VERSION "eCMP INFO-DIV vehicle review 2026-11-03; 125000 bit/s; PSA-RE 67f7581e7622410efdbb29c7eda3b86982b9b450; Apache-2.0"

NS_ :

BS_:

BU_: AAS AMPLI AVP BCM BGP BSG BSI BTA BTEL BTT CDC CMB CRT DIAG_TOOL EDP_C EMF FMUX IC ICSV IDVR IVC_D MATT MDS OVIP PDS_C RAD RBG SDCM VTH WLC

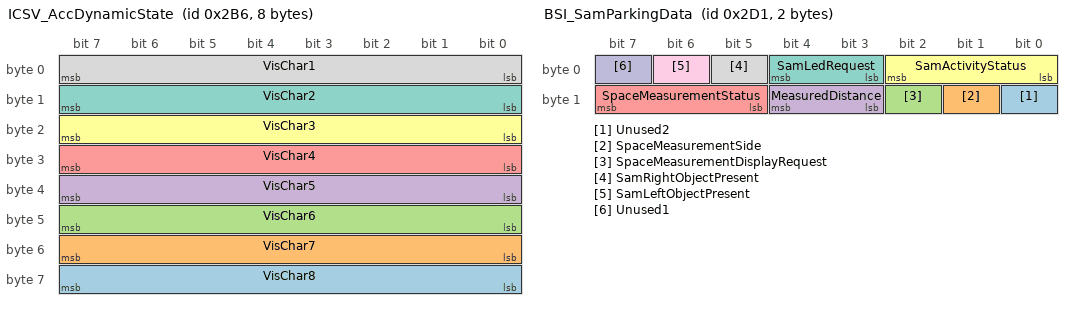
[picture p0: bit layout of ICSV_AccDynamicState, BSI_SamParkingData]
BO_ 694 ICSV_AccDynamicState: 8 ICSV
 SG_ VisChar8 : 63|8@0+ (1,0) [0|255] "raw"  BTEL,EMF,RAD,MDS,BGP,OVIP
 SG_ VisChar7 : 55|8@0+ (1,0) [0|255] "raw"  BTEL,EMF,RAD,MDS,BGP,OVIP
 SG_ VisChar6 : 47|8@0+ (1,0) [0|255] "raw"  BTEL,EMF,RAD,MDS,BGP,OVIP
 SG_ VisChar5 : 39|8@0+ (1,0) [0|255] "raw"  BTEL,EMF,RAD,MDS,BGP,OVIP
 SG_ VisChar4 : 31|8@0+ (1,0) [0|255] "raw"  BTEL,EMF,RAD,MDS,BGP,OVIP
 SG_ VisChar3 : 23|8@0+ (1,0) [0|255] "raw"  BTEL,EMF,RAD,MDS,BGP,OVIP
 SG_ VisChar2 : 15|8@0+ (1,0) [0|255] "raw"  BTEL,EMF,RAD,MDS,BGP,OVIP
 SG_ VisChar1 : 7|8@0+ (1,0) [0|255] "raw"  BTEL,EMF,RAD,MDS,BGP,OVIP

BO_ 705 BSI_UidTableEncryptedToBs_a09225: 8 BSI
 SG_ FlowPadding5 m3 : 63|8@0+ (1,0) [0|255] "raw"  SDCM
 SG_ FirstData6 m1 : 63|8@0+ (1,0) [0|255] "raw"  SDCM
 SG_ UnknownData7 m4 : 63|8@0+ (1,0) [0|255] "raw"  SDCM
 SG_ ConsecutiveData7 m2 : 63|8@0+ (1,0) [0|255] "raw"  SDCM
 SG_ SingleData7 m0 : 63|8@0+ (1,0) [0|255] "raw"  SDCM
 SG_ FlowPadding4 m3 : 55|8@0+ (1,0) [0|255] "raw"  SDCM
 SG_ FirstData5 m1 : 55|8@0+ (1,0) [0|255] "raw"  SDCM
 SG_ UnknownData6 m4 : 55|8@0+ (1,0) [0|255] "raw"  SDCM
 SG_ ConsecutiveData6 m2 : 55|8@0+ (1,0) [0|255] "raw"  SDCM
 SG_ SingleData6 m0 : 55|8@0+ (1,0) [0|255] "raw"  SDCM
 SG_ FlowPadding3 m3 : 47|8@0+ (1,0) [0|255] "raw"  SDCM
 SG_ FirstData4 m1 : 47|8@0+ (1,0) [0|255] "raw"  SDCM
 SG_ UnknownData5 m4 : 47|8@0+ (1,0) [0|255] "raw"  SDCM
 SG_ ConsecutiveData5 m2 : 47|8@0+ (1,0) [0|255] "raw"  SDCM
 SG_ SingleData5 m0 : 47|8@0+ (1,0) [0|255] "raw"  SDCM
 SG_ FlowPadding2 m3 : 39|8@0+ (1,0) [0|255] "raw"  SDCM
 SG_ FirstData3 m1 : 39|8@0+ (1,0) [0|255] "raw"  SDCM
 SG_ UnknownData4 m4 : 39|8@0+ (1,0) [0|255] "raw"  SDCM
 SG_ ConsecutiveData4 m2 : 39|8@0+ (1,0) [0|255] "raw"  SDCM
 SG_ SingleData4 m0 : 39|8@0+ (1,0) [0|255] "raw"  SDCM
 SG_ FlowPadding1 m3 : 31|8@0+ (1,0) [0|255] "raw"  SDCM
 SG_ FirstData2 m1 : 31|8@0+ (1,0) [0|255] "raw"  SDCM
 SG_ UnknownData3 m4 : 31|8@0+ (1,0) [0|255] "raw"  SDCM
 SG_ ConsecutiveData3 m2 : 31|8@0+ (1,0) [0|255] "raw"  SDCM
 SG_ SingleData3 m0 : 31|8@0+ (1,0) [0|255] "raw"  SDCM
 SG_ FirstData1 m1 : 23|8@0+ (1,0) [0|255] "raw"  SDCM
 SG_ UnknownData2 m4 : 23|8@0+ (1,0) [0|255] "raw"  SDCM
 SG_ ConsecutiveData2 m2 : 23|8@0+ (1,0) [0|255] "raw"  SDCM
 SG_ SingleData2 m0 : 23|8@0+ (1,0) [0|255] "raw"  SDCM
 SG_ SeparationTimeRaw m3 : 23|8@0+ (1,0) [0|255] "raw"  SDCM
 SG_ UnknownData1 m4 : 15|8@0+ (1,0) [0|255] "raw"  SDCM
 SG_ ConsecutiveData1 m2 : 15|8@0+ (1,0) [0|255] "raw"  SDCM
 SG_ SingleData1 m0 : 15|8@0+ (1,0) [0|255] "raw"  SDCM
 SG_ BlockSize m3 : 15|8@0+ (1,0) [0|255] "raw"  SDCM
 SG_ UnknownPciLow m4 : 3|4@0+ (1,0) [0|15] "raw"  SDCM
 SG_ FlowStatus m3 : 3|4@0+ (1,0) [0|15] "raw"  SDCM
 SG_ ConsecutiveSequence m2 : 3|4@0+ (1,0) [0|15] "raw"  SDCM
 SG_ FirstFrameLength m1 : 3|12@0+ (1,0) [0|4095] "raw"  SDCM
 SG_ SingleFrameLength m0 : 3|4@0+ (1,0) [0|15] "raw"  SDCM
 SG_ IsoTpFrameType M : 7|4@0+ (1,0) [0|15] ""  SDCM

BO_ 707 BTEL_OdiBufferToTelematics: 8 BTEL
 SG_ OdiCenterstackToTelematicsBuffer : 7|64@0+ (1,0) [0|18446744073709551615] ""  MDS

BO_ 709 OVIP_DashcamListFlowControl: 8 OVIP
 SG_ FlowPadding5 m3 : 63|8@0+ (1,0) [0|255] "raw"  IDVR
 SG_ FirstData6 m1 : 63|8@0+ (1,0) [0|255] "raw"  IDVR
 SG_ UnknownData7 m4 : 63|8@0+ (1,0) [0|255] "raw"  IDVR
 SG_ ConsecutiveData7 m2 : 63|8@0+ (1,0) [0|255] "raw"  IDVR
 SG_ SingleData7 m0 : 63|8@0+ (1,0) [0|255] "raw"  IDVR
 SG_ FlowPadding4 m3 : 55|8@0+ (1,0) [0|255] "raw"  IDVR
 SG_ FirstData5 m1 : 55|8@0+ (1,0) [0|255] "raw"  IDVR
 SG_ UnknownData6 m4 : 55|8@0+ (1,0) [0|255] "raw"  IDVR
 SG_ ConsecutiveData6 m2 : 55|8@0+ (1,0) [0|255] "raw"  IDVR
 SG_ SingleData6 m0 : 55|8@0+ (1,0) [0|255] "raw"  IDVR
 SG_ FlowPadding3 m3 : 47|8@0+ (1,0) [0|255] "raw"  IDVR
 SG_ FirstData4 m1 : 47|8@0+ (1,0) [0|255] "raw"  IDVR
 SG_ UnknownData5 m4 : 47|8@0+ (1,0) [0|255] "raw"  IDVR
 SG_ ConsecutiveData5 m2 : 47|8@0+ (1,0) [0|255] "raw"  IDVR
 SG_ SingleData5 m0 : 47|8@0+ (1,0) [0|255] "raw"  IDVR
 SG_ FlowPadding2 m3 : 39|8@0+ (1,0) [0|255] "raw"  IDVR
 SG_ FirstData3 m1 : 39|8@0+ (1,0) [0|255] "raw"  IDVR
 SG_ UnknownData4 m4 : 39|8@0+ (1,0) [0|255] "raw"  IDVR
 SG_ ConsecutiveData4 m2 : 39|8@0+ (1,0) [0|255] "raw"  IDVR
 SG_ SingleData4 m0 : 39|8@0+ (1,0) [0|255] "raw"  IDVR
 SG_ FlowPadding1 m3 : 31|8@0+ (1,0) [0|255] "raw"  IDVR
 SG_ FirstData2 m1 : 31|8@0+ (1,0) [0|255] "raw"  IDVR
 SG_ UnknownData3 m4 : 31|8@0+ (1,0) [0|255] "raw"  IDVR
 SG_ ConsecutiveData3 m2 : 31|8@0+ (1,0) [0|255] "raw"  IDVR
 SG_ SingleData3 m0 : 31|8@0+ (1,0) [0|255] "raw"  IDVR
 SG_ FirstData1 m1 : 23|8@0+ (1,0) [0|255] "raw"  IDVR
 SG_ UnknownData2 m4 : 23|8@0+ (1,0) [0|255] "raw"  IDVR
 SG_ ConsecutiveData2 m2 : 23|8@0+ (1,0) [0|255] "raw"  IDVR
 SG_ SingleData2 m0 : 23|8@0+ (1,0) [0|255] "raw"  IDVR
 SG_ SeparationTimeRaw m3 : 23|8@0+ (1,0) [0|255] "raw"  IDVR
 SG_ UnknownData1 m4 : 15|8@0+ (1,0) [0|255] "raw"  IDVR
 SG_ ConsecutiveData1 m2 : 15|8@0+ (1,0) [0|255] "raw"  IDVR
 SG_ SingleData1 m0 : 15|8@0+ (1,0) [0|255] "raw"  IDVR
 SG_ BlockSize m3 : 15|8@0+ (1,0) [0|255] "raw"  IDVR
 SG_ UnknownPciLow m4 : 3|4@0+ (1,0) [0|15] "raw"  IDVR
 SG_ FlowStatus m3 : 3|4@0+ (1,0) [0|15] "raw"  IDVR
 SG_ ConsecutiveSequence m2 : 3|4@0+ (1,0) [0|15] "raw"  IDVR
 SG_ FirstFrameLength m1 : 3|12@0+ (1,0) [0|4095] "raw"  IDVR
 SG_ SingleFrameLength m0 : 3|4@0+ (1,0) [0|15] "raw"  IDVR
 SG_ IsoTpFrameType M : 7|4@0+ (1,0) [0|15] ""  IDVR

BO_ 721 BSI_SamParkingData: 2 BSI
 SG_ Unused2 : 8|1@0+ (1,0) [0|1] ""  AAS,MDS
 SG_ SpaceMeasurementSide : 9|1@0+ (1,0) [0|1] ""  AAS,MDS
 SG_ SpaceMeasurementDisplayRequest : 10|1@0+ (1,0) [0|1] ""  AAS,MDS
 SG_ MeasuredDistance : 12|2@0+ (1,0) [0|3] ""  AAS,MDS
 SG_ SpaceMeasurementStatus : 15|3@0+ (1,0) [0|7] ""  AAS,MDS
 SG_ SamActivityStatus : 2|3@0+ (1,0) [0|7] ""  AAS,MDS
 SG_ SamLedRequest : 4|2@0+ (1,0) [0|3] ""  AAS,MDS
 SG_ SamRightObjectPresent : 5|1@0+ (1,0) [0|1] ""  AAS,MDS
 SG_ SamLeftObjectPresent : 6|1@0+ (1,0) [0|1] ""  AAS,MDS
 SG_ Unused1 : 7|1@0+ (1,0) [0|1] ""  AAS,MDS

BO_ 724 BSI_RemoteActionMonitoringStatus: 8 BSI
 SG_ FlowPadding5 m3 : 63|8@0+ (1,0) [0|255] "raw"  MDS
 SG_ FirstData6 m1 : 63|8@0+ (1,0) [0|255] "raw"  MDS
 SG_ UnknownData7 m4 : 63|8@0+ (1,0) [0|255] "raw"  MDS
 SG_ ConsecutiveData7 m2 : 63|8@0+ (1,0) [0|255] "raw"  MDS
 SG_ SingleData7 m0 : 63|8@0+ (1,0) [0|255] "raw"  MDS
 SG_ FlowPadding4 m3 : 55|8@0+ (1,0) [0|255] "raw"  MDS
 SG_ FirstData5 m1 : 55|8@0+ (1,0) [0|255] "raw"  MDS
 SG_ UnknownData6 m4 : 55|8@0+ (1,0) [0|255] "raw"  MDS
 SG_ ConsecutiveData6 m2 : 55|8@0+ (1,0) [0|255] "raw"  MDS
 SG_ SingleData6 m0 : 55|8@0+ (1,0) [0|255] "raw"  MDS
 SG_ FlowPadding3 m3 : 47|8@0+ (1,0) [0|255] "raw"  MDS
 SG_ FirstData4 m1 : 47|8@0+ (1,0) [0|255] "raw"  MDS
 SG_ UnknownData5 m4 : 47|8@0+ (1,0) [0|255] "raw"  MDS
 SG_ ConsecutiveData5 m2 : 47|8@0+ (1,0) [0|255] "raw"  MDS
 SG_ SingleData5 m0 : 47|8@0+ (1,0) [0|255] "raw"  MDS
 SG_ FlowPadding2 m3 : 39|8@0+ (1,0) [0|255] "raw"  MDS
 SG_ FirstData3 m1 : 39|8@0+ (1,0) [0|255] "raw"  MDS
 SG_ UnknownData4 m4 : 39|8@0+ (1,0) [0|255] "raw"  MDS
 SG_ ConsecutiveData4 m2 : 39|8@0+ (1,0) [0|255] "raw"  MDS
 SG_ SingleData4 m0 : 39|8@0+ (1,0) [0|255] "raw"  MDS
 SG_ FlowPadding1 m3 : 31|8@0+ (1,0) [0|255] "raw"  MDS
 SG_ FirstData2 m1 : 31|8@0+ (1,0) [0|255] "raw"  MDS
 SG_ UnknownData3 m4 : 31|8@0+ (1,0) [0|255] "raw"  MDS
 SG_ ConsecutiveData3 m2 : 31|8@0+ (1,0) [0|255] "raw"  MDS
 SG_ SingleData3 m0 : 31|8@0+ (1,0) [0|255] "raw"  MDS
 SG_ FirstData1 m1 : 23|8@0+ (1,0) [0|255] "raw"  MDS
 SG_ UnknownData2 m4 : 23|8@0+ (1,0) [0|255] "raw"  MDS
 SG_ ConsecutiveData2 m2 : 23|8@0+ (1,0) [0|255] "raw"  MDS
 SG_ SingleData2 m0 : 23|8@0+ (1,0) [0|255] "raw"  MDS
 SG_ SeparationTimeRaw m3 : 23|8@0+ (1,0) [0|255] "raw"  MDS
 SG_ UnknownData1 m4 : 15|8@0+ (1,0) [0|255] "raw"  MDS
 SG_ ConsecutiveData1 m2 : 15|8@0+ (1,0) [0|255] "raw"  MDS
 SG_ SingleData1 m0 : 15|8@0+ (1,0) [0|255] "raw"  MDS
 SG_ BlockSize m3 : 15|8@0+ (1,0) [0|255] "raw"  MDS
 SG_ UnknownPciLow m4 : 3|4@0+ (1,0) [0|15] "raw"  MDS
 SG_ FlowStatus m3 : 3|4@0+ (1,0) [0|15] "raw"  MDS
 SG_ ConsecutiveSequence m2 : 3|4@0+ (1,0) [0|15] "raw"  MDS
 SG_ FirstFrameLength m1 : 3|12@0+ (1,0) [0|4095] "raw"  MDS
 SG_ SingleFrameLength m0 : 3|4@0+ (1,0) [0|15] "raw"  MDS
 SG_ IsoTpFrameType M : 7|4@0+ (1,0) [0|15] ""  MDS

BO_ 727 IC_ClusterSettingsStatus: 3 IC
 SG_ Unused1 : 17|2@0+ (1,0) [0|3] ""  ICSV,BSI,BTEL,OVIP,RAD
 SG_ EcoachFieldAvailable : 18|1@0+ (1,0) [0|1] ""  ICSV,BSI,BTEL,OVIP,RAD
 SG_ DaaFieldAvailable : 19|1@0+ (1,0) [0|1] ""  ICSV,BSI,BTEL,OVIP,RAD
 SG_ TripComputerFieldAvailable : 20|1@0+ (1,0) [0|1] ""  ICSV,BSI,BTEL,OVIP,RAD
 SG_ LightNavExportFieldAvailable : 21|1@0+ (1,0) [0|1] ""  ICSV,BSI,BTEL,OVIP,RAD
 SG_ FullNavExportFieldAvailable : 22|1@0+ (1,0) [0|1] ""  ICSV,BSI,BTEL,OVIP,RAD
 SG_ LightMediaExportFieldAvailable : 23|1@0+ (1,0) [0|1] ""  ICSV,BSI,BTEL,OVIP,RAD
 SG_ FullMediaExportFieldAvailable : 8|1@0+ (1,0) [0|1] ""  ICSV,BSI,BTEL,OVIP,RAD
 SG_ PowermeterFieldAvailable : 9|1@0+ (1,0) [0|1] ""  ICSV,BSI,BTEL,OVIP,RAD
 SG_ HybridFlowFieldAvailable : 10|1@0+ (1,0) [0|1] ""  ICSV,BSI,BTEL,OVIP,RAD
 SG_ TempGaugesFieldAvailable : 11|1@0+ (1,0) [0|1] ""  ICSV,BSI,BTEL,OVIP,RAD
 SG_ GMeterFieldAvailable : 12|1@0+ (1,0) [0|1] ""  ICSV,BSI,BTEL,OVIP,RAD
 SG_ PowerGaugeFieldAvailable : 13|1@0+ (1,0) [0|1] ""  ICSV,BSI,BTEL,OVIP,RAD
 SG_ StyleDecorFieldAvailable : 14|1@0+ (1,0) [0|1] ""  ICSV,BSI,BTEL,OVIP,RAD
 SG_ AdasFieldAvailable : 15|1@0+ (1,0) [0|1] ""  ICSV,BSI,BTEL,OVIP,RAD
 SG_ TachometerFieldAvailable : 0|1@0+ (1,0) [0|1] ""  ICSV,BSI,BTEL,OVIP,RAD
 SG_ CustomImageFieldAvailable : 1|1@0+ (1,0) [0|1] ""  ICSV,BSI,BTEL,OVIP,RAD
 SG_ LvdsVideoFormat : 3|2@0+ (1,0) [0|3] ""  ICSV,BSI,BTEL,OVIP,RAD
 SG_ TivSettingsPageOpen : 4|1@0+ (1,0) [0|1] ""  ICSV,BSI,BTEL,OVIP,RAD
 SG_ NavDatabaseLoading : 5|1@0+ (1,0) [0|1] ""  ICSV,BSI,BTEL,OVIP,RAD
 SG_ ImageStorageStatus : 7|2@0+ (1,0) [0|3] ""  ICSV,BSI,BTEL,OVIP,RAD

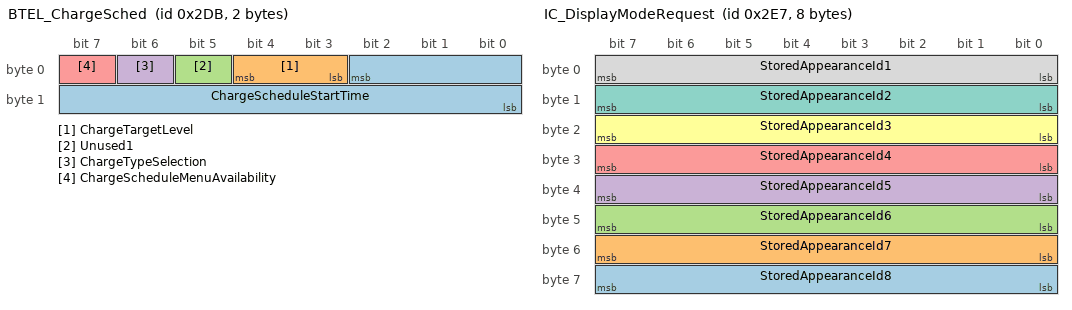
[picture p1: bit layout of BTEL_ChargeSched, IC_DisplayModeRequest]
BO_ 731 BTEL_ChargeSched: 2 BTEL
 SG_ ChargeScheduleStartTime : 2|11@0+ (1,0) [0|1440] "min"  BSI
 SG_ ChargeTargetLevel : 4|2@0+ (1,0) [0|3] ""  BSI
 SG_ Unused1 : 5|1@0+ (1,0) [0|1] ""  BSI
 SG_ ChargeTypeSelection : 6|1@0+ (1,0) [0|1] ""  BSI
 SG_ ChargeScheduleMenuAvailability : 7|1@0+ (1,0) [0|1] ""  BSI

BO_ 732 ICSV_AudioExportFlowControl: 8 ICSV
 SG_ FlowPadding5 m3 : 63|8@0+ (1,0) [0|255] "raw"  BTEL,EMF,OVIP,RAD
 SG_ FirstData6 m1 : 63|8@0+ (1,0) [0|255] "raw"  BTEL,EMF,OVIP,RAD
 SG_ UnknownData7 m4 : 63|8@0+ (1,0) [0|255] "raw"  BTEL,EMF,OVIP,RAD
 SG_ ConsecutiveData7 m2 : 63|8@0+ (1,0) [0|255] "raw"  BTEL,EMF,OVIP,RAD
 SG_ SingleData7 m0 : 63|8@0+ (1,0) [0|255] "raw"  BTEL,EMF,OVIP,RAD
 SG_ FlowPadding4 m3 : 55|8@0+ (1,0) [0|255] "raw"  BTEL,EMF,OVIP,RAD
 SG_ FirstData5 m1 : 55|8@0+ (1,0) [0|255] "raw"  BTEL,EMF,OVIP,RAD
 SG_ UnknownData6 m4 : 55|8@0+ (1,0) [0|255] "raw"  BTEL,EMF,OVIP,RAD
 SG_ ConsecutiveData6 m2 : 55|8@0+ (1,0) [0|255] "raw"  BTEL,EMF,OVIP,RAD
 SG_ SingleData6 m0 : 55|8@0+ (1,0) [0|255] "raw"  BTEL,EMF,OVIP,RAD
 SG_ FlowPadding3 m3 : 47|8@0+ (1,0) [0|255] "raw"  BTEL,EMF,OVIP,RAD
 SG_ FirstData4 m1 : 47|8@0+ (1,0) [0|255] "raw"  BTEL,EMF,OVIP,RAD
 SG_ UnknownData5 m4 : 47|8@0+ (1,0) [0|255] "raw"  BTEL,EMF,OVIP,RAD
 SG_ ConsecutiveData5 m2 : 47|8@0+ (1,0) [0|255] "raw"  BTEL,EMF,OVIP,RAD
 SG_ SingleData5 m0 : 47|8@0+ (1,0) [0|255] "raw"  BTEL,EMF,OVIP,RAD
 SG_ FlowPadding2 m3 : 39|8@0+ (1,0) [0|255] "raw"  BTEL,EMF,OVIP,RAD
 SG_ FirstData3 m1 : 39|8@0+ (1,0) [0|255] "raw"  BTEL,EMF,OVIP,RAD
 SG_ UnknownData4 m4 : 39|8@0+ (1,0) [0|255] "raw"  BTEL,EMF,OVIP,RAD
 SG_ ConsecutiveData4 m2 : 39|8@0+ (1,0) [0|255] "raw"  BTEL,EMF,OVIP,RAD
 SG_ SingleData4 m0 : 39|8@0+ (1,0) [0|255] "raw"  BTEL,EMF,OVIP,RAD
 SG_ FlowPadding1 m3 : 31|8@0+ (1,0) [0|255] "raw"  BTEL,EMF,OVIP,RAD
 SG_ FirstData2 m1 : 31|8@0+ (1,0) [0|255] "raw"  BTEL,EMF,OVIP,RAD
 SG_ UnknownData3 m4 : 31|8@0+ (1,0) [0|255] "raw"  BTEL,EMF,OVIP,RAD
 SG_ ConsecutiveData3 m2 : 31|8@0+ (1,0) [0|255] "raw"  BTEL,EMF,OVIP,RAD
 SG_ SingleData3 m0 : 31|8@0+ (1,0) [0|255] "raw"  BTEL,EMF,OVIP,RAD
 SG_ FirstData1 m1 : 23|8@0+ (1,0) [0|255] "raw"  BTEL,EMF,OVIP,RAD
 SG_ UnknownData2 m4 : 23|8@0+ (1,0) [0|255] "raw"  BTEL,EMF,OVIP,RAD
 SG_ ConsecutiveData2 m2 : 23|8@0+ (1,0) [0|255] "raw"  BTEL,EMF,OVIP,RAD
 SG_ SingleData2 m0 : 23|8@0+ (1,0) [0|255] "raw"  BTEL,EMF,OVIP,RAD
 SG_ SeparationTimeRaw m3 : 23|8@0+ (1,0) [0|255] "raw"  BTEL,EMF,OVIP,RAD
 SG_ UnknownData1 m4 : 15|8@0+ (1,0) [0|255] "raw"  BTEL,EMF,OVIP,RAD
 SG_ ConsecutiveData1 m2 : 15|8@0+ (1,0) [0|255] "raw"  BTEL,EMF,OVIP,RAD
 SG_ SingleData1 m0 : 15|8@0+ (1,0) [0|255] "raw"  BTEL,EMF,OVIP,RAD
 SG_ BlockSize m3 : 15|8@0+ (1,0) [0|255] "raw"  BTEL,EMF,OVIP,RAD
 SG_ UnknownPciLow m4 : 3|4@0+ (1,0) [0|15] "raw"  BTEL,EMF,OVIP,RAD
 SG_ FlowStatus m3 : 3|4@0+ (1,0) [0|15] "raw"  BTEL,EMF,OVIP,RAD
 SG_ ConsecutiveSequence m2 : 3|4@0+ (1,0) [0|15] "raw"  BTEL,EMF,OVIP,RAD
 SG_ FirstFrameLength m1 : 3|12@0+ (1,0) [0|4095] "raw"  BTEL,EMF,OVIP,RAD
 SG_ SingleFrameLength m0 : 3|4@0+ (1,0) [0|15] "raw"  BTEL,EMF,OVIP,RAD
 SG_ IsoTpFrameType M : 7|4@0+ (1,0) [0|15] ""  BTEL,EMF,OVIP,RAD

BO_ 735 EMF_Phone: 8 EMF
 SG_ FlowPadding5 m3 : 63|8@0+ (1,0) [0|255] "raw"  RAD
 SG_ FirstData6 m1 : 63|8@0+ (1,0) [0|255] "raw"  RAD
 SG_ UnknownData7 m4 : 63|8@0+ (1,0) [0|255] "raw"  RAD
 SG_ ConsecutiveData7 m2 : 63|8@0+ (1,0) [0|255] "raw"  RAD
 SG_ SingleData7 m0 : 63|8@0+ (1,0) [0|255] "raw"  RAD
 SG_ FlowPadding4 m3 : 55|8@0+ (1,0) [0|255] "raw"  RAD
 SG_ FirstData5 m1 : 55|8@0+ (1,0) [0|255] "raw"  RAD
 SG_ UnknownData6 m4 : 55|8@0+ (1,0) [0|255] "raw"  RAD
 SG_ ConsecutiveData6 m2 : 55|8@0+ (1,0) [0|255] "raw"  RAD
 SG_ SingleData6 m0 : 55|8@0+ (1,0) [0|255] "raw"  RAD
 SG_ FlowPadding3 m3 : 47|8@0+ (1,0) [0|255] "raw"  RAD
 SG_ FirstData4 m1 : 47|8@0+ (1,0) [0|255] "raw"  RAD
 SG_ UnknownData5 m4 : 47|8@0+ (1,0) [0|255] "raw"  RAD
 SG_ ConsecutiveData5 m2 : 47|8@0+ (1,0) [0|255] "raw"  RAD
 SG_ SingleData5 m0 : 47|8@0+ (1,0) [0|255] "raw"  RAD
 SG_ FlowPadding2 m3 : 39|8@0+ (1,0) [0|255] "raw"  RAD
 SG_ FirstData3 m1 : 39|8@0+ (1,0) [0|255] "raw"  RAD
 SG_ UnknownData4 m4 : 39|8@0+ (1,0) [0|255] "raw"  RAD
 SG_ ConsecutiveData4 m2 : 39|8@0+ (1,0) [0|255] "raw"  RAD
 SG_ SingleData4 m0 : 39|8@0+ (1,0) [0|255] "raw"  RAD
 SG_ FlowPadding1 m3 : 31|8@0+ (1,0) [0|255] "raw"  RAD
 SG_ FirstData2 m1 : 31|8@0+ (1,0) [0|255] "raw"  RAD
 SG_ UnknownData3 m4 : 31|8@0+ (1,0) [0|255] "raw"  RAD
 SG_ ConsecutiveData3 m2 : 31|8@0+ (1,0) [0|255] "raw"  RAD
 SG_ SingleData3 m0 : 31|8@0+ (1,0) [0|255] "raw"  RAD
 SG_ FirstData1 m1 : 23|8@0+ (1,0) [0|255] "raw"  RAD
 SG_ UnknownData2 m4 : 23|8@0+ (1,0) [0|255] "raw"  RAD
 SG_ ConsecutiveData2 m2 : 23|8@0+ (1,0) [0|255] "raw"  RAD
 SG_ SingleData2 m0 : 23|8@0+ (1,0) [0|255] "raw"  RAD
 SG_ SeparationTimeRaw m3 : 23|8@0+ (1,0) [0|255] "raw"  RAD
 SG_ UnknownData1 m4 : 15|8@0+ (1,0) [0|255] "raw"  RAD
 SG_ ConsecutiveData1 m2 : 15|8@0+ (1,0) [0|255] "raw"  RAD
 SG_ SingleData1 m0 : 15|8@0+ (1,0) [0|255] "raw"  RAD
 SG_ BlockSize m3 : 15|8@0+ (1,0) [0|255] "raw"  RAD
 SG_ UnknownPciLow m4 : 3|4@0+ (1,0) [0|15] "raw"  RAD
 SG_ FlowStatus m3 : 3|4@0+ (1,0) [0|15] "raw"  RAD
 SG_ ConsecutiveSequence m2 : 3|4@0+ (1,0) [0|15] "raw"  RAD
 SG_ FirstFrameLength m1 : 3|12@0+ (1,0) [0|4095] "raw"  RAD
 SG_ SingleFrameLength m0 : 3|4@0+ (1,0) [0|15] "raw"  RAD
 SG_ IsoTpFrameType M : 7|4@0+ (1,0) [0|15] ""  RAD

BO_ 736 BSI_ClimatePrecondSchedule: 7 BSI
 SG_ AcPrecondSchedule2StartTime : 42|11@0+ (1,0) [0|1440] "min"  MDS,BTEL,OVIP
 SG_ Unused3 : 47|5@0+ (1,0) [0|31] ""  MDS,BTEL,OVIP
 SG_ AcPrecondSundaySchedule2Active : 32|1@0+ (1,0) [0|1] ""  MDS,BTEL,OVIP
 SG_ AcPrecondSaturdaySchedule2Active : 33|1@0+ (1,0) [0|1] ""  MDS,BTEL,OVIP
 SG_ AcPrecondFridaySchedule2Active : 34|1@0+ (1,0) [0|1] ""  MDS,BTEL,OVIP
 SG_ AcPrecondThursdaySchedule2Active : 35|1@0+ (1,0) [0|1] ""  MDS,BTEL,OVIP
 SG_ AcPrecondWednesdaySchedul_14303b : 36|1@0+ (1,0) [0|1] ""  MDS,BTEL,OVIP
 SG_ AcPrecondTuesdaySchedule2Active : 37|1@0+ (1,0) [0|1] ""  MDS,BTEL,OVIP
 SG_ AcPrecondMondaySchedule2Active : 38|1@0+ (1,0) [0|1] ""  MDS,BTEL,OVIP
 SG_ AcPrecondSchedule2Enabled : 39|1@0+ (1,0) [0|1] ""  MDS,BTEL,OVIP
 SG_ AcPrecondSchedule1StartTime : 18|11@0+ (1,0) [0|1440] "min"  MDS,BTEL,OVIP
 SG_ Unused2 : 23|5@0+ (1,0) [0|31] ""  MDS,BTEL,OVIP
 SG_ AcPrecondSundaySchedule1Active : 8|1@0+ (1,0) [0|1] ""  MDS,BTEL,OVIP
 SG_ AcPrecondSaturdaySchedule1Active : 9|1@0+ (1,0) [0|1] ""  MDS,BTEL,OVIP
 SG_ AcPrecondFridaySchedule1Active : 10|1@0+ (1,0) [0|1] ""  MDS,BTEL,OVIP
 SG_ AcPrecondThursdaySchedule1Active : 11|1@0+ (1,0) [0|1] ""  MDS,BTEL,OVIP
 SG_ AcPrecondWednesdaySchedul_0079d6 : 12|1@0+ (1,0) [0|1] ""  MDS,BTEL,OVIP
 SG_ AcPrecondTuesdaySchedule1Active : 13|1@0+ (1,0) [0|1] ""  MDS,BTEL,OVIP
 SG_ AcPrecondMondaySchedule1Active : 14|1@0+ (1,0) [0|1] ""  MDS,BTEL,OVIP
 SG_ AcPrecondSchedule1Enabled : 15|1@0+ (1,0) [0|1] ""  MDS,BTEL,OVIP
 SG_ Unused1 : 1|2@0+ (1,0) [0|3] ""  MDS,BTEL,OVIP
 SG_ AcPrecondAsapModeActive : 2|1@0+ (1,0) [0|1] ""  MDS,BTEL,OVIP
 SG_ AcPrecondStatusFeedback : 6|4@0+ (1,0) [0|15] ""  MDS,BTEL,OVIP
 SG_ AcPrecondStatusAvailability : 7|1@0+ (1,0) [0|1] ""  MDS,BTEL,OVIP

BO_ 737 BSI_VehicleFunctionConfig: 6 BSI
 SG_ Unused2 : 43|4@0+ (1,0) [0|15] ""  ICSV,BTEL,EMF,OVIP,RAD
 SG_ AsrPAvailability : 44|1@0+ (1,0) [0|1] ""  ICSV,BTEL,EMF,OVIP,RAD
 SG_ RetractableRoofState : 47|3@0+ (1,0) [0|7] ""  ICSV,BTEL,EMF,OVIP,RAD
 SG_ Unused1 : 32|1@0+ (1,0) [0|1] ""  ICSV,BTEL,EMF,OVIP,RAD
 SG_ AsrPlusMode : 35|3@0+ (1,0) [0|7] ""  ICSV,BTEL,EMF,OVIP,RAD
 SG_ SuspensionAlert : 36|1@0+ (1,0) [0|1] ""  ICSV,BTEL,EMF,OVIP,RAD
 SG_ RealSuspensionPosition : 39|3@0+ (1,0) [0|7] ""  ICSV,BTEL,EMF,OVIP,RAD
 SG_ SuspensionMovement : 25|2@0+ (1,0) [0|3] ""  ICSV,BTEL,EMF,OVIP,RAD
 SG_ FinalSuspensionPosition : 28|3@0+ (1,0) [0|7] ""  ICSV,BTEL,EMF,OVIP,RAD
 SG_ InitialSuspensionPosition : 31|3@0+ (1,0) [0|7] ""  ICSV,BTEL,EMF,OVIP,RAD
 SG_ PushStartStopStatus : 16|1@0+ (1,0) [0|1] ""  ICSV,BTEL,EMF,OVIP,RAD
 SG_ TrunkAndConvertibleRoofStatus : 19|3@0+ (1,0) [0|7] ""  ICSV,BTEL,EMF,OVIP,RAD
 SG_ StopStartStatus : 21|2@0+ (1,0) [0|3] ""  ICSV,BTEL,EMF,OVIP,RAD
 SG_ ChildSafetyRearDoorsStatus : 23|2@0+ (1,0) [0|3] ""  ICSV,BTEL,EMF,OVIP,RAD
 SG_ SuspensionMode : 9|2@0+ (1,0) [0|3] ""  ICSV,BTEL,EMF,OVIP,RAD
 SG_ AutomaticWipingStatus : 11|2@0+ (1,0) [0|3] ""  ICSV,BTEL,EMF,OVIP,RAD
 SG_ EspStatus : 13|2@0+ (1,0) [0|3] ""  ICSV,BTEL,EMF,OVIP,RAD
 SG_ DoorLockingStatus : 15|2@0+ (1,0) [0|3] ""  ICSV,BTEL,EMF,OVIP,RAD
 SG_ AutomaticDoorLockingStatus : 1|2@0+ (1,0) [0|3] ""  ICSV,BTEL,EMF,OVIP,RAD
 SG_ AutomaticHeadlightsStatus : 3|2@0+ (1,0) [0|3] ""  ICSV,BTEL,EMF,OVIP,RAD
 SG_ PassengerAirbagStatus : 5|2@0+ (1,0) [0|3] ""  ICSV,BTEL,EMF,OVIP,RAD
 SG_ ParkingAidStatus : 7|2@0+ (1,0) [0|3] ""  ICSV,BTEL,EMF,OVIP,RAD

BO_ 743 IC_DisplayModeRequest: 8 IC
 SG_ StoredAppearanceId8 : 63|8@0+ (1,0) [0|255] ""  BTEL,OVIP,RAD
 SG_ StoredAppearanceId7 : 55|8@0+ (1,0) [0|255] ""  BTEL,OVIP,RAD
 SG_ StoredAppearanceId6 : 47|8@0+ (1,0) [0|255] ""  BTEL,OVIP,RAD
 SG_ StoredAppearanceId5 : 39|8@0+ (1,0) [0|255] ""  BTEL,OVIP,RAD
 SG_ StoredAppearanceId4 : 31|8@0+ (1,0) [0|255] ""  BTEL,OVIP,RAD
 SG_ StoredAppearanceId3 : 23|8@0+ (1,0) [0|255] ""  BTEL,OVIP,RAD
 SG_ StoredAppearanceId2 : 15|8@0+ (1,0) [0|255] ""  BTEL,OVIP,RAD
 SG_ StoredAppearanceId1 : 7|8@0+ (1,0) [0|255] ""  BTEL,OVIP,RAD

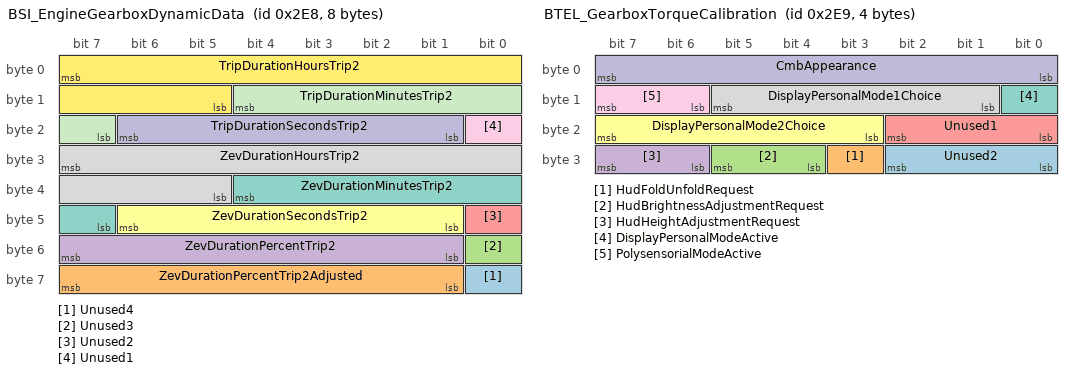
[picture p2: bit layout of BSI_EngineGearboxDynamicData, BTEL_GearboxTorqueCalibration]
BO_ 744 BSI_EngineGearboxDynamicData: 8 BSI
 SG_ Unused4 : 56|1@0+ (1,0) [0|1] ""  OVIP,RAD
 SG_ ZevDurationPercentTrip2Adjusted : 63|7@0+ (1,0) [0|100] "%"  OVIP,RAD
 SG_ Unused3 : 48|1@0+ (1,0) [0|1] ""  OVIP,RAD
 SG_ ZevDurationPercentTrip2 : 55|7@0+ (1,0) [0|100] "%"  OVIP,RAD
 SG_ Unused2 : 40|1@0+ (1,0) [0|1] ""  OVIP,RAD
 SG_ ZevDurationSecondsTrip2 : 46|6@0+ (1,0) [0|59] "s"  OVIP,RAD
 SG_ ZevDurationMinutesTrip2 : 36|6@0+ (1,0) [0|59] "min"  OVIP,RAD
 SG_ ZevDurationHoursTrip2 : 31|11@0+ (1,0) [0|2000] "h"  OVIP,RAD
 SG_ Unused1 : 16|1@0+ (1,0) [0|1] ""  OVIP,RAD
 SG_ TripDurationSecondsTrip2 : 22|6@0+ (1,0) [0|59] "s"  OVIP,RAD
 SG_ TripDurationMinutesTrip2 : 12|6@0+ (1,0) [0|59] "min"  OVIP,RAD
 SG_ TripDurationHoursTrip2 : 7|11@0+ (1,0) [0|2000] "h"  OVIP,RAD

BO_ 745 BTEL_GearboxTorqueCalibration: 4 BTEL
 SG_ Unused2 : 26|3@0+ (1,0) [0|7] ""  ICSV,CMB
 SG_ HudFoldUnfoldRequest : 27|1@0+ (1,0) [0|1] ""  ICSV,CMB
 SG_ HudBrightnessAdjustmentRequest : 29|2@0+ (1,0) [0|3] ""  ICSV,CMB
 SG_ HudHeightAdjustmentRequest : 31|2@0+ (1,0) [0|3] ""  ICSV,CMB
 SG_ Unused1 : 18|3@0+ (1,0) [0|7] ""  ICSV,CMB
 SG_ DisplayPersonalMode2Choice : 23|5@0+ (1,0) [0|31] ""  ICSV,CMB
 SG_ DisplayPersonalModeActive : 8|1@0+ (1,0) [0|1] ""  ICSV,CMB
 SG_ DisplayPersonalMode1Choice : 13|5@0+ (1,0) [0|31] ""  ICSV,CMB
 SG_ PolysensorialModeActive : 15|2@0+ (1,0) [0|3] ""  ICSV,CMB
 SG_ CmbAppearance : 7|8@0+ (1,0) [1|254] ""  ICSV,CMB

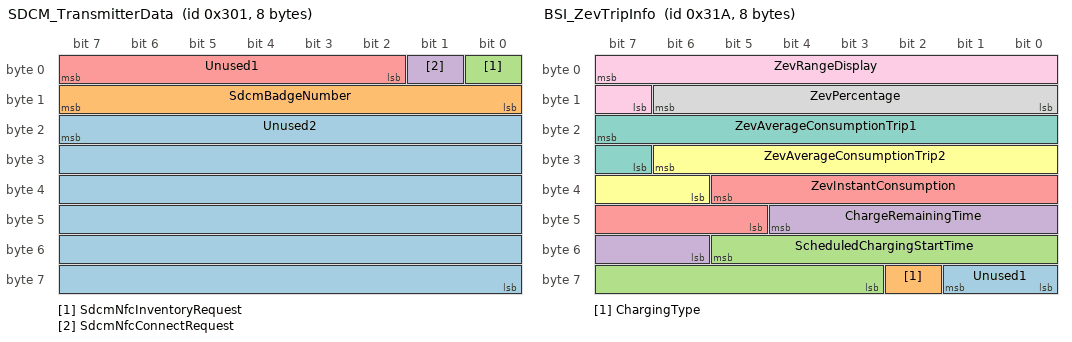
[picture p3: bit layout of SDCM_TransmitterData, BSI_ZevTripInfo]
BO_ 769 SDCM_TransmitterData: 8 SDCM
 SG_ Unused2 : 23|48@0+ (1,0) [0|281474976710655] ""  WLC
 SG_ SdcmBadgeNumber : 15|8@0+ (1,0) [0|255] ""  WLC
 SG_ SdcmNfcInventoryRequest : 0|1@0+ (1,0) [0|1] ""  WLC
 SG_ SdcmNfcConnectRequest : 1|1@0+ (1,0) [0|1] ""  WLC
 SG_ Unused1 : 7|6@0+ (1,0) [0|63] ""  WLC

BO_ 771 BTEL_OdiActionBuffer: 8 BTEL
 SG_ OdiActionCenterstackBuffer : 7|64@0+ (1,0) [0|18446744073709551615] ""  MDS

BO_ 773 IDVR_SteeringWheelAngle: 8 IDVR
 SG_ FlowPadding5 m3 : 63|8@0+ (1,0) [0|255] "raw"  BTEL,OVIP
 SG_ FirstData6 m1 : 63|8@0+ (1,0) [0|255] "raw"  BTEL,OVIP
 SG_ UnknownData7 m4 : 63|8@0+ (1,0) [0|255] "raw"  BTEL,OVIP
 SG_ ConsecutiveData7 m2 : 63|8@0+ (1,0) [0|255] "raw"  BTEL,OVIP
 SG_ SingleData7 m0 : 63|8@0+ (1,0) [0|255] "raw"  BTEL,OVIP
 SG_ FlowPadding4 m3 : 55|8@0+ (1,0) [0|255] "raw"  BTEL,OVIP
 SG_ FirstData5 m1 : 55|8@0+ (1,0) [0|255] "raw"  BTEL,OVIP
 SG_ UnknownData6 m4 : 55|8@0+ (1,0) [0|255] "raw"  BTEL,OVIP
 SG_ ConsecutiveData6 m2 : 55|8@0+ (1,0) [0|255] "raw"  BTEL,OVIP
 SG_ SingleData6 m0 : 55|8@0+ (1,0) [0|255] "raw"  BTEL,OVIP
 SG_ FlowPadding3 m3 : 47|8@0+ (1,0) [0|255] "raw"  BTEL,OVIP
 SG_ FirstData4 m1 : 47|8@0+ (1,0) [0|255] "raw"  BTEL,OVIP
 SG_ UnknownData5 m4 : 47|8@0+ (1,0) [0|255] "raw"  BTEL,OVIP
 SG_ ConsecutiveData5 m2 : 47|8@0+ (1,0) [0|255] "raw"  BTEL,OVIP
 SG_ SingleData5 m0 : 47|8@0+ (1,0) [0|255] "raw"  BTEL,OVIP
 SG_ FlowPadding2 m3 : 39|8@0+ (1,0) [0|255] "raw"  BTEL,OVIP
 SG_ FirstData3 m1 : 39|8@0+ (1,0) [0|255] "raw"  BTEL,OVIP
 SG_ UnknownData4 m4 : 39|8@0+ (1,0) [0|255] "raw"  BTEL,OVIP
 SG_ ConsecutiveData4 m2 : 39|8@0+ (1,0) [0|255] "raw"  BTEL,OVIP
 SG_ SingleData4 m0 : 39|8@0+ (1,0) [0|255] "raw"  BTEL,OVIP
 SG_ FlowPadding1 m3 : 31|8@0+ (1,0) [0|255] "raw"  BTEL,OVIP
 SG_ FirstData2 m1 : 31|8@0+ (1,0) [0|255] "raw"  BTEL,OVIP
 SG_ UnknownData3 m4 : 31|8@0+ (1,0) [0|255] "raw"  BTEL,OVIP
 SG_ ConsecutiveData3 m2 : 31|8@0+ (1,0) [0|255] "raw"  BTEL,OVIP
 SG_ SingleData3 m0 : 31|8@0+ (1,0) [0|255] "raw"  BTEL,OVIP
 SG_ FirstData1 m1 : 23|8@0+ (1,0) [0|255] "raw"  BTEL,OVIP
 SG_ UnknownData2 m4 : 23|8@0+ (1,0) [0|255] "raw"  BTEL,OVIP
 SG_ ConsecutiveData2 m2 : 23|8@0+ (1,0) [0|255] "raw"  BTEL,OVIP
 SG_ SingleData2 m0 : 23|8@0+ (1,0) [0|255] "raw"  BTEL,OVIP
 SG_ SeparationTimeRaw m3 : 23|8@0+ (1,0) [0|255] "raw"  BTEL,OVIP
 SG_ UnknownData1 m4 : 15|8@0+ (1,0) [0|255] "raw"  BTEL,OVIP
 SG_ ConsecutiveData1 m2 : 15|8@0+ (1,0) [0|255] "raw"  BTEL,OVIP
 SG_ SingleData1 m0 : 15|8@0+ (1,0) [0|255] "raw"  BTEL,OVIP
 SG_ BlockSize m3 : 15|8@0+ (1,0) [0|255] "raw"  BTEL,OVIP
 SG_ UnknownPciLow m4 : 3|4@0+ (1,0) [0|15] "raw"  BTEL,OVIP
 SG_ FlowStatus m3 : 3|4@0+ (1,0) [0|15] "raw"  BTEL,OVIP
 SG_ ConsecutiveSequence m2 : 3|4@0+ (1,0) [0|15] "raw"  BTEL,OVIP
 SG_ FirstFrameLength m1 : 3|12@0+ (1,0) [0|4095] "raw"  BTEL,OVIP
 SG_ SingleFrameLength m0 : 3|4@0+ (1,0) [0|15] "raw"  BTEL,OVIP
 SG_ IsoTpFrameType M : 7|4@0+ (1,0) [0|15] ""  BTEL,OVIP

BO_ 788 MDS_RemoteTelematicsOrder: 8 MDS
 SG_ FlowPadding5 m3 : 63|8@0+ (1,0) [0|255] "raw"  BSI
 SG_ FirstData6 m1 : 63|8@0+ (1,0) [0|255] "raw"  BSI
 SG_ UnknownData7 m4 : 63|8@0+ (1,0) [0|255] "raw"  BSI
 SG_ ConsecutiveData7 m2 : 63|8@0+ (1,0) [0|255] "raw"  BSI
 SG_ SingleData7 m0 : 63|8@0+ (1,0) [0|255] "raw"  BSI
 SG_ FlowPadding4 m3 : 55|8@0+ (1,0) [0|255] "raw"  BSI
 SG_ FirstData5 m1 : 55|8@0+ (1,0) [0|255] "raw"  BSI
 SG_ UnknownData6 m4 : 55|8@0+ (1,0) [0|255] "raw"  BSI
 SG_ ConsecutiveData6 m2 : 55|8@0+ (1,0) [0|255] "raw"  BSI
 SG_ SingleData6 m0 : 55|8@0+ (1,0) [0|255] "raw"  BSI
 SG_ FlowPadding3 m3 : 47|8@0+ (1,0) [0|255] "raw"  BSI
 SG_ FirstData4 m1 : 47|8@0+ (1,0) [0|255] "raw"  BSI
 SG_ UnknownData5 m4 : 47|8@0+ (1,0) [0|255] "raw"  BSI
 SG_ ConsecutiveData5 m2 : 47|8@0+ (1,0) [0|255] "raw"  BSI
 SG_ SingleData5 m0 : 47|8@0+ (1,0) [0|255] "raw"  BSI
 SG_ FlowPadding2 m3 : 39|8@0+ (1,0) [0|255] "raw"  BSI
 SG_ FirstData3 m1 : 39|8@0+ (1,0) [0|255] "raw"  BSI
 SG_ UnknownData4 m4 : 39|8@0+ (1,0) [0|255] "raw"  BSI
 SG_ ConsecutiveData4 m2 : 39|8@0+ (1,0) [0|255] "raw"  BSI
 SG_ SingleData4 m0 : 39|8@0+ (1,0) [0|255] "raw"  BSI
 SG_ FlowPadding1 m3 : 31|8@0+ (1,0) [0|255] "raw"  BSI
 SG_ FirstData2 m1 : 31|8@0+ (1,0) [0|255] "raw"  BSI
 SG_ UnknownData3 m4 : 31|8@0+ (1,0) [0|255] "raw"  BSI
 SG_ ConsecutiveData3 m2 : 31|8@0+ (1,0) [0|255] "raw"  BSI
 SG_ SingleData3 m0 : 31|8@0+ (1,0) [0|255] "raw"  BSI
 SG_ FirstData1 m1 : 23|8@0+ (1,0) [0|255] "raw"  BSI
 SG_ UnknownData2 m4 : 23|8@0+ (1,0) [0|255] "raw"  BSI
 SG_ ConsecutiveData2 m2 : 23|8@0+ (1,0) [0|255] "raw"  BSI
 SG_ SingleData2 m0 : 23|8@0+ (1,0) [0|255] "raw"  BSI
 SG_ SeparationTimeRaw m3 : 23|8@0+ (1,0) [0|255] "raw"  BSI
 SG_ UnknownData1 m4 : 15|8@0+ (1,0) [0|255] "raw"  BSI
 SG_ ConsecutiveData1 m2 : 15|8@0+ (1,0) [0|255] "raw"  BSI
 SG_ SingleData1 m0 : 15|8@0+ (1,0) [0|255] "raw"  BSI
 SG_ BlockSize m3 : 15|8@0+ (1,0) [0|255] "raw"  BSI
 SG_ UnknownPciLow m4 : 3|4@0+ (1,0) [0|15] "raw"  BSI
 SG_ FlowStatus m3 : 3|4@0+ (1,0) [0|15] "raw"  BSI
 SG_ ConsecutiveSequence m2 : 3|4@0+ (1,0) [0|15] "raw"  BSI
 SG_ FirstFrameLength m1 : 3|12@0+ (1,0) [0|4095] "raw"  BSI
 SG_ SingleFrameLength m0 : 3|4@0+ (1,0) [0|15] "raw"  BSI
 SG_ IsoTpFrameType M : 7|4@0+ (1,0) [0|15] ""  BSI

BO_ 791 IC_Config: 5 IC
 SG_ Unused2 : 35|4@0+ (1,0) [0|15] ""  BSI
 SG_ IndicatorBatteryPresent : 36|1@0+ (1,0) [0|1] ""  BSI
 SG_ IndicatorSamPresent : 37|1@0+ (1,0) [0|1] ""  BSI
 SG_ Unused1 : 38|1@0+ (1,0) [0|1] ""  BSI
 SG_ PassiveSafetyPresent : 39|1@0+ (1,0) [0|1] ""  BSI
 SG_ IndicatorBrakePressedPresent : 24|1@0+ (1,0) [0|1] ""  BSI
 SG_ IndicatorFse2Present : 25|1@0+ (1,0) [0|1] ""  BSI
 SG_ IndicatorFsePresent : 26|1@0+ (1,0) [0|1] ""  BSI
 SG_ StartIndicatorPresence : 27|1@0+ (1,0) [0|1] ""  BSI
 SG_ IndicatorBrakesPresent : 28|1@0+ (1,0) [0|1] ""  BSI
 SG_ IndicatorStopAndStartPresent : 29|1@0+ (1,0) [0|1] ""  BSI
 SG_ IndicatorEspPresent : 30|1@0+ (1,0) [0|1] ""  BSI
 SG_ IndicatorAbsPresent : 31|1@0+ (1,0) [0|1] ""  BSI
 SG_ SuspensionFaultPresent : 16|1@0+ (1,0) [0|1] ""  BSI
 SG_ ElectricParkingBrakeFaultPresent : 17|1@0+ (1,0) [0|1] ""  BSI
 SG_ IndicatorFapPresent : 18|1@0+ (1,0) [0|1] ""  BSI
 SG_ IndicatorEnginePresent : 19|1@0+ (1,0) [0|1] ""  BSI
 SG_ IndicatorWheelsPuncturePresent : 20|1@0+ (1,0) [0|1] ""  BSI
 SG_ IndicatorWheelsPresurePresent : 21|1@0+ (1,0) [0|1] ""  BSI
 SG_ IndicatorFseDisabledPresent : 22|1@0+ (1,0) [0|1] ""  BSI
 SG_ IndicatorHydroLevelPresent : 23|1@0+ (1,0) [0|1] ""  BSI
 SG_ IndicatorOilPressurePresent : 8|1@0+ (1,0) [0|1] ""  BSI
 SG_ IndicatorGasoilWaterPresent : 9|1@0+ (1,0) [0|1] ""  BSI
 SG_ IndicatorCoolantLevelPresent : 10|1@0+ (1,0) [0|1] ""  BSI
 SG_ IndicatorOilTempPresent : 11|1@0+ (1,0) [0|1] ""  BSI
 SG_ IndicatorCoolantTempPresent : 12|1@0+ (1,0) [0|1] ""  BSI
 SG_ IndicatorAlternatorPresent : 13|1@0+ (1,0) [0|1] ""  BSI
 SG_ IndicatorDsgFaultPresent : 14|1@0+ (1,0) [0|1] ""  BSI
 SG_ IndicatorDoorsOpenPresent : 15|1@0+ (1,0) [0|1] ""  BSI
 SG_ IndicatorStopPresent : 0|1@0+ (1,0) [0|1] ""  BSI
 SG_ IndicatorErrorPresent : 1|1@0+ (1,0) [0|1] ""  BSI
 SG_ CaarIndicatorPresent : 2|1@0+ (1,0) [0|1] ""  BSI
 SG_ IndicatorFuelLineBlockedPresent : 3|1@0+ (1,0) [0|1] ""  BSI
 SG_ IndicatorFuelReservePresent : 4|1@0+ (1,0) [0|1] ""  BSI
 SG_ IndicatorParkingBrakePresent : 5|1@0+ (1,0) [0|1] ""  BSI
 SG_ IndicatorDaePresent : 6|1@0+ (1,0) [0|1] ""  BSI
 SG_ IndicatorPassengerAirbagPresent : 7|1@0+ (1,0) [0|1] ""  BSI

BO_ 794 BSI_ZevTripInfo: 8 BSI
 SG_ Unused1 : 57|2@0+ (1,0) [0|3] ""  BTEL,CMB,OVIP
 SG_ ChargingType : 58|1@0+ (1,0) [0|1] ""  BTEL,CMB,OVIP
 SG_ ScheduledChargingStartTime : 53|11@0+ (1,0) [0|1440] "min"  BTEL,CMB,OVIP
 SG_ ChargeRemainingTime : 44|7@0+ (5,0) [0|630] "min"  BTEL,CMB,OVIP
 SG_ ZevInstantConsumption : 37|9@0+ (0.1,0) [0|50] "kWh/100km"  BTEL,CMB,OVIP
 SG_ ZevAverageConsumptionTrip2 : 30|9@0+ (0.1,0) [0|50] "kWh/100km"  BTEL,CMB,OVIP
 SG_ ZevAverageConsumptionTrip1 : 23|9@0+ (0.1,0) [0|50] "kWh/100km"  BTEL,CMB,OVIP
 SG_ ZevPercentage : 14|7@0+ (1,0) [0|100] "%"  BTEL,CMB,OVIP
 SG_ ZevRangeDisplay : 7|9@0+ (2,0) [0|1000] "km"  BTEL,CMB,OVIP

BO_ 795 MDS_ClimatePrecondSchedRemote: 7 MDS
 SG_ ClimatePrecondRemoteSlot2_b77ae3 : 42|11@0+ (1,0) [0|1440] "min"  BSI
 SG_ RawBits40_44 : 47|5@0+ (1,0) [0|31] "raw" Vector__XXX
 SG_ ClimatePrecondRemoteSunda_0b3fd3 : 32|1@0+ (1,0) [0|1] ""  BSI
 SG_ ClimatePrecondRemoteSatur_e982cd : 33|1@0+ (1,0) [0|1] ""  BSI
 SG_ ClimatePrecondRemoteFrida_9070b7 : 34|1@0+ (1,0) [0|1] ""  BSI
 SG_ ClimatePrecondRemoteThurs_e1ef2a : 35|1@0+ (1,0) [0|1] ""  BSI
 SG_ ClimatePrecondRemoteWedne_cfe436 : 36|1@0+ (1,0) [0|1] ""  BSI
 SG_ ClimatePrecondRemoteTuesd_c35246 : 37|1@0+ (1,0) [0|1] ""  BSI
 SG_ ClimatePrecondRemoteMonda_c770a4 : 38|1@0+ (1,0) [0|1] ""  BSI
 SG_ ClimatePrecondRemoteSlot2Enabled : 39|1@0+ (1,0) [0|1] ""  BSI
 SG_ ClimatePrecondRemoteSlot1_b80884 : 18|11@0+ (1,0) [0|1440] "min"  BSI
 SG_ RawBits16_20 : 23|5@0+ (1,0) [0|31] "raw" Vector__XXX
 SG_ ClimatePrecondRemoteSunda_2d4a77 : 8|1@0+ (1,0) [0|1] ""  BSI
 SG_ ClimatePrecondRemoteSatur_221a26 : 9|1@0+ (1,0) [0|1] ""  BSI
 SG_ ClimatePrecondRemoteFrida_6939df : 10|1@0+ (1,0) [0|1] ""  BSI
 SG_ ClimatePrecondRemoteThurs_93f86e : 11|1@0+ (1,0) [0|1] ""  BSI
 SG_ ClimatePrecondRemoteWedne_95c1ef : 12|1@0+ (1,0) [0|1] ""  BSI
 SG_ ClimatePrecondRemoteTuesd_8ad48a : 13|1@0+ (1,0) [0|1] ""  BSI
 SG_ ClimatePrecondRemoteMonda_95abbb : 14|1@0+ (1,0) [0|1] ""  BSI
 SG_ ClimatePrecondRemoteSlot1Enabled : 15|1@0+ (1,0) [0|1] ""  BSI
 SG_ RawBits2_7 : 5|6@0+ (1,0) [0|63] "raw" Vector__XXX
 SG_ ClimatePrecondAsapRequest : 6|1@0+ (1,0) [0|1] ""  BSI
 SG_ ClimatePrecondRemoteMenuA_2dcd7c : 7|1@0+ (1,0) [0|1] ""  BSI

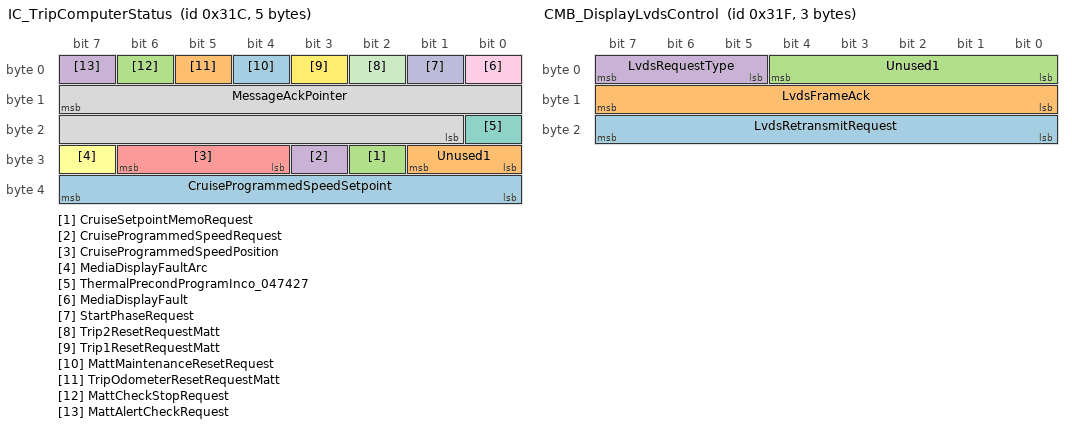
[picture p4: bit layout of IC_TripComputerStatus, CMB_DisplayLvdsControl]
BO_ 796 IC_TripComputerStatus: 5 IC
 SG_ CruiseProgrammedSpeedSetpoint : 39|8@0+ (1,0) [0|254] "km/h"  BSI
 SG_ Unused1 : 25|2@0+ (1,0) [0|3] ""  BSI
 SG_ CruiseSetpointMemoRequest : 26|1@0+ (1,0) [0|1] ""  BSI
 SG_ CruiseProgrammedSpeedRequest : 27|1@0+ (1,0) [0|1] ""  BSI
 SG_ CruiseProgrammedSpeedPosition : 30|3@0+ (1,0) [0|7] ""  BSI
 SG_ MediaDisplayFaultArc : 31|1@0+ (1,0) [0|1] ""  BSI
 SG_ ThermalPrecondProgramInco_047427 : 16|1@0+ (1,0) [0|1] ""  BSI
 SG_ MessageAckPointer : 15|15@0+ (1,0) [0|32767] ""  BSI
 SG_ MediaDisplayFault : 0|1@0+ (1,0) [0|1] ""  BSI
 SG_ StartPhaseRequest : 1|1@0+ (1,0) [0|1] ""  BSI
 SG_ Trip2ResetRequestMatt : 2|1@0+ (1,0) [0|1] ""  BSI
 SG_ Trip1ResetRequestMatt : 3|1@0+ (1,0) [0|1] ""  BSI
 SG_ MattMaintenanceResetRequest : 4|1@0+ (1,0) [0|1] ""  BSI
 SG_ TripOdometerResetRequestMatt : 5|1@0+ (1,0) [0|1] ""  BSI
 SG_ MattCheckStopRequest : 6|1@0+ (1,0) [0|1] ""  BSI
 SG_ MattAlertCheckRequest : 7|1@0+ (1,0) [0|1] ""  BSI

BO_ 799 CMB_DisplayLvdsControl: 3 CMB
 SG_ LvdsRetransmitRequest : 23|8@0+ (1,0) [0|255] ""  OVIP,BTEL
 SG_ LvdsFrameAck : 15|8@0+ (1,0) [0|255] ""  OVIP,BTEL
 SG_ Unused1 : 4|5@0+ (1,0) [0|31] ""  OVIP,BTEL
 SG_ LvdsRequestType : 7|3@0+ (1,0) [0|7] ""  OVIP,BTEL

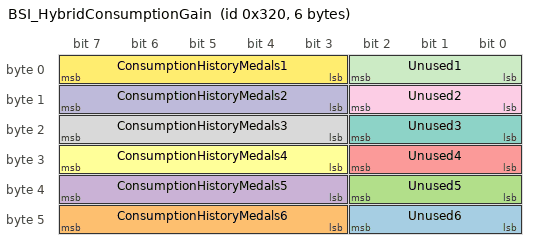
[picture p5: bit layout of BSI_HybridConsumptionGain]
BO_ 800 BSI_HybridConsumptionGain: 6 BSI
 SG_ Unused6 : 42|3@0+ (1,0) [0|7] ""  OVIP,RAD
 SG_ ConsumptionHistoryMedals6 : 47|5@0+ (1,0) [0|20] "kWh/100km"  OVIP,RAD
 SG_ Unused5 : 34|3@0+ (1,0) [0|7] ""  OVIP,RAD
 SG_ ConsumptionHistoryMedals5 : 39|5@0+ (1,0) [0|20] "kWh/100km"  OVIP,RAD
 SG_ Unused4 : 26|3@0+ (1,0) [0|7] ""  OVIP,RAD
 SG_ ConsumptionHistoryMedals4 : 31|5@0+ (1,0) [0|20] "kWh/100km"  OVIP,RAD
 SG_ Unused3 : 18|3@0+ (1,0) [0|7] ""  OVIP,RAD
 SG_ ConsumptionHistoryMedals3 : 23|5@0+ (1,0) [0|20] "kWh/100km"  OVIP,RAD
 SG_ Unused2 : 10|3@0+ (1,0) [0|7] ""  OVIP,RAD
 SG_ ConsumptionHistoryMedals2 : 15|5@0+ (1,0) [0|20] "kWh/100km"  OVIP,RAD
 SG_ Unused1 : 2|3@0+ (1,0) [0|7] ""  OVIP,RAD
 SG_ ConsumptionHistoryMedals1 : 7|5@0+ (1,0) [0|20] "kWh/100km"  OVIP,RAD

BO_ 801 BSI_CombineAlertsIndicators2: 6 BSI
 SG_ Unused2 : 44|5@0+ (1,0) [0|31] ""  CMB,MATT
 SG_ ElectricMotorFaultG4Indicator : 45|1@0+ (1,0) [0|1] ""  CMB,MATT
 SG_ ElectricMotorFaultG3Indicator : 46|1@0+ (1,0) [0|1] ""  CMB,MATT
 SG_ TurtleModeIndicator : 47|1@0+ (1,0) [0|1] ""  CMB,MATT
 SG_ LowBatteryLevelIndicator : 32|1@0+ (1,0) [0|1] ""  CMB,MATT
 SG_ AvasIndicatorRequest : 33|1@0+ (1,0) [0|1] ""  CMB,MATT
 SG_ GearboxUnlockIndicator : 35|2@0+ (1,0) [0|3] ""  CMB,MATT
 SG_ AbsdStateIndicator : 37|2@0+ (1,0) [0|3] ""  CMB,MATT
 SG_ NightVisionAnimalAlert : 38|1@0+ (1,0) [0|1] ""  CMB,MATT
 SG_ NightVisionPedestrianAlert : 39|1@0+ (1,0) [0|1] ""  CMB,MATT
 SG_ Unused1 : 24|1@0+ (1,0) [0|1] ""  CMB,MATT
 SG_ NightVisionState : 26|2@0+ (1,0) [0|3] ""  CMB,MATT
 SG_ NightVisionDefectSoundRenew : 27|1@0+ (1,0) [0|1] ""  CMB,MATT
 SG_ NightVisionDefectSound : 28|1@0+ (1,0) [0|1] ""  CMB,MATT
 SG_ NightVisionBeamActivation_6a287d : 29|1@0+ (1,0) [0|1] ""  CMB,MATT
 SG_ NightVisionBeamActivationMessage : 30|1@0+ (1,0) [0|1] ""  CMB,MATT
 SG_ NightVisionAnimalSoundAlert : 31|1@0+ (1,0) [0|1] ""  CMB,MATT
 SG_ NightVisionPedestrianSoundAlert : 16|1@0+ (1,0) [0|1] ""  CMB,MATT
 SG_ NightVisionDefectMessageRenew : 17|1@0+ (1,0) [0|1] ""  CMB,MATT
 SG_ NightVisionActivatedMessage : 18|1@0+ (1,0) [0|1] ""  CMB,MATT
 SG_ NightVisionDefectMessage : 19|1@0+ (1,0) [0|1] ""  CMB,MATT
 SG_ NightVisionSelectionState : 21|2@0+ (1,0) [0|3] ""  CMB,MATT
 SG_ NightVisionDetectionState : 22|1@0+ (1,0) [0|1] ""  CMB,MATT
 SG_ DriverDrowsinessState : 23|1@0+ (1,0) [0|1] ""  CMB,MATT
 SG_ DriverDistractionState : 8|1@0+ (1,0) [0|1] ""  CMB,MATT
 SG_ OverloadIndicatorRequest : 9|1@0+ (1,0) [0|1] ""  CMB,MATT
 SG_ DriverDrowsinessLevel : 12|3@0+ (1,0) [0|7] ""  CMB,MATT
 SG_ DriverDistractionLevel : 15|3@0+ (1,0) [0|7] ""  CMB,MATT
 SG_ GearShiftAdviceReinforcement : 1|2@0+ (1,0) [0|3] ""  CMB,MATT
 SG_ CoastingState : 3|2@0+ (1,0) [0|3] ""  CMB,MATT
 SG_ EcoDrivingAdvice : 7|4@0+ (1,0) [0|10] ""  CMB,MATT

BO_ 805 RAD_RadioMediaStatus: 4 RAD
 SG_ Unused1 : 30|7@0+ (1,0) [0|127] ""  CRT,FMUX,EMF
 SG_ UsbPlayerOverload : 31|1@0+ (1,0) [0|1] ""  CRT,FMUX,EMF
 SG_ AudioStreamingErrorType : 17|2@0+ (1,0) [0|3] ""  CRT,FMUX,EMF
 SG_ AudioFileDetected : 18|1@0+ (1,0) [0|1] ""  CRT,FMUX,EMF
 SG_ UsbCommunicationError : 19|1@0+ (1,0) [0|1] ""  CRT,FMUX,EMF
 SG_ UsbDeviceIdentification : 20|1@0+ (1,0) [0|1] ""  CRT,FMUX,EMF
 SG_ UsbSourceInfo : 21|1@0+ (1,0) [0|1] ""  CRT,FMUX,EMF
 SG_ BluetoothAccessInProgress : 22|1@0+ (1,0) [0|1] ""  CRT,FMUX,EMF
 SG_ UsbAccessInProgress : 23|1@0+ (1,0) [0|1] ""  CRT,FMUX,EMF
 SG_ BluetoothPlayerStatus : 10|3@0+ (1,0) [0|7] ""  CRT,FMUX,EMF
 SG_ UsbPlayerStatus : 13|3@0+ (1,0) [0|7] ""  CRT,FMUX,EMF
 SG_ AccessCd : 15|2@0+ (1,0) [0|3] ""  CRT,FMUX,EMF
 SG_ CdPlayerStatus : 2|3@0+ (1,0) [0|7] ""  CRT,FMUX,EMF
 SG_ DiscType : 3|1@0+ (1,0) [0|1] ""  CRT,FMUX,EMF
 SG_ CdOverheating : 4|1@0+ (1,0) [0|1] ""  CRT,FMUX,EMF
 SG_ DiskDirection : 5|1@0+ (1,0) [0|1] ""  CRT,FMUX,EMF
 SG_ CdPlayerError : 6|1@0+ (1,0) [0|1] ""  CRT,FMUX,EMF
 SG_ DiscError : 7|1@0+ (1,0) [0|1] ""  CRT,FMUX,EMF

BO_ 807 EMF_RadioTextStatusAck: 1 EMF
 SG_ SegmentationAckStream : 7|8@0+ (1,0) [0|255] ""  RAD

BO_TX_BU_ 694 : ICSV,BSI;
BO_TX_BU_ 709 : OVIP,BTEL;
BO_TX_BU_ 731 : BTEL,MDS,OVIP;
BO_TX_BU_ 732 : ICSV,MATT,CMB;
BO_TX_BU_ 735 : EMF,ICSV;
BO_TX_BU_ 745 : BTEL,OVIP;
BO_TX_BU_ 805 : RAD,ICSV;
BO_TX_BU_ 807 : EMF,ICSV;
CM_ BO_ 694 "DATABASE_CANDIDATE: physical interpretation unverified; capture/layout evidence reported separately. INFO-DIV CAN, 125000 bit/s; CAN ID 0x2B6. PSA-RE title: ACC_DYNAMIC_STATE. VIN = Vehicle Identification Number. VIS = Vehicle Indicator Section, VIN field that distinguishes one vehicle from another. Source: https://github.com/prototux/PSA-RE/blob/67f7581e7622410efdbb29c7eda3b86982b9b450/buses/AEE2010.full/LS.INFO-DIV/2B6.yml. Source sender alternatives: ICSV,BSI; physical TX/gateway forwarding not verified. Observed 587 frames in info_apka.csv,info_buzeni_obc.csv,info_charging.csv,info_standby.csv,info_start_jizda.csv,infocan.csv; DLCs [8]. Unresolved alternative source layouts preserved in source JSON. ";
CM_ SG_ 694 VisChar8 "DATABASE_CANDIDATE: physical interpretation unverified; capture/layout evidence reported separately. PSA-RE bits 8.7-8.0. Eighth VIS character. Source text/byte field exposed as raw integer; no string decoding. Upstream default raw=0 (not necessarily valid data).";
CM_ SG_ 694 VisChar7 "DATABASE_CANDIDATE: physical interpretation unverified; capture/layout evidence reported separately. PSA-RE bits 7.7-7.0. Seventh VIS character. Source text/byte field exposed as raw integer; no string decoding. Upstream default raw=0 (not necessarily valid data).";
CM_ SG_ 694 VisChar6 "DATABASE_CANDIDATE: physical interpretation unverified; capture/layout evidence reported separately. PSA-RE bits 6.7-6.0. Sixth VIS character. Source text/byte field exposed as raw integer; no string decoding. Upstream default raw=0 (not necessarily valid data).";
CM_ SG_ 694 VisChar5 "DATABASE_CANDIDATE: physical interpretation unverified; capture/layout evidence reported separately. PSA-RE bits 5.7-5.0. Fifth VIS character. Source text/byte field exposed as raw integer; no string decoding. Upstream default raw=0 (not necessarily valid data).";
CM_ SG_ 694 VisChar4 "DATABASE_CANDIDATE: physical interpretation unverified; capture/layout evidence reported separately. PSA-RE bits 4.7-4.0. Fourth VIS character. Source text/byte field exposed as raw integer; no string decoding. Upstream default raw=0 (not necessarily valid data).";
CM_ SG_ 694 VisChar3 "DATABASE_CANDIDATE: physical interpretation unverified; capture/layout evidence reported separately. PSA-RE bits 3.7-3.0. Third VIS character. Source text/byte field exposed as raw integer; no string decoding. Upstream default raw=0 (not necessarily valid data).";
CM_ SG_ 694 VisChar2 "DATABASE_CANDIDATE: physical interpretation unverified; capture/layout evidence reported separately. PSA-RE bits 2.7-2.0. Second VIS character. Source text/byte field exposed as raw integer; no string decoding. Upstream default raw=0 (not necessarily valid data).";
CM_ SG_ 694 VisChar1 "DATABASE_CANDIDATE: physical interpretation unverified; capture/layout evidence reported separately. PSA-RE bits 1.7-1.0. First VIS character. Source text/byte field exposed as raw integer; no string decoding. Upstream default raw=0 (not necessarily valid data).";
CM_ BO_ 705 "DATABASE_CANDIDATE: physical interpretation unverified; capture/layout evidence reported separately. INFO-DIV CAN, 125000 bit/s; CAN ID 0x2C1. PSA-RE title: UID_TABLE_ENCRYPTED_TO_BSI_FLOW_CONTROL. ISO-TP flow control frame for the encrypted identifier table transfer to the BSI Source: https://github.com/prototux/PSA-RE/blob/67f7581e7622410efdbb29c7eda3b86982b9b450/buses/AEE2010.full/LS.INFO-DIV/2C1.yml. Source sender alternatives: BSI; physical TX/gateway forwarding not verified. WIRE ISO-TP ONLY: normal addressing candidate, maximum Classical CAN DLC 8; actual DLC may be shorter. Data includes padding. No reassembly, text, DID or application-layer decoding. Original application layouts are preserved in source JSON; do not decode them at wire offsets. ";
CM_ SG_ 705 FlowPadding5 "TRANSPORT_CANDIDATE: normal-addressing ISO-TP. PSA-RE bits 8.7-8.0. ";
CM_ SG_ 705 FirstData6 "TRANSPORT_CANDIDATE: normal-addressing ISO-TP. PSA-RE bits 8.7-8.0. ";
CM_ SG_ 705 UnknownData7 "TRANSPORT_CANDIDATE: normal-addressing ISO-TP. PSA-RE bits 8.7-8.0. ";
CM_ SG_ 705 ConsecutiveData7 "TRANSPORT_CANDIDATE: normal-addressing ISO-TP. PSA-RE bits 8.7-8.0. ";
CM_ SG_ 705 SingleData7 "TRANSPORT_CANDIDATE: normal-addressing ISO-TP. PSA-RE bits 8.7-8.0. ";
CM_ SG_ 705 FlowPadding4 "TRANSPORT_CANDIDATE: normal-addressing ISO-TP. PSA-RE bits 7.7-7.0. ";
CM_ SG_ 705 FirstData5 "TRANSPORT_CANDIDATE: normal-addressing ISO-TP. PSA-RE bits 7.7-7.0. ";
CM_ SG_ 705 UnknownData6 "TRANSPORT_CANDIDATE: normal-addressing ISO-TP. PSA-RE bits 7.7-7.0. ";
CM_ SG_ 705 ConsecutiveData6 "TRANSPORT_CANDIDATE: normal-addressing ISO-TP. PSA-RE bits 7.7-7.0. ";
CM_ SG_ 705 SingleData6 "TRANSPORT_CANDIDATE: normal-addressing ISO-TP. PSA-RE bits 7.7-7.0. ";
CM_ SG_ 705 FlowPadding3 "TRANSPORT_CANDIDATE: normal-addressing ISO-TP. PSA-RE bits 6.7-6.0. ";
CM_ SG_ 705 FirstData4 "TRANSPORT_CANDIDATE: normal-addressing ISO-TP. PSA-RE bits 6.7-6.0. ";
CM_ SG_ 705 UnknownData5 "TRANSPORT_CANDIDATE: normal-addressing ISO-TP. PSA-RE bits 6.7-6.0. ";
CM_ SG_ 705 ConsecutiveData5 "TRANSPORT_CANDIDATE: normal-addressing ISO-TP. PSA-RE bits 6.7-6.0. ";
CM_ SG_ 705 SingleData5 "TRANSPORT_CANDIDATE: normal-addressing ISO-TP. PSA-RE bits 6.7-6.0. ";
CM_ SG_ 705 FlowPadding2 "TRANSPORT_CANDIDATE: normal-addressing ISO-TP. PSA-RE bits 5.7-5.0. ";
CM_ SG_ 705 FirstData3 "TRANSPORT_CANDIDATE: normal-addressing ISO-TP. PSA-RE bits 5.7-5.0. ";
CM_ SG_ 705 UnknownData4 "TRANSPORT_CANDIDATE: normal-addressing ISO-TP. PSA-RE bits 5.7-5.0. ";
CM_ SG_ 705 ConsecutiveData4 "TRANSPORT_CANDIDATE: normal-addressing ISO-TP. PSA-RE bits 5.7-5.0. ";
CM_ SG_ 705 SingleData4 "TRANSPORT_CANDIDATE: normal-addressing ISO-TP. PSA-RE bits 5.7-5.0. ";
CM_ SG_ 705 FlowPadding1 "TRANSPORT_CANDIDATE: normal-addressing ISO-TP. PSA-RE bits 4.7-4.0. ";
CM_ SG_ 705 FirstData2 "TRANSPORT_CANDIDATE: normal-addressing ISO-TP. PSA-RE bits 4.7-4.0. ";
CM_ SG_ 705 UnknownData3 "TRANSPORT_CANDIDATE: normal-addressing ISO-TP. PSA-RE bits 4.7-4.0. ";
CM_ SG_ 705 ConsecutiveData3 "TRANSPORT_CANDIDATE: normal-addressing ISO-TP. PSA-RE bits 4.7-4.0. ";
CM_ SG_ 705 SingleData3 "TRANSPORT_CANDIDATE: normal-addressing ISO-TP. PSA-RE bits 4.7-4.0. ";
CM_ SG_ 705 FirstData1 "TRANSPORT_CANDIDATE: normal-addressing ISO-TP. PSA-RE bits 3.7-3.0. ";
CM_ SG_ 705 UnknownData2 "TRANSPORT_CANDIDATE: normal-addressing ISO-TP. PSA-RE bits 3.7-3.0. ";
CM_ SG_ 705 ConsecutiveData2 "TRANSPORT_CANDIDATE: normal-addressing ISO-TP. PSA-RE bits 3.7-3.0. ";
CM_ SG_ 705 SingleData2 "TRANSPORT_CANDIDATE: normal-addressing ISO-TP. PSA-RE bits 3.7-3.0. ";
CM_ SG_ 705 SeparationTimeRaw "TRANSPORT_CANDIDATE: normal-addressing ISO-TP. PSA-RE bits 3.7-3.0. Raw STmin code; 0xF1..0xF9 are not milliseconds.";
CM_ SG_ 705 UnknownData1 "TRANSPORT_CANDIDATE: normal-addressing ISO-TP. PSA-RE bits 2.7-2.0. ";
CM_ SG_ 705 ConsecutiveData1 "TRANSPORT_CANDIDATE: normal-addressing ISO-TP. PSA-RE bits 2.7-2.0. ";
CM_ SG_ 705 SingleData1 "TRANSPORT_CANDIDATE: normal-addressing ISO-TP. PSA-RE bits 2.7-2.0. ";
CM_ SG_ 705 BlockSize "TRANSPORT_CANDIDATE: normal-addressing ISO-TP. PSA-RE bits 2.7-2.0. ";
CM_ SG_ 705 UnknownPciLow "TRANSPORT_CANDIDATE: normal-addressing ISO-TP. PSA-RE bits 1.3-1.0. ";
CM_ SG_ 705 FlowStatus "TRANSPORT_CANDIDATE: normal-addressing ISO-TP. PSA-RE bits 1.3-1.0. ";
CM_ SG_ 705 ConsecutiveSequence "TRANSPORT_CANDIDATE: normal-addressing ISO-TP. PSA-RE bits 1.3-1.0. ";
CM_ SG_ 705 FirstFrameLength "TRANSPORT_CANDIDATE: normal-addressing ISO-TP. PSA-RE bits 1.3-2.0. 12-bit declared PDU length; not a reassembled value.";
CM_ SG_ 705 SingleFrameLength "TRANSPORT_CANDIDATE: normal-addressing ISO-TP. PSA-RE bits 1.3-1.0. Declared data length; not a validity check.";
CM_ SG_ 705 IsoTpFrameType "TRANSPORT_CANDIDATE: normal-addressing ISO-TP. PSA-RE bits 1.7-1.4. PCI high nibble; normal addressing candidate.";
CM_ BO_ 707 "DATABASE_CANDIDATE: physical interpretation unverified; capture/layout evidence reported separately. INFO-DIV CAN, 125000 bit/s; CAN ID 0x2C3. PSA-RE title: ODI_BUFFER_TO_TELEMATICS. Opaque data buffer of the embedded diagnostics interface (ODI) between the telematics unit and the diagnostic tool: data sent to the telematics unit. Source: https://github.com/prototux/PSA-RE/blob/67f7581e7622410efdbb29c7eda3b86982b9b450/buses/AEE2010.full/LS.INFO-DIV/2C3.yml. Source sender alternatives: BTEL; physical TX/gateway forwarding not verified. ";
CM_ SG_ 707 OdiCenterstackToTelematicsBuffer "DATABASE_CANDIDATE: physical interpretation unverified; capture/layout evidence reported separately. PSA-RE bits 1.7-8.0. Open Display Interface (ODI) buffer, center stack display to telematics unit";
CM_ BO_ 709 "DATABASE_CANDIDATE: physical interpretation unverified; capture/layout evidence reported separately. INFO-DIV CAN, 125000 bit/s; CAN ID 0x2C5. PSA-RE title: DASHCAM_LIST_FLOW_CONTROL. ISO-TP flow-control frame for the dashcam video list transfer. Source: https://github.com/prototux/PSA-RE/blob/67f7581e7622410efdbb29c7eda3b86982b9b450/buses/AEE2010.full/LS.INFO-DIV/2C5.yml. Source sender alternatives: OVIP,BTEL; physical TX/gateway forwarding not verified. WIRE ISO-TP ONLY: normal addressing candidate, maximum Classical CAN DLC 8; actual DLC may be shorter. Data includes padding. No reassembly, text, DID or application-layer decoding. Original application layouts are preserved in source JSON; do not decode them at wire offsets. ";
CM_ SG_ 709 FlowPadding5 "TRANSPORT_CANDIDATE: normal-addressing ISO-TP. PSA-RE bits 8.7-8.0. ";
CM_ SG_ 709 FirstData6 "TRANSPORT_CANDIDATE: normal-addressing ISO-TP. PSA-RE bits 8.7-8.0. ";
CM_ SG_ 709 UnknownData7 "TRANSPORT_CANDIDATE: normal-addressing ISO-TP. PSA-RE bits 8.7-8.0. ";
CM_ SG_ 709 ConsecutiveData7 "TRANSPORT_CANDIDATE: normal-addressing ISO-TP. PSA-RE bits 8.7-8.0. ";
CM_ SG_ 709 SingleData7 "TRANSPORT_CANDIDATE: normal-addressing ISO-TP. PSA-RE bits 8.7-8.0. ";
CM_ SG_ 709 FlowPadding4 "TRANSPORT_CANDIDATE: normal-addressing ISO-TP. PSA-RE bits 7.7-7.0. ";
CM_ SG_ 709 FirstData5 "TRANSPORT_CANDIDATE: normal-addressing ISO-TP. PSA-RE bits 7.7-7.0. ";
CM_ SG_ 709 UnknownData6 "TRANSPORT_CANDIDATE: normal-addressing ISO-TP. PSA-RE bits 7.7-7.0. ";
CM_ SG_ 709 ConsecutiveData6 "TRANSPORT_CANDIDATE: normal-addressing ISO-TP. PSA-RE bits 7.7-7.0. ";
CM_ SG_ 709 SingleData6 "TRANSPORT_CANDIDATE: normal-addressing ISO-TP. PSA-RE bits 7.7-7.0. ";
CM_ SG_ 709 FlowPadding3 "TRANSPORT_CANDIDATE: normal-addressing ISO-TP. PSA-RE bits 6.7-6.0. ";
CM_ SG_ 709 FirstData4 "TRANSPORT_CANDIDATE: normal-addressing ISO-TP. PSA-RE bits 6.7-6.0. ";
CM_ SG_ 709 UnknownData5 "TRANSPORT_CANDIDATE: normal-addressing ISO-TP. PSA-RE bits 6.7-6.0. ";
CM_ SG_ 709 ConsecutiveData5 "TRANSPORT_CANDIDATE: normal-addressing ISO-TP. PSA-RE bits 6.7-6.0. ";
CM_ SG_ 709 SingleData5 "TRANSPORT_CANDIDATE: normal-addressing ISO-TP. PSA-RE bits 6.7-6.0. ";
CM_ SG_ 709 FlowPadding2 "TRANSPORT_CANDIDATE: normal-addressing ISO-TP. PSA-RE bits 5.7-5.0. ";
CM_ SG_ 709 FirstData3 "TRANSPORT_CANDIDATE: normal-addressing ISO-TP. PSA-RE bits 5.7-5.0. ";
CM_ SG_ 709 UnknownData4 "TRANSPORT_CANDIDATE: normal-addressing ISO-TP. PSA-RE bits 5.7-5.0. ";
CM_ SG_ 709 ConsecutiveData4 "TRANSPORT_CANDIDATE: normal-addressing ISO-TP. PSA-RE bits 5.7-5.0. ";
CM_ SG_ 709 SingleData4 "TRANSPORT_CANDIDATE: normal-addressing ISO-TP. PSA-RE bits 5.7-5.0. ";
CM_ SG_ 709 FlowPadding1 "TRANSPORT_CANDIDATE: normal-addressing ISO-TP. PSA-RE bits 4.7-4.0. ";
CM_ SG_ 709 FirstData2 "TRANSPORT_CANDIDATE: normal-addressing ISO-TP. PSA-RE bits 4.7-4.0. ";
CM_ SG_ 709 UnknownData3 "TRANSPORT_CANDIDATE: normal-addressing ISO-TP. PSA-RE bits 4.7-4.0. ";
CM_ SG_ 709 ConsecutiveData3 "TRANSPORT_CANDIDATE: normal-addressing ISO-TP. PSA-RE bits 4.7-4.0. ";
CM_ SG_ 709 SingleData3 "TRANSPORT_CANDIDATE: normal-addressing ISO-TP. PSA-RE bits 4.7-4.0. ";
CM_ SG_ 709 FirstData1 "TRANSPORT_CANDIDATE: normal-addressing ISO-TP. PSA-RE bits 3.7-3.0. ";
CM_ SG_ 709 UnknownData2 "TRANSPORT_CANDIDATE: normal-addressing ISO-TP. PSA-RE bits 3.7-3.0. ";
CM_ SG_ 709 ConsecutiveData2 "TRANSPORT_CANDIDATE: normal-addressing ISO-TP. PSA-RE bits 3.7-3.0. ";
CM_ SG_ 709 SingleData2 "TRANSPORT_CANDIDATE: normal-addressing ISO-TP. PSA-RE bits 3.7-3.0. ";
CM_ SG_ 709 SeparationTimeRaw "TRANSPORT_CANDIDATE: normal-addressing ISO-TP. PSA-RE bits 3.7-3.0. Raw STmin code; 0xF1..0xF9 are not milliseconds.";
CM_ SG_ 709 UnknownData1 "TRANSPORT_CANDIDATE: normal-addressing ISO-TP. PSA-RE bits 2.7-2.0. ";
CM_ SG_ 709 ConsecutiveData1 "TRANSPORT_CANDIDATE: normal-addressing ISO-TP. PSA-RE bits 2.7-2.0. ";
CM_ SG_ 709 SingleData1 "TRANSPORT_CANDIDATE: normal-addressing ISO-TP. PSA-RE bits 2.7-2.0. ";
CM_ SG_ 709 BlockSize "TRANSPORT_CANDIDATE: normal-addressing ISO-TP. PSA-RE bits 2.7-2.0. ";
CM_ SG_ 709 UnknownPciLow "TRANSPORT_CANDIDATE: normal-addressing ISO-TP. PSA-RE bits 1.3-1.0. ";
CM_ SG_ 709 FlowStatus "TRANSPORT_CANDIDATE: normal-addressing ISO-TP. PSA-RE bits 1.3-1.0. ";
CM_ SG_ 709 ConsecutiveSequence "TRANSPORT_CANDIDATE: normal-addressing ISO-TP. PSA-RE bits 1.3-1.0. ";
CM_ SG_ 709 FirstFrameLength "TRANSPORT_CANDIDATE: normal-addressing ISO-TP. PSA-RE bits 1.3-2.0. 12-bit declared PDU length; not a reassembled value.";
CM_ SG_ 709 SingleFrameLength "TRANSPORT_CANDIDATE: normal-addressing ISO-TP. PSA-RE bits 1.3-1.0. Declared data length; not a validity check.";
CM_ SG_ 709 IsoTpFrameType "TRANSPORT_CANDIDATE: normal-addressing ISO-TP. PSA-RE bits 1.7-1.4. PCI high nibble; normal addressing candidate.";
CM_ BO_ 721 "DATABASE_CANDIDATE: physical interpretation unverified; capture/layout evidence reported separately. INFO-DIV CAN, 125000 bit/s; CAN ID 0x2D1. PSA-RE title: SAM_PARKING_DATA. SAM parking-aid module data: display request, measured side, LED request, module state and detected object/slot size, left and right. Source: https://github.com/prototux/PSA-RE/blob/67f7581e7622410efdbb29c7eda3b86982b9b450/buses/AEE2010.full/LS.INFO-DIV/2D1.yml. Source sender alternatives: BSI; physical TX/gateway forwarding not verified. ";
CM_ SG_ 721 Unused2 "DATABASE_CANDIDATE: physical interpretation unverified; capture/layout evidence reported separately. PSA-RE bits 2.0. ";
CM_ SG_ 721 SpaceMeasurementSide "DATABASE_CANDIDATE: physical interpretation unverified; capture/layout evidence reported separately. PSA-RE bits 2.1. Side on which the available space is measured Upstream default raw=1 (not necessarily valid data).";
CM_ SG_ 721 SpaceMeasurementDisplayRequest "DATABASE_CANDIDATE: physical interpretation unverified; capture/layout evidence reported separately. PSA-RE bits 2.2. Request to display the evaluation result of the measured parking spot Upstream default raw=0 (not necessarily valid data).";
CM_ SG_ 721 MeasuredDistance "DATABASE_CANDIDATE: physical interpretation unverified; capture/layout evidence reported separately. PSA-RE bits 2.4-2.3. System evaluation of the measured parking spot size Upstream default raw=0 (not necessarily valid data).";
CM_ SG_ 721 SpaceMeasurementStatus "DATABASE_CANDIDATE: physical interpretation unverified; capture/layout evidence reported separately. PSA-RE bits 2.7-2.5. Available space measurement system status Upstream default raw=6 (not necessarily valid data).";
CM_ SG_ 721 SamActivityStatus "DATABASE_CANDIDATE: physical interpretation unverified; capture/layout evidence reported separately. PSA-RE bits 1.2-1.0. SAM activity status Upstream default raw=0 (not necessarily valid data).";
CM_ SG_ 721 SamLedRequest "DATABASE_CANDIDATE: physical interpretation unverified; capture/layout evidence reported separately. PSA-RE bits 1.4-1.3. SAM LED lighting type request Upstream default raw=0 (not necessarily valid data).";
CM_ SG_ 721 SamRightObjectPresent "DATABASE_CANDIDATE: physical interpretation unverified; capture/layout evidence reported separately. PSA-RE bits 1.5. Object present in the right-hand SAM zone Upstream default raw=0 (not necessarily valid data).";
CM_ SG_ 721 SamLeftObjectPresent "DATABASE_CANDIDATE: physical interpretation unverified; capture/layout evidence reported separately. PSA-RE bits 1.6. Object present in the left-hand SAM zone Upstream default raw=0 (not necessarily valid data).";
CM_ SG_ 721 Unused1 "DATABASE_CANDIDATE: physical interpretation unverified; capture/layout evidence reported separately. PSA-RE bits 1.7. ";
CM_ BO_ 724 "DATABASE_CANDIDATE: physical interpretation unverified; capture/layout evidence reported separately. INFO-DIV CAN, 125000 bit/s; CAN ID 0x2D4. PSA-RE title: REMOTE_ACTION_MONITORING_STATUS. Alarm and immobiliser monitoring status, including unauthorised start and break-in notifications. Source: https://github.com/prototux/PSA-RE/blob/67f7581e7622410efdbb29c7eda3b86982b9b450/buses/AEE2010.full/LS.INFO-DIV/2D4.yml. Source sender alternatives: BSI; physical TX/gateway forwarding not verified. Observed 588 frames in info_apka.csv,info_buzeni_obc.csv,info_charging.csv,info_standby.csv,info_start_jizda.csv,infocan.csv; DLCs [1]. WIRE ISO-TP ONLY: normal addressing candidate, maximum Classical CAN DLC 8; actual DLC may be shorter. Data includes padding. No reassembly, text, DID or application-layer decoding. Original application layouts are preserved in source JSON; do not decode them at wire offsets. ";
CM_ SG_ 724 FlowPadding5 "TRANSPORT_CANDIDATE: normal-addressing ISO-TP. PSA-RE bits 8.7-8.0. ";
CM_ SG_ 724 FirstData6 "TRANSPORT_CANDIDATE: normal-addressing ISO-TP. PSA-RE bits 8.7-8.0. ";
CM_ SG_ 724 UnknownData7 "TRANSPORT_CANDIDATE: normal-addressing ISO-TP. PSA-RE bits 8.7-8.0. ";
CM_ SG_ 724 ConsecutiveData7 "TRANSPORT_CANDIDATE: normal-addressing ISO-TP. PSA-RE bits 8.7-8.0. ";
CM_ SG_ 724 SingleData7 "TRANSPORT_CANDIDATE: normal-addressing ISO-TP. PSA-RE bits 8.7-8.0. ";
CM_ SG_ 724 FlowPadding4 "TRANSPORT_CANDIDATE: normal-addressing ISO-TP. PSA-RE bits 7.7-7.0. ";
CM_ SG_ 724 FirstData5 "TRANSPORT_CANDIDATE: normal-addressing ISO-TP. PSA-RE bits 7.7-7.0. ";
CM_ SG_ 724 UnknownData6 "TRANSPORT_CANDIDATE: normal-addressing ISO-TP. PSA-RE bits 7.7-7.0. ";
CM_ SG_ 724 ConsecutiveData6 "TRANSPORT_CANDIDATE: normal-addressing ISO-TP. PSA-RE bits 7.7-7.0. ";
CM_ SG_ 724 SingleData6 "TRANSPORT_CANDIDATE: normal-addressing ISO-TP. PSA-RE bits 7.7-7.0. ";
CM_ SG_ 724 FlowPadding3 "TRANSPORT_CANDIDATE: normal-addressing ISO-TP. PSA-RE bits 6.7-6.0. ";
CM_ SG_ 724 FirstData4 "TRANSPORT_CANDIDATE: normal-addressing ISO-TP. PSA-RE bits 6.7-6.0. ";
CM_ SG_ 724 UnknownData5 "TRANSPORT_CANDIDATE: normal-addressing ISO-TP. PSA-RE bits 6.7-6.0. ";
CM_ SG_ 724 ConsecutiveData5 "TRANSPORT_CANDIDATE: normal-addressing ISO-TP. PSA-RE bits 6.7-6.0. ";
CM_ SG_ 724 SingleData5 "TRANSPORT_CANDIDATE: normal-addressing ISO-TP. PSA-RE bits 6.7-6.0. ";
CM_ SG_ 724 FlowPadding2 "TRANSPORT_CANDIDATE: normal-addressing ISO-TP. PSA-RE bits 5.7-5.0. ";
CM_ SG_ 724 FirstData3 "TRANSPORT_CANDIDATE: normal-addressing ISO-TP. PSA-RE bits 5.7-5.0. ";
CM_ SG_ 724 UnknownData4 "TRANSPORT_CANDIDATE: normal-addressing ISO-TP. PSA-RE bits 5.7-5.0. ";
CM_ SG_ 724 ConsecutiveData4 "TRANSPORT_CANDIDATE: normal-addressing ISO-TP. PSA-RE bits 5.7-5.0. ";
CM_ SG_ 724 SingleData4 "TRANSPORT_CANDIDATE: normal-addressing ISO-TP. PSA-RE bits 5.7-5.0. ";
CM_ SG_ 724 FlowPadding1 "TRANSPORT_CANDIDATE: normal-addressing ISO-TP. PSA-RE bits 4.7-4.0. ";
CM_ SG_ 724 FirstData2 "TRANSPORT_CANDIDATE: normal-addressing ISO-TP. PSA-RE bits 4.7-4.0. ";
CM_ SG_ 724 UnknownData3 "TRANSPORT_CANDIDATE: normal-addressing ISO-TP. PSA-RE bits 4.7-4.0. ";
CM_ SG_ 724 ConsecutiveData3 "TRANSPORT_CANDIDATE: normal-addressing ISO-TP. PSA-RE bits 4.7-4.0. ";
CM_ SG_ 724 SingleData3 "TRANSPORT_CANDIDATE: normal-addressing ISO-TP. PSA-RE bits 4.7-4.0. ";
CM_ SG_ 724 FirstData1 "TRANSPORT_CANDIDATE: normal-addressing ISO-TP. PSA-RE bits 3.7-3.0. ";
CM_ SG_ 724 UnknownData2 "TRANSPORT_CANDIDATE: normal-addressing ISO-TP. PSA-RE bits 3.7-3.0. ";
CM_ SG_ 724 ConsecutiveData2 "TRANSPORT_CANDIDATE: normal-addressing ISO-TP. PSA-RE bits 3.7-3.0. ";
CM_ SG_ 724 SingleData2 "TRANSPORT_CANDIDATE: normal-addressing ISO-TP. PSA-RE bits 3.7-3.0. ";
CM_ SG_ 724 SeparationTimeRaw "TRANSPORT_CANDIDATE: normal-addressing ISO-TP. PSA-RE bits 3.7-3.0. Raw STmin code; 0xF1..0xF9 are not milliseconds.";
CM_ SG_ 724 UnknownData1 "TRANSPORT_CANDIDATE: normal-addressing ISO-TP. PSA-RE bits 2.7-2.0. ";
CM_ SG_ 724 ConsecutiveData1 "TRANSPORT_CANDIDATE: normal-addressing ISO-TP. PSA-RE bits 2.7-2.0. ";
CM_ SG_ 724 SingleData1 "TRANSPORT_CANDIDATE: normal-addressing ISO-TP. PSA-RE bits 2.7-2.0. ";
CM_ SG_ 724 BlockSize "TRANSPORT_CANDIDATE: normal-addressing ISO-TP. PSA-RE bits 2.7-2.0. ";
CM_ SG_ 724 UnknownPciLow "TRANSPORT_CANDIDATE: normal-addressing ISO-TP. PSA-RE bits 1.3-1.0. ";
CM_ SG_ 724 FlowStatus "TRANSPORT_CANDIDATE: normal-addressing ISO-TP. PSA-RE bits 1.3-1.0. ";
CM_ SG_ 724 ConsecutiveSequence "TRANSPORT_CANDIDATE: normal-addressing ISO-TP. PSA-RE bits 1.3-1.0. ";
CM_ SG_ 724 FirstFrameLength "TRANSPORT_CANDIDATE: normal-addressing ISO-TP. PSA-RE bits 1.3-2.0. 12-bit declared PDU length; not a reassembled value.";
CM_ SG_ 724 SingleFrameLength "TRANSPORT_CANDIDATE: normal-addressing ISO-TP. PSA-RE bits 1.3-1.0. Declared data length; not a validity check.";
CM_ SG_ 724 IsoTpFrameType "TRANSPORT_CANDIDATE: normal-addressing ISO-TP. PSA-RE bits 1.7-1.4. PCI high nibble; normal addressing candidate.";
CM_ BO_ 727 "DATABASE_CANDIDATE: physical interpretation unverified; capture/layout evidence reported separately. INFO-DIV CAN, 125000 bit/s; CAN ID 0x2D7. PSA-RE title: CLUSTER_SETTINGS_STATUS. Instrument cluster settings: sound command, preconditioning time, language and display units (consumption, distance, temperature, volume). Source: https://github.com/prototux/PSA-RE/blob/67f7581e7622410efdbb29c7eda3b86982b9b450/buses/AEE2010.full/LS.INFO-DIV/2D7.yml. Source sender alternatives: MATT,CMB; physical TX/gateway forwarding not verified. VEHICLE_SOURCE_REVIEW: Owner reports original instrument cluster unit004 connected for info_buzeni_obc.csv and absent in earlier captures. This ID is absent in info_standby.csv and fully operational info_start_jizda.csv; upstream lists CMB among possible senders. Owner approved limiting IC attribution to these nine messages. Scope: Vehicle-specific sender attribution from installation report/capture comparison and compatible source alias; does not validate signal meanings or exclude gateway forwarding. Observed 414 frames in info_buzeni_obc.csv,info_charging.csv; DLCs [3]. ";
CM_ SG_ 727 Unused1 "DATABASE_CANDIDATE: physical interpretation unverified; capture/layout evidence reported separately. PSA-RE bits 3.1-3.0. ";
CM_ SG_ 727 EcoachFieldAvailable "DATABASE_CANDIDATE: physical interpretation unverified; capture/layout evidence reported separately. PSA-RE bits 3.2. Flag indicating availability of the eco-coaching field in the personal mode choice list Upstream default raw=0 (not necessarily valid data).";
CM_ SG_ 727 DaaFieldAvailable "DATABASE_CANDIDATE: physical interpretation unverified; capture/layout evidence reported separately. PSA-RE bits 3.3. Flag indicating availability of the DAA (driver attention assist) field in the personal mode choice list Upstream default raw=0 (not necessarily valid data).";
CM_ SG_ 727 TripComputerFieldAvailable "DATABASE_CANDIDATE: physical interpretation unverified; capture/layout evidence reported separately. PSA-RE bits 3.4. Flag indicating availability of the trip computer field in the personal mode choice list Upstream default raw=0 (not necessarily valid data).";
CM_ SG_ 727 LightNavExportFieldAvailable "DATABASE_CANDIDATE: physical interpretation unverified; capture/layout evidence reported separately. PSA-RE bits 3.5. Flag indicating availability of the light navigation export field (CAN) in the personal mode choice list Upstream default raw=0 (not necessarily valid data).";
CM_ SG_ 727 FullNavExportFieldAvailable "DATABASE_CANDIDATE: physical interpretation unverified; capture/layout evidence reported separately. PSA-RE bits 3.6. Flag indicating availability of the full navigation export field (LVDS+CAN) in the personal mode choice list Upstream default raw=0 (not necessarily valid data).";
CM_ SG_ 727 LightMediaExportFieldAvailable "DATABASE_CANDIDATE: physical interpretation unverified; capture/layout evidence reported separately. PSA-RE bits 3.7. Flag indicating availability of the light media export field (CAN) in the personal mode choice list Upstream default raw=0 (not necessarily valid data).";
CM_ SG_ 727 FullMediaExportFieldAvailable "DATABASE_CANDIDATE: physical interpretation unverified; capture/layout evidence reported separately. PSA-RE bits 2.0. Flag indicating availability of the full media export field (LVDS+CAN) in the personal mode choice list Upstream default raw=0 (not necessarily valid data).";
CM_ SG_ 727 PowermeterFieldAvailable "DATABASE_CANDIDATE: physical interpretation unverified; capture/layout evidence reported separately. PSA-RE bits 2.1. Flag indicating availability of the power meter field in the personal mode choice list Upstream default raw=0 (not necessarily valid data).";
CM_ SG_ 727 HybridFlowFieldAvailable "DATABASE_CANDIDATE: physical interpretation unverified; capture/layout evidence reported separately. PSA-RE bits 2.2. Flag indicating availability of the hybrid energy flow field in the personal mode choice list Upstream default raw=0 (not necessarily valid data).";
CM_ SG_ 727 TempGaugesFieldAvailable "DATABASE_CANDIDATE: physical interpretation unverified; capture/layout evidence reported separately. PSA-RE bits 2.3. Flag indicating availability of the coolant/oil temperature gauges field in the personal mode choice list Upstream default raw=0 (not necessarily valid data).";
CM_ SG_ 727 GMeterFieldAvailable "DATABASE_CANDIDATE: physical interpretation unverified; capture/layout evidence reported separately. PSA-RE bits 2.4. Flag indicating availability of the G-meter field in the personal mode choice list Upstream default raw=0 (not necessarily valid data).";
CM_ SG_ 727 PowerGaugeFieldAvailable "DATABASE_CANDIDATE: physical interpretation unverified; capture/layout evidence reported separately. PSA-RE bits 2.5. Flag indicating availability of the power gauge field in the personal mode choice list Upstream default raw=0 (not necessarily valid data).";
CM_ SG_ 727 StyleDecorFieldAvailable "DATABASE_CANDIDATE: physical interpretation unverified; capture/layout evidence reported separately. PSA-RE bits 2.6. Flag indicating availability of the style/decor field in the personal mode choice list Upstream default raw=0 (not necessarily valid data).";
CM_ SG_ 727 AdasFieldAvailable "DATABASE_CANDIDATE: physical interpretation unverified; capture/layout evidence reported separately. PSA-RE bits 2.7. Flag indicating availability of the ADAS field in the personal mode choice list Upstream default raw=0 (not necessarily valid data).";
CM_ SG_ 727 TachometerFieldAvailable "DATABASE_CANDIDATE: physical interpretation unverified; capture/layout evidence reported separately. PSA-RE bits 1.0. Flag indicating availability of the engine rev counter field in the personal mode choice list Upstream default raw=0 (not necessarily valid data).";
CM_ SG_ 727 CustomImageFieldAvailable "DATABASE_CANDIDATE: physical interpretation unverified; capture/layout evidence reported separately. PSA-RE bits 1.1. Flag indicating availability of the personal picture field in the personal mode choice list Upstream default raw=0 (not necessarily valid data).";
CM_ SG_ 727 LvdsVideoFormat "DATABASE_CANDIDATE: physical interpretation unverified; capture/layout evidence reported separately. PSA-RE bits 1.3-1.2. Expected LVDS video format type for navigation Upstream default raw=0 (not necessarily valid data).";
CM_ SG_ 727 TivSettingsPageOpen "DATABASE_CANDIDATE: physical interpretation unverified; capture/layout evidence reported separately. PSA-RE bits 1.4. Speed-limit-info (TIV) settings page open state Upstream default raw=0 (not necessarily valid data).";
CM_ SG_ 727 NavDatabaseLoading "DATABASE_CANDIDATE: physical interpretation unverified; capture/layout evidence reported separately. PSA-RE bits 1.5. Navigation map database loading state Upstream default raw=0 (not necessarily valid data).";
CM_ SG_ 727 ImageStorageStatus "DATABASE_CANDIDATE: physical interpretation unverified; capture/layout evidence reported separately. PSA-RE bits 1.7-1.6. Personal background image storage status Upstream default raw=1 (not necessarily valid data).";
CM_ BO_ 731 "DATABASE_CANDIDATE: physical interpretation unverified; capture/layout evidence reported separately. INFO-DIV CAN, 125000 bit/s; CAN ID 0x2DB. PSA-RE title: CHARGE_PROGRAM_SCREEN. Charge programming screen requests: energy target, start time and charge type. Source: https://github.com/prototux/PSA-RE/blob/67f7581e7622410efdbb29c7eda3b86982b9b450/buses/AEE2010.full/LS.INFO-DIV/2DB.yml. Source sender alternatives: BTEL,MDS,OVIP; physical TX/gateway forwarding not verified. ";
CM_ SG_ 731 ChargeScheduleStartTime "DATABASE_CANDIDATE: physical interpretation unverified; capture/layout evidence reported separately. PSA-RE bits 1.2-2.0. Memorized start time of the scheduled charge Upstream default raw=0 (not necessarily valid data).";
CM_ SG_ 731 ChargeTargetLevel "DATABASE_CANDIDATE: physical interpretation unverified; capture/layout evidence reported separately. PSA-RE bits 1.4-1.3. Memorized charge target level setting Upstream default raw=1 (not necessarily valid data).";
CM_ SG_ 731 Unused1 "DATABASE_CANDIDATE: physical interpretation unverified; capture/layout evidence reported separately. PSA-RE bits 1.5. ";
CM_ SG_ 731 ChargeTypeSelection "DATABASE_CANDIDATE: physical interpretation unverified; capture/layout evidence reported separately. PSA-RE bits 1.6. Charge type menu display: immediate or deferred Upstream default raw=0 (not necessarily valid data).";
CM_ SG_ 731 ChargeScheduleMenuAvailability "DATABASE_CANDIDATE: physical interpretation unverified; capture/layout evidence reported separately. PSA-RE bits 1.7. Information about the overall availability of the charge schedule menu Upstream default raw=0 (not necessarily valid data).";
CM_ BO_ 732 "DATABASE_CANDIDATE: physical interpretation unverified; capture/layout evidence reported separately. INFO-DIV CAN, 125000 bit/s; CAN ID 0x2DC. PSA-RE title: AUDIO_EXPORT_FLOW_CONTROL. ISO-TP flow-control frame for the audio export multi-frame transfer. Source: https://github.com/prototux/PSA-RE/blob/67f7581e7622410efdbb29c7eda3b86982b9b450/buses/AEE2010.full/LS.INFO-DIV/2DC.yml. Source sender alternatives: ICSV,MATT,CMB; physical TX/gateway forwarding not verified. WIRE ISO-TP ONLY: normal addressing candidate, maximum Classical CAN DLC 8; actual DLC may be shorter. Data includes padding. No reassembly, text, DID or application-layer decoding. Original application layouts are preserved in source JSON; do not decode them at wire offsets. ";
CM_ SG_ 732 FlowPadding5 "TRANSPORT_CANDIDATE: normal-addressing ISO-TP. PSA-RE bits 8.7-8.0. ";
CM_ SG_ 732 FirstData6 "TRANSPORT_CANDIDATE: normal-addressing ISO-TP. PSA-RE bits 8.7-8.0. ";
CM_ SG_ 732 UnknownData7 "TRANSPORT_CANDIDATE: normal-addressing ISO-TP. PSA-RE bits 8.7-8.0. ";
CM_ SG_ 732 ConsecutiveData7 "TRANSPORT_CANDIDATE: normal-addressing ISO-TP. PSA-RE bits 8.7-8.0. ";
CM_ SG_ 732 SingleData7 "TRANSPORT_CANDIDATE: normal-addressing ISO-TP. PSA-RE bits 8.7-8.0. ";
CM_ SG_ 732 FlowPadding4 "TRANSPORT_CANDIDATE: normal-addressing ISO-TP. PSA-RE bits 7.7-7.0. ";
CM_ SG_ 732 FirstData5 "TRANSPORT_CANDIDATE: normal-addressing ISO-TP. PSA-RE bits 7.7-7.0. ";
CM_ SG_ 732 UnknownData6 "TRANSPORT_CANDIDATE: normal-addressing ISO-TP. PSA-RE bits 7.7-7.0. ";
CM_ SG_ 732 ConsecutiveData6 "TRANSPORT_CANDIDATE: normal-addressing ISO-TP. PSA-RE bits 7.7-7.0. ";
CM_ SG_ 732 SingleData6 "TRANSPORT_CANDIDATE: normal-addressing ISO-TP. PSA-RE bits 7.7-7.0. ";
CM_ SG_ 732 FlowPadding3 "TRANSPORT_CANDIDATE: normal-addressing ISO-TP. PSA-RE bits 6.7-6.0. ";
CM_ SG_ 732 FirstData4 "TRANSPORT_CANDIDATE: normal-addressing ISO-TP. PSA-RE bits 6.7-6.0. ";
CM_ SG_ 732 UnknownData5 "TRANSPORT_CANDIDATE: normal-addressing ISO-TP. PSA-RE bits 6.7-6.0. ";
CM_ SG_ 732 ConsecutiveData5 "TRANSPORT_CANDIDATE: normal-addressing ISO-TP. PSA-RE bits 6.7-6.0. ";
CM_ SG_ 732 SingleData5 "TRANSPORT_CANDIDATE: normal-addressing ISO-TP. PSA-RE bits 6.7-6.0. ";
CM_ SG_ 732 FlowPadding2 "TRANSPORT_CANDIDATE: normal-addressing ISO-TP. PSA-RE bits 5.7-5.0. ";
CM_ SG_ 732 FirstData3 "TRANSPORT_CANDIDATE: normal-addressing ISO-TP. PSA-RE bits 5.7-5.0. ";
CM_ SG_ 732 UnknownData4 "TRANSPORT_CANDIDATE: normal-addressing ISO-TP. PSA-RE bits 5.7-5.0. ";
CM_ SG_ 732 ConsecutiveData4 "TRANSPORT_CANDIDATE: normal-addressing ISO-TP. PSA-RE bits 5.7-5.0. ";
CM_ SG_ 732 SingleData4 "TRANSPORT_CANDIDATE: normal-addressing ISO-TP. PSA-RE bits 5.7-5.0. ";
CM_ SG_ 732 FlowPadding1 "TRANSPORT_CANDIDATE: normal-addressing ISO-TP. PSA-RE bits 4.7-4.0. ";
CM_ SG_ 732 FirstData2 "TRANSPORT_CANDIDATE: normal-addressing ISO-TP. PSA-RE bits 4.7-4.0. ";
CM_ SG_ 732 UnknownData3 "TRANSPORT_CANDIDATE: normal-addressing ISO-TP. PSA-RE bits 4.7-4.0. ";
CM_ SG_ 732 ConsecutiveData3 "TRANSPORT_CANDIDATE: normal-addressing ISO-TP. PSA-RE bits 4.7-4.0. ";
CM_ SG_ 732 SingleData3 "TRANSPORT_CANDIDATE: normal-addressing ISO-TP. PSA-RE bits 4.7-4.0. ";
CM_ SG_ 732 FirstData1 "TRANSPORT_CANDIDATE: normal-addressing ISO-TP. PSA-RE bits 3.7-3.0. ";
CM_ SG_ 732 UnknownData2 "TRANSPORT_CANDIDATE: normal-addressing ISO-TP. PSA-RE bits 3.7-3.0. ";
CM_ SG_ 732 ConsecutiveData2 "TRANSPORT_CANDIDATE: normal-addressing ISO-TP. PSA-RE bits 3.7-3.0. ";
CM_ SG_ 732 SingleData2 "TRANSPORT_CANDIDATE: normal-addressing ISO-TP. PSA-RE bits 3.7-3.0. ";
CM_ SG_ 732 SeparationTimeRaw "TRANSPORT_CANDIDATE: normal-addressing ISO-TP. PSA-RE bits 3.7-3.0. Raw STmin code; 0xF1..0xF9 are not milliseconds.";
CM_ SG_ 732 UnknownData1 "TRANSPORT_CANDIDATE: normal-addressing ISO-TP. PSA-RE bits 2.7-2.0. ";
CM_ SG_ 732 ConsecutiveData1 "TRANSPORT_CANDIDATE: normal-addressing ISO-TP. PSA-RE bits 2.7-2.0. ";
CM_ SG_ 732 SingleData1 "TRANSPORT_CANDIDATE: normal-addressing ISO-TP. PSA-RE bits 2.7-2.0. ";
CM_ SG_ 732 BlockSize "TRANSPORT_CANDIDATE: normal-addressing ISO-TP. PSA-RE bits 2.7-2.0. ";
CM_ SG_ 732 UnknownPciLow "TRANSPORT_CANDIDATE: normal-addressing ISO-TP. PSA-RE bits 1.3-1.0. ";
CM_ SG_ 732 FlowStatus "TRANSPORT_CANDIDATE: normal-addressing ISO-TP. PSA-RE bits 1.3-1.0. ";
CM_ SG_ 732 ConsecutiveSequence "TRANSPORT_CANDIDATE: normal-addressing ISO-TP. PSA-RE bits 1.3-1.0. ";
CM_ SG_ 732 FirstFrameLength "TRANSPORT_CANDIDATE: normal-addressing ISO-TP. PSA-RE bits 1.3-2.0. 12-bit declared PDU length; not a reassembled value.";
CM_ SG_ 732 SingleFrameLength "TRANSPORT_CANDIDATE: normal-addressing ISO-TP. PSA-RE bits 1.3-1.0. Declared data length; not a validity check.";
CM_ SG_ 732 IsoTpFrameType "TRANSPORT_CANDIDATE: normal-addressing ISO-TP. PSA-RE bits 1.7-1.4. PCI high nibble; normal addressing candidate.";
CM_ BO_ 735 "DATABASE_CANDIDATE: physical interpretation unverified; capture/layout evidence reported separately. INFO-DIV CAN, 125000 bit/s; CAN ID 0x2DF. PSA-RE title: EMF_PHONE. Family of frames sharing this ID: the content depends on PEERING_CODE_ENTRY_MODE Source: https://github.com/prototux/PSA-RE/blob/67f7581e7622410efdbb29c7eda3b86982b9b450/buses/AEE2010.full/LS.INFO-DIV/2DF.yml. Source sender alternatives: EMF,ICSV; physical TX/gateway forwarding not verified. WIRE ISO-TP ONLY: normal addressing candidate, maximum Classical CAN DLC 8; actual DLC may be shorter. Data includes padding. No reassembly, text, DID or application-layer decoding. Original application layouts are preserved in source JSON; do not decode them at wire offsets. ";
CM_ SG_ 735 FlowPadding5 "TRANSPORT_CANDIDATE: normal-addressing ISO-TP. PSA-RE bits 8.7-8.0. ";
CM_ SG_ 735 FirstData6 "TRANSPORT_CANDIDATE: normal-addressing ISO-TP. PSA-RE bits 8.7-8.0. ";
CM_ SG_ 735 UnknownData7 "TRANSPORT_CANDIDATE: normal-addressing ISO-TP. PSA-RE bits 8.7-8.0. ";
CM_ SG_ 735 ConsecutiveData7 "TRANSPORT_CANDIDATE: normal-addressing ISO-TP. PSA-RE bits 8.7-8.0. ";
CM_ SG_ 735 SingleData7 "TRANSPORT_CANDIDATE: normal-addressing ISO-TP. PSA-RE bits 8.7-8.0. ";
CM_ SG_ 735 FlowPadding4 "TRANSPORT_CANDIDATE: normal-addressing ISO-TP. PSA-RE bits 7.7-7.0. ";
CM_ SG_ 735 FirstData5 "TRANSPORT_CANDIDATE: normal-addressing ISO-TP. PSA-RE bits 7.7-7.0. ";
CM_ SG_ 735 UnknownData6 "TRANSPORT_CANDIDATE: normal-addressing ISO-TP. PSA-RE bits 7.7-7.0. ";
CM_ SG_ 735 ConsecutiveData6 "TRANSPORT_CANDIDATE: normal-addressing ISO-TP. PSA-RE bits 7.7-7.0. ";
CM_ SG_ 735 SingleData6 "TRANSPORT_CANDIDATE: normal-addressing ISO-TP. PSA-RE bits 7.7-7.0. ";
CM_ SG_ 735 FlowPadding3 "TRANSPORT_CANDIDATE: normal-addressing ISO-TP. PSA-RE bits 6.7-6.0. ";
CM_ SG_ 735 FirstData4 "TRANSPORT_CANDIDATE: normal-addressing ISO-TP. PSA-RE bits 6.7-6.0. ";
CM_ SG_ 735 UnknownData5 "TRANSPORT_CANDIDATE: normal-addressing ISO-TP. PSA-RE bits 6.7-6.0. ";
CM_ SG_ 735 ConsecutiveData5 "TRANSPORT_CANDIDATE: normal-addressing ISO-TP. PSA-RE bits 6.7-6.0. ";
CM_ SG_ 735 SingleData5 "TRANSPORT_CANDIDATE: normal-addressing ISO-TP. PSA-RE bits 6.7-6.0. ";
CM_ SG_ 735 FlowPadding2 "TRANSPORT_CANDIDATE: normal-addressing ISO-TP. PSA-RE bits 5.7-5.0. ";
CM_ SG_ 735 FirstData3 "TRANSPORT_CANDIDATE: normal-addressing ISO-TP. PSA-RE bits 5.7-5.0. ";
CM_ SG_ 735 UnknownData4 "TRANSPORT_CANDIDATE: normal-addressing ISO-TP. PSA-RE bits 5.7-5.0. ";
CM_ SG_ 735 ConsecutiveData4 "TRANSPORT_CANDIDATE: normal-addressing ISO-TP. PSA-RE bits 5.7-5.0. ";
CM_ SG_ 735 SingleData4 "TRANSPORT_CANDIDATE: normal-addressing ISO-TP. PSA-RE bits 5.7-5.0. ";
CM_ SG_ 735 FlowPadding1 "TRANSPORT_CANDIDATE: normal-addressing ISO-TP. PSA-RE bits 4.7-4.0. ";
CM_ SG_ 735 FirstData2 "TRANSPORT_CANDIDATE: normal-addressing ISO-TP. PSA-RE bits 4.7-4.0. ";
CM_ SG_ 735 UnknownData3 "TRANSPORT_CANDIDATE: normal-addressing ISO-TP. PSA-RE bits 4.7-4.0. ";
CM_ SG_ 735 ConsecutiveData3 "TRANSPORT_CANDIDATE: normal-addressing ISO-TP. PSA-RE bits 4.7-4.0. ";
CM_ SG_ 735 SingleData3 "TRANSPORT_CANDIDATE: normal-addressing ISO-TP. PSA-RE bits 4.7-4.0. ";
CM_ SG_ 735 FirstData1 "TRANSPORT_CANDIDATE: normal-addressing ISO-TP. PSA-RE bits 3.7-3.0. ";
CM_ SG_ 735 UnknownData2 "TRANSPORT_CANDIDATE: normal-addressing ISO-TP. PSA-RE bits 3.7-3.0. ";
CM_ SG_ 735 ConsecutiveData2 "TRANSPORT_CANDIDATE: normal-addressing ISO-TP. PSA-RE bits 3.7-3.0. ";
CM_ SG_ 735 SingleData2 "TRANSPORT_CANDIDATE: normal-addressing ISO-TP. PSA-RE bits 3.7-3.0. ";
CM_ SG_ 735 SeparationTimeRaw "TRANSPORT_CANDIDATE: normal-addressing ISO-TP. PSA-RE bits 3.7-3.0. Raw STmin code; 0xF1..0xF9 are not milliseconds.";
CM_ SG_ 735 UnknownData1 "TRANSPORT_CANDIDATE: normal-addressing ISO-TP. PSA-RE bits 2.7-2.0. ";
CM_ SG_ 735 ConsecutiveData1 "TRANSPORT_CANDIDATE: normal-addressing ISO-TP. PSA-RE bits 2.7-2.0. ";
CM_ SG_ 735 SingleData1 "TRANSPORT_CANDIDATE: normal-addressing ISO-TP. PSA-RE bits 2.7-2.0. ";
CM_ SG_ 735 BlockSize "TRANSPORT_CANDIDATE: normal-addressing ISO-TP. PSA-RE bits 2.7-2.0. ";
CM_ SG_ 735 UnknownPciLow "TRANSPORT_CANDIDATE: normal-addressing ISO-TP. PSA-RE bits 1.3-1.0. ";
CM_ SG_ 735 FlowStatus "TRANSPORT_CANDIDATE: normal-addressing ISO-TP. PSA-RE bits 1.3-1.0. ";
CM_ SG_ 735 ConsecutiveSequence "TRANSPORT_CANDIDATE: normal-addressing ISO-TP. PSA-RE bits 1.3-1.0. ";
CM_ SG_ 735 FirstFrameLength "TRANSPORT_CANDIDATE: normal-addressing ISO-TP. PSA-RE bits 1.3-2.0. 12-bit declared PDU length; not a reassembled value.";
CM_ SG_ 735 SingleFrameLength "TRANSPORT_CANDIDATE: normal-addressing ISO-TP. PSA-RE bits 1.3-1.0. Declared data length; not a validity check.";
CM_ SG_ 735 IsoTpFrameType "TRANSPORT_CANDIDATE: normal-addressing ISO-TP. PSA-RE bits 1.7-1.4. PCI high nibble; normal addressing candidate.";
CM_ BO_ 736 "DATABASE_CANDIDATE: physical interpretation unverified; capture/layout evidence reported separately. INFO-DIV CAN, 125000 bit/s; CAN ID 0x2E0. PSA-RE title: CLIMATE_PRECONDITIONING_SCHEDULE. Preconditioning (cabin climate scheduling) profile information, defined by the profile message structure. Source: https://github.com/prototux/PSA-RE/blob/67f7581e7622410efdbb29c7eda3b86982b9b450/buses/AEE2010.full/LS.INFO-DIV/2E0.yml. Source sender alternatives: BSI; physical TX/gateway forwarding not verified. Observed 1175 frames in info_apka.csv,info_buzeni_obc.csv,info_charging.csv,info_standby.csv,info_start_jizda.csv,infocan.csv; DLCs [7]. ";
CM_ SG_ 736 AcPrecondSchedule2StartTime "DATABASE_CANDIDATE: physical interpretation unverified; capture/layout evidence reported separately. PSA-RE bits 6.2-7.0. Memorized start time of climate preconditioning schedule 2, in minutes since midnight Upstream default raw=0 (not necessarily valid data).";
CM_ SG_ 736 Unused3 "DATABASE_CANDIDATE: physical interpretation unverified; capture/layout evidence reported separately. PSA-RE bits 6.7-6.3. ";
CM_ SG_ 736 AcPrecondSundaySchedule2Active "DATABASE_CANDIDATE: physical interpretation unverified; capture/layout evidence reported separately. PSA-RE bits 5.0. Memorized activation status of climate preconditioning schedule 2 for Sunday Upstream default raw=0 (not necessarily valid data).";
CM_ SG_ 736 AcPrecondSaturdaySchedule2Active "DATABASE_CANDIDATE: physical interpretation unverified; capture/layout evidence reported separately. PSA-RE bits 5.1. Memorized activation status of climate preconditioning schedule 2 for Saturday Upstream default raw=0 (not necessarily valid data).";
CM_ SG_ 736 AcPrecondFridaySchedule2Active "DATABASE_CANDIDATE: physical interpretation unverified; capture/layout evidence reported separately. PSA-RE bits 5.2. Memorized activation status of climate preconditioning schedule 2 for Friday Upstream default raw=0 (not necessarily valid data).";
CM_ SG_ 736 AcPrecondThursdaySchedule2Active "DATABASE_CANDIDATE: physical interpretation unverified; capture/layout evidence reported separately. PSA-RE bits 5.3. Memorized activation status of climate preconditioning schedule 2 for Thursday Upstream default raw=0 (not necessarily valid data).";
CM_ SG_ 736 AcPrecondWednesdaySchedul_14303b "DATABASE_CANDIDATE: physical interpretation unverified; capture/layout evidence reported separately. PSA-RE bits 5.4. Memorized activation status of climate preconditioning schedule 2 for Wednesday Upstream default raw=0 (not necessarily valid data).";
CM_ SG_ 736 AcPrecondTuesdaySchedule2Active "DATABASE_CANDIDATE: physical interpretation unverified; capture/layout evidence reported separately. PSA-RE bits 5.5. Memorized activation status of climate preconditioning schedule 2 for Tuesday Upstream default raw=0 (not necessarily valid data).";
CM_ SG_ 736 AcPrecondMondaySchedule2Active "DATABASE_CANDIDATE: physical interpretation unverified; capture/layout evidence reported separately. PSA-RE bits 5.6. Memorized activation status of climate preconditioning schedule 2 for Monday Upstream default raw=0 (not necessarily valid data).";
CM_ SG_ 736 AcPrecondSchedule2Enabled "DATABASE_CANDIDATE: physical interpretation unverified; capture/layout evidence reported separately. PSA-RE bits 5.7. Memorized global activation status of climate preconditioning schedule 2 Upstream default raw=0 (not necessarily valid data).";
CM_ SG_ 736 AcPrecondSchedule1StartTime "DATABASE_CANDIDATE: physical interpretation unverified; capture/layout evidence reported separately. PSA-RE bits 3.2-4.0. Memorized start time of climate preconditioning schedule 1, in minutes since midnight Upstream default raw=0 (not necessarily valid data).";
CM_ SG_ 736 Unused2 "DATABASE_CANDIDATE: physical interpretation unverified; capture/layout evidence reported separately. PSA-RE bits 3.7-3.3. ";
CM_ SG_ 736 AcPrecondSundaySchedule1Active "DATABASE_CANDIDATE: physical interpretation unverified; capture/layout evidence reported separately. PSA-RE bits 2.0. Memorized activation status of climate preconditioning schedule 1 for Sunday Upstream default raw=0 (not necessarily valid data).";
CM_ SG_ 736 AcPrecondSaturdaySchedule1Active "DATABASE_CANDIDATE: physical interpretation unverified; capture/layout evidence reported separately. PSA-RE bits 2.1. Memorized activation status of climate preconditioning schedule 1 for Saturday Upstream default raw=0 (not necessarily valid data).";
CM_ SG_ 736 AcPrecondFridaySchedule1Active "DATABASE_CANDIDATE: physical interpretation unverified; capture/layout evidence reported separately. PSA-RE bits 2.2. Memorized activation status of climate preconditioning schedule 1 for Friday Upstream default raw=0 (not necessarily valid data).";
CM_ SG_ 736 AcPrecondThursdaySchedule1Active "DATABASE_CANDIDATE: physical interpretation unverified; capture/layout evidence reported separately. PSA-RE bits 2.3. Memorized activation status of climate preconditioning schedule 1 for Thursday Upstream default raw=0 (not necessarily valid data).";
CM_ SG_ 736 AcPrecondWednesdaySchedul_0079d6 "DATABASE_CANDIDATE: physical interpretation unverified; capture/layout evidence reported separately. PSA-RE bits 2.4. Memorized activation status of climate preconditioning schedule 1 for Wednesday Upstream default raw=0 (not necessarily valid data).";
CM_ SG_ 736 AcPrecondTuesdaySchedule1Active "DATABASE_CANDIDATE: physical interpretation unverified; capture/layout evidence reported separately. PSA-RE bits 2.5. Memorized activation status of climate preconditioning schedule 1 for Tuesday Upstream default raw=0 (not necessarily valid data).";
CM_ SG_ 736 AcPrecondMondaySchedule1Active "DATABASE_CANDIDATE: physical interpretation unverified; capture/layout evidence reported separately. PSA-RE bits 2.6. Memorized activation status of climate preconditioning schedule 1 for Monday Upstream default raw=0 (not necessarily valid data).";
CM_ SG_ 736 AcPrecondSchedule1Enabled "DATABASE_CANDIDATE: physical interpretation unverified; capture/layout evidence reported separately. PSA-RE bits 2.7. Memorized global activation status of climate preconditioning schedule 1 Upstream default raw=0 (not necessarily valid data).";
CM_ SG_ 736 Unused1 "DATABASE_CANDIDATE: physical interpretation unverified; capture/layout evidence reported separately. PSA-RE bits 1.1-1.0.  VEHICLE_CAPTURE_OBSERVED: logs/info_precond.csv contains first-byte transitions80 ->84 ->8C after31B/C0, then88 ->80 after31B/80. ASAP bit2 changes before feedback0/1. User confirms only app acknowledgement, not physical HVAC operation. Scope: Vehicle-specific status layout from Start/Stop CAN correlation, consistent with source002 header. Only feedback0/1 observed; no physical heating, other feedback codes or other vehicle variants validated.";
CM_ SG_ 736 AcPrecondAsapModeActive "DATABASE_CANDIDATE: physical interpretation unverified; capture/layout evidence reported separately. PSA-RE bits 1.2. Accepted immediate-preconditioning request; running state is reported separately. VEHICLE_CAPTURE_OBSERVED: logs/info_precond.csv contains first-byte transitions80 ->84 ->8C after31B/C0, then88 ->80 after31B/80. ASAP bit2 changes before feedback0/1. User confirms only app acknowledgement, not physical HVAC operation. Scope: Vehicle-specific status layout from Start/Stop CAN correlation, consistent with source002 header. Only feedback0/1 observed; no physical heating, other feedback codes or other vehicle variants validated.";
CM_ SG_ 736 AcPrecondStatusFeedback "DATABASE_CANDIDATE: physical interpretation unverified; capture/layout evidence reported separately. PSA-RE bits 1.6-1.3. Preconditioning feedback; other codes unverified on this car. Layout agrees with source002 feedback. VEHICLE_CAPTURE_OBSERVED: logs/info_precond.csv contains first-byte transitions80 ->84 ->8C after31B/C0, then88 ->80 after31B/80. ASAP bit2 changes before feedback0/1. User confirms only app acknowledgement, not physical HVAC operation. Scope: Vehicle-specific status layout from Start/Stop CAN correlation, consistent with source002 header. Only feedback0/1 observed; no physical heating, other feedback codes or other vehicle variants validated.";
CM_ SG_ 736 AcPrecondStatusAvailability "DATABASE_CANDIDATE: physical interpretation unverified; capture/layout evidence reported separately. PSA-RE bits 1.7. Availability of the climate preconditioning schedule status information Upstream default raw=0 (not necessarily valid data).";
CM_ BO_ 737 "DATABASE_CANDIDATE: physical interpretation unverified; capture/layout evidence reported separately. INFO-DIV CAN, 125000 bit/s; CAN ID 0x2E1. PSA-RE title: VEHICLE_FUNCTION_CONFIG. Status of vehicle functions. Source: https://github.com/prototux/PSA-RE/blob/67f7581e7622410efdbb29c7eda3b86982b9b450/buses/AEE2010.full/LS.INFO-DIV/2E1.yml. Source sender alternatives: BSI; physical TX/gateway forwarding not verified. Observed 586 frames in info_apka.csv,info_buzeni_obc.csv,info_charging.csv,info_standby.csv,info_start_jizda.csv,infocan.csv; DLCs [6]. ";
CM_ SG_ 737 Unused2 "DATABASE_CANDIDATE: physical interpretation unverified; capture/layout evidence reported separately. PSA-RE bits 6.3-6.0. ";
CM_ SG_ 737 AsrPAvailability "DATABASE_CANDIDATE: physical interpretation unverified; capture/layout evidence reported separately. PSA-RE bits 6.4. ASR-P function availability";
CM_ SG_ 737 RetractableRoofState "DATABASE_CANDIDATE: physical interpretation unverified; capture/layout evidence reported separately. PSA-RE bits 6.7-6.5. Retractable roof state (no display, closed, or intermediate positions) Upstream default raw=0 (not necessarily valid data).";
CM_ SG_ 737 Unused1 "DATABASE_CANDIDATE: physical interpretation unverified; capture/layout evidence reported separately. PSA-RE bits 5.0. ";
CM_ SG_ 737 AsrPlusMode "DATABASE_CANDIDATE: physical interpretation unverified; capture/layout evidence reported separately. PSA-RE bits 5.3-5.1. ASR+ mode (normal/snow/mud/sand/ESP off) Upstream default raw=1 (not necessarily valid data).";
CM_ SG_ 737 SuspensionAlert "DATABASE_CANDIDATE: physical interpretation unverified; capture/layout evidence reported separately. PSA-RE bits 5.4. Suspension alert Upstream default raw=0 (not necessarily valid data).";
CM_ SG_ 737 RealSuspensionPosition "DATABASE_CANDIDATE: physical interpretation unverified; capture/layout evidence reported separately. PSA-RE bits 5.7-5.5. Actual suspension position Upstream default raw=7 (not necessarily valid data).";
CM_ SG_ 737 SuspensionMovement "DATABASE_CANDIDATE: physical interpretation unverified; capture/layout evidence reported separately. PSA-RE bits 4.1-4.0. Suspension movement (none, raising, lowering, refused) Upstream default raw=0 (not necessarily valid data).";
CM_ SG_ 737 FinalSuspensionPosition "DATABASE_CANDIDATE: physical interpretation unverified; capture/layout evidence reported separately. PSA-RE bits 4.4-4.2. Final suspension position Upstream default raw=7 (not necessarily valid data).";
CM_ SG_ 737 InitialSuspensionPosition "DATABASE_CANDIDATE: physical interpretation unverified; capture/layout evidence reported separately. PSA-RE bits 4.7-4.5. Initial suspension position Upstream default raw=7 (not necessarily valid data).";
CM_ SG_ 737 PushStartStopStatus "DATABASE_CANDIDATE: physical interpretation unverified; capture/layout evidence reported separately. PSA-RE bits 3.0. Start/stop push button status Upstream default raw=0 (not necessarily valid data).";
CM_ SG_ 737 TrunkAndConvertibleRoofStatus "DATABASE_CANDIDATE: physical interpretation unverified; capture/layout evidence reported separately. PSA-RE bits 3.3-3.1. Trunk and convertible roof position pictogram Upstream default raw=0 (not necessarily valid data).";
CM_ SG_ 737 StopStartStatus "DATABASE_CANDIDATE: physical interpretation unverified; capture/layout evidence reported separately. PSA-RE bits 3.5-3.4. Stop & Start function status Upstream default raw=0 (not necessarily valid data).";
CM_ SG_ 737 ChildSafetyRearDoorsStatus "DATABASE_CANDIDATE: physical interpretation unverified; capture/layout evidence reported separately. PSA-RE bits 3.7-3.6. Rear doors child safety lock function status Upstream default raw=0 (not necessarily valid data).";
CM_ SG_ 737 SuspensionMode "DATABASE_CANDIDATE: physical interpretation unverified; capture/layout evidence reported separately. PSA-RE bits 2.1-2.0. Suspension function status (sport/normal) Upstream default raw=0 (not necessarily valid data).";
CM_ SG_ 737 AutomaticWipingStatus "DATABASE_CANDIDATE: physical interpretation unverified; capture/layout evidence reported separately. PSA-RE bits 2.3-2.2. Automatic wiping function status Upstream default raw=0 (not necessarily valid data).";
CM_ SG_ 737 EspStatus "DATABASE_CANDIDATE: physical interpretation unverified; capture/layout evidence reported separately. PSA-RE bits 2.5-2.4. ESP function status Upstream default raw=0 (not necessarily valid data).";
CM_ SG_ 737 DoorLockingStatus "DATABASE_CANDIDATE: physical interpretation unverified; capture/layout evidence reported separately. PSA-RE bits 2.7-2.6. Door locking function status Upstream default raw=0 (not necessarily valid data).";
CM_ SG_ 737 AutomaticDoorLockingStatus "DATABASE_CANDIDATE: physical interpretation unverified; capture/layout evidence reported separately. PSA-RE bits 1.1-1.0. Automatic door locking function status Upstream default raw=0 (not necessarily valid data).";
CM_ SG_ 737 AutomaticHeadlightsStatus "DATABASE_CANDIDATE: physical interpretation unverified; capture/layout evidence reported separately. PSA-RE bits 1.3-1.2. Automatic headlights switch-on function status Upstream default raw=0 (not necessarily valid data).";
CM_ SG_ 737 PassengerAirbagStatus "DATABASE_CANDIDATE: physical interpretation unverified; capture/layout evidence reported separately. PSA-RE bits 1.5-1.4. Passenger airbag function status Upstream default raw=0 (not necessarily valid data).";
CM_ SG_ 737 ParkingAidStatus "DATABASE_CANDIDATE: physical interpretation unverified; capture/layout evidence reported separately. PSA-RE bits 1.7-1.6. Parking aid function status Upstream default raw=0 (not necessarily valid data).";
CM_ BO_ 743 "DATABASE_CANDIDATE: physical interpretation unverified; capture/layout evidence reported separately. INFO-DIV CAN, 125000 bit/s; CAN ID 0x2E7. PSA-RE title: DISPLAY_MODE_REQUEST. Display appearance/skin list data (part 1), relayed between the infotainment sources and the instrument cluster. Source: https://github.com/prototux/PSA-RE/blob/67f7581e7622410efdbb29c7eda3b86982b9b450/buses/AEE2010.full/LS.INFO-DIV/2E7.yml. Source sender alternatives: ICSV,CMB; physical TX/gateway forwarding not verified. VEHICLE_SOURCE_REVIEW: Owner reports original instrument cluster unit004 connected for info_buzeni_obc.csv and absent in earlier captures. This ID is absent in info_standby.csv and fully operational info_start_jizda.csv; upstream lists CMB among possible senders. Owner approved limiting IC attribution to these nine messages. Scope: Vehicle-specific sender attribution from installation report/capture comparison and compatible source alias; does not validate signal meanings or exclude gateway forwarding. Observed 17 frames in info_buzeni_obc.csv,info_charging.csv; DLCs [8]. ";
CM_ SG_ 743 StoredAppearanceId8 "DATABASE_CANDIDATE: physical interpretation unverified; capture/layout evidence reported separately. PSA-RE bits 8.7-8.0. Universal number of the stored appearance 8 Raw invalid=0; numeric DBC decoders may still scale it: check raw before use.";
CM_ SG_ 743 StoredAppearanceId7 "DATABASE_CANDIDATE: physical interpretation unverified; capture/layout evidence reported separately. PSA-RE bits 7.7-7.0. Universal number of the stored appearance 7 Raw invalid=0; numeric DBC decoders may still scale it: check raw before use.";
CM_ SG_ 743 StoredAppearanceId6 "DATABASE_CANDIDATE: physical interpretation unverified; capture/layout evidence reported separately. PSA-RE bits 6.7-6.0. Universal number of the stored appearance 6 Raw invalid=0; numeric DBC decoders may still scale it: check raw before use.";
CM_ SG_ 743 StoredAppearanceId5 "DATABASE_CANDIDATE: physical interpretation unverified; capture/layout evidence reported separately. PSA-RE bits 5.7-5.0. Universal number of the stored appearance 5 Raw invalid=0; numeric DBC decoders may still scale it: check raw before use.";
CM_ SG_ 743 StoredAppearanceId4 "DATABASE_CANDIDATE: physical interpretation unverified; capture/layout evidence reported separately. PSA-RE bits 4.7-4.0. Universal number of the stored appearance 4 Raw invalid=0; numeric DBC decoders may still scale it: check raw before use.";
CM_ SG_ 743 StoredAppearanceId3 "DATABASE_CANDIDATE: physical interpretation unverified; capture/layout evidence reported separately. PSA-RE bits 3.7-3.0. Universal number of the stored appearance 3 Raw invalid=0; numeric DBC decoders may still scale it: check raw before use.";
CM_ SG_ 743 StoredAppearanceId2 "DATABASE_CANDIDATE: physical interpretation unverified; capture/layout evidence reported separately. PSA-RE bits 2.7-2.0. Universal number of the stored appearance 2 Raw invalid=0; numeric DBC decoders may still scale it: check raw before use.";
CM_ SG_ 743 StoredAppearanceId1 "DATABASE_CANDIDATE: physical interpretation unverified; capture/layout evidence reported separately. PSA-RE bits 1.7-1.0. Universal number of the stored appearance 1 Raw invalid=0; numeric DBC decoders may still scale it: check raw before use.";
CM_ BO_ 744 "DATABASE_CANDIDATE: physical interpretation unverified; capture/layout evidence reported separately. INFO-DIV CAN, 125000 bit/s; CAN ID 0x2E8. PSA-RE title: ENGINE_GEARBOX_DYNAMIC_DATA. Elapsed and stopped time, and zero-emission time percentage, for the second saved trip. Source: https://github.com/prototux/PSA-RE/blob/67f7581e7622410efdbb29c7eda3b86982b9b450/buses/AEE2010.full/LS.INFO-DIV/2E8.yml. Source sender alternatives: BSI; physical TX/gateway forwarding not verified. Observed 587 frames in info_apka.csv,info_buzeni_obc.csv,info_charging.csv,info_standby.csv,info_start_jizda.csv,infocan.csv; DLCs [8]. Unresolved alternative source layouts preserved in source JSON. ";
CM_ SG_ 744 Unused4 "DATABASE_CANDIDATE: physical interpretation unverified; capture/layout evidence reported separately. PSA-RE bits 8.0. ";
CM_ SG_ 744 ZevDurationPercentTrip2Adjusted "DATABASE_CANDIDATE: physical interpretation unverified; capture/layout evidence reported separately. PSA-RE bits 8.7-8.1. Adjusted percentage of time spent in ZEV mode for trip 2 Raw invalid=127; numeric DBC decoders may still scale it: check raw before use. Upstream default raw=0 (not necessarily valid data).";
CM_ SG_ 744 Unused3 "DATABASE_CANDIDATE: physical interpretation unverified; capture/layout evidence reported separately. PSA-RE bits 7.0. ";
CM_ SG_ 744 ZevDurationPercentTrip2 "DATABASE_CANDIDATE: physical interpretation unverified; capture/layout evidence reported separately. PSA-RE bits 7.7-7.1. Percentage of time spent in ZEV mode relative to total time of trip 2 Raw invalid=127; numeric DBC decoders may still scale it: check raw before use. Upstream default raw=0 (not necessarily valid data).";
CM_ SG_ 744 Unused2 "DATABASE_CANDIDATE: physical interpretation unverified; capture/layout evidence reported separately. PSA-RE bits 6.0. ";
CM_ SG_ 744 ZevDurationSecondsTrip2 "DATABASE_CANDIDATE: physical interpretation unverified; capture/layout evidence reported separately. PSA-RE bits 6.6-6.1. Seconds component of the ZEV (engine-off) duration for trip 2 Raw invalid=63; numeric DBC decoders may still scale it: check raw before use. Upstream default raw=0 (not necessarily valid data).";
CM_ SG_ 744 ZevDurationMinutesTrip2 "DATABASE_CANDIDATE: physical interpretation unverified; capture/layout evidence reported separately. PSA-RE bits 5.4-6.7. Minutes component of the ZEV (engine-off) duration for trip 2 Raw invalid=63; numeric DBC decoders may still scale it: check raw before use. Upstream default raw=0 (not necessarily valid data).";
CM_ SG_ 744 ZevDurationHoursTrip2 "DATABASE_CANDIDATE: physical interpretation unverified; capture/layout evidence reported separately. PSA-RE bits 4.7-5.5. Hours component of the ZEV (engine-off) duration for trip 2 Raw invalid=2047; numeric DBC decoders may still scale it: check raw before use. Upstream default raw=0 (not necessarily valid data).";
CM_ SG_ 744 Unused1 "DATABASE_CANDIDATE: physical interpretation unverified; capture/layout evidence reported separately. PSA-RE bits 3.0. ";
CM_ SG_ 744 TripDurationSecondsTrip2 "DATABASE_CANDIDATE: physical interpretation unverified; capture/layout evidence reported separately. PSA-RE bits 3.6-3.1. Seconds component of the trip 2 duration Raw invalid=63; numeric DBC decoders may still scale it: check raw before use. Upstream default raw=0 (not necessarily valid data).";
CM_ SG_ 744 TripDurationMinutesTrip2 "DATABASE_CANDIDATE: physical interpretation unverified; capture/layout evidence reported separately. PSA-RE bits 2.4-3.7. Minutes component of the trip 2 duration Raw invalid=63; numeric DBC decoders may still scale it: check raw before use. Upstream default raw=0 (not necessarily valid data).";
CM_ SG_ 744 TripDurationHoursTrip2 "DATABASE_CANDIDATE: physical interpretation unverified; capture/layout evidence reported separately. PSA-RE bits 1.7-2.5. Hours component of the trip 2 duration Raw invalid=2047; numeric DBC decoders may still scale it: check raw before use. Upstream default raw=0 (not necessarily valid data).";
CM_ BO_ 745 "DATABASE_CANDIDATE: physical interpretation unverified; capture/layout evidence reported separately. INFO-DIV CAN, 125000 bit/s; CAN ID 0x2E9. PSA-RE title: GEARBOX_TORQUE_CALIBRATION. Telematics unit status: display appearance, head-up display height/brightness/fold command, personalization mode. Source: https://github.com/prototux/PSA-RE/blob/67f7581e7622410efdbb29c7eda3b86982b9b450/buses/AEE2010.full/LS.INFO-DIV/2E9.yml. Source sender alternatives: BTEL,OVIP; physical TX/gateway forwarding not verified. Observed 2947 frames in info_apka.csv,info_buzeni_obc.csv,info_charging.csv,info_standby.csv,info_start_jizda.csv,infocan.csv; DLCs [4]. ";
CM_ SG_ 745 Unused2 "DATABASE_CANDIDATE: physical interpretation unverified; capture/layout evidence reported separately. PSA-RE bits 4.2-4.0. ";
CM_ SG_ 745 HudFoldUnfoldRequest "DATABASE_CANDIDATE: physical interpretation unverified; capture/layout evidence reported separately. PSA-RE bits 4.3. Head-up display (HUD) folding/unfolding request Upstream default raw=0 (not necessarily valid data).";
CM_ SG_ 745 HudBrightnessAdjustmentRequest "DATABASE_CANDIDATE: physical interpretation unverified; capture/layout evidence reported separately. PSA-RE bits 4.5-4.4. Head-up display (HUD) brightness adjustment request Upstream default raw=0 (not necessarily valid data).";
CM_ SG_ 745 HudHeightAdjustmentRequest "DATABASE_CANDIDATE: physical interpretation unverified; capture/layout evidence reported separately. PSA-RE bits 4.7-4.6. Head-up display (HUD) height adjustment request Upstream default raw=0 (not necessarily valid data).";
CM_ SG_ 745 Unused1 "DATABASE_CANDIDATE: physical interpretation unverified; capture/layout evidence reported separately. PSA-RE bits 3.2-3.0. ";
CM_ SG_ 745 DisplayPersonalMode2Choice "DATABASE_CANDIDATE: physical interpretation unverified; capture/layout evidence reported separately. PSA-RE bits 3.7-3.3. Customer's personal display mode choice for display slot 2 Upstream default raw=0 (not necessarily valid data).";
CM_ SG_ 745 DisplayPersonalModeActive "DATABASE_CANDIDATE: physical interpretation unverified; capture/layout evidence reported separately. PSA-RE bits 2.0. Personal display mode active Upstream default raw=0 (not necessarily valid data).";
CM_ SG_ 745 DisplayPersonalMode1Choice "DATABASE_CANDIDATE: physical interpretation unverified; capture/layout evidence reported separately. PSA-RE bits 2.5-2.1. Customer's personal display mode choice for display slot 1 Upstream default raw=0 (not necessarily valid data).";
CM_ SG_ 745 PolysensorialModeActive "DATABASE_CANDIDATE: physical interpretation unverified; capture/layout evidence reported separately. PSA-RE bits 2.7-2.6. Currently active polysensorial mode Upstream default raw=0 (not necessarily valid data).";
CM_ SG_ 745 CmbAppearance "DATABASE_CANDIDATE: physical interpretation unverified; capture/layout evidence reported separately. PSA-RE bits 1.7-1.0. Instrument cluster (CMB) appearance setting Raw invalid=255; numeric DBC decoders may still scale it: check raw before use. Upstream default raw=1 (not necessarily valid data).";
CM_ BO_ 769 "DATABASE_CANDIDATE: physical interpretation unverified; capture/layout evidence reported separately. INFO-DIV CAN, 125000 bit/s; CAN ID 0x301. PSA-RE title: SDCM_TRANSMITTER_DATA. Badge number and connection/inventory requests of the SDCM transmitter Source: https://github.com/prototux/PSA-RE/blob/67f7581e7622410efdbb29c7eda3b86982b9b450/buses/AEE2010.full/LS.INFO-DIV/301.yml. Source sender alternatives: SDCM; physical TX/gateway forwarding not verified. ";
CM_ SG_ 769 Unused2 "DATABASE_CANDIDATE: physical interpretation unverified; capture/layout evidence reported separately. PSA-RE bits 3.7-8.0. ";
CM_ SG_ 769 SdcmBadgeNumber "DATABASE_CANDIDATE: physical interpretation unverified; capture/layout evidence reported separately. PSA-RE bits 2.7-2.0. Badge number detected during the NFC inventory phase Upstream default raw=0 (not necessarily valid data).";
CM_ SG_ 769 SdcmNfcInventoryRequest "DATABASE_CANDIDATE: physical interpretation unverified; capture/layout evidence reported separately. PSA-RE bits 1.0. Request to collect devices during the NFC anti-collision phase (ISO 14443) Upstream default raw=0 (not necessarily valid data).";
CM_ SG_ 769 SdcmNfcConnectRequest "DATABASE_CANDIDATE: physical interpretation unverified; capture/layout evidence reported separately. PSA-RE bits 1.1. Connection request to a specific NFC device Upstream default raw=0 (not necessarily valid data).";
CM_ SG_ 769 Unused1 "DATABASE_CANDIDATE: physical interpretation unverified; capture/layout evidence reported separately. PSA-RE bits 1.7-1.2. ";
CM_ BO_ 771 "DATABASE_CANDIDATE: physical interpretation unverified; capture/layout evidence reported separately. INFO-DIV CAN, 125000 bit/s; CAN ID 0x303. PSA-RE title: ODI_ACTION_BUFFER. Opaque data buffer of the embedded diagnostics interface (ODI) between the telematics unit and the diagnostic tool: generic action data. Source: https://github.com/prototux/PSA-RE/blob/67f7581e7622410efdbb29c7eda3b86982b9b450/buses/AEE2010.full/LS.INFO-DIV/303.yml. Source sender alternatives: BTEL; physical TX/gateway forwarding not verified. ";
CM_ SG_ 771 OdiActionCenterstackBuffer "DATABASE_CANDIDATE: physical interpretation unverified; capture/layout evidence reported separately. PSA-RE bits 1.7-8.0. Open Display Interface (ODI) action buffer for the center stack display";
CM_ BO_ 773 "DATABASE_CANDIDATE: physical interpretation unverified; capture/layout evidence reported separately. INFO-DIV CAN, 125000 bit/s; CAN ID 0x305. PSA-RE title: STEERING_WHEEL_ANGLE. Multi-frame payload carrying the dashcam's recorded video list to the display. Source: https://github.com/prototux/PSA-RE/blob/67f7581e7622410efdbb29c7eda3b86982b9b450/buses/AEE2010.full/LS.INFO-DIV/305.yml. Source sender alternatives: IDVR; physical TX/gateway forwarding not verified. WIRE ISO-TP ONLY: normal addressing candidate, maximum Classical CAN DLC 8; actual DLC may be shorter. Data includes padding. No reassembly, text, DID or application-layer decoding. Original application layouts are preserved in source JSON; do not decode them at wire offsets. Unresolved alternative source layouts preserved in source JSON. ";
CM_ SG_ 773 FlowPadding5 "TRANSPORT_CANDIDATE: normal-addressing ISO-TP. PSA-RE bits 8.7-8.0. ";
CM_ SG_ 773 FirstData6 "TRANSPORT_CANDIDATE: normal-addressing ISO-TP. PSA-RE bits 8.7-8.0. ";
CM_ SG_ 773 UnknownData7 "TRANSPORT_CANDIDATE: normal-addressing ISO-TP. PSA-RE bits 8.7-8.0. ";
CM_ SG_ 773 ConsecutiveData7 "TRANSPORT_CANDIDATE: normal-addressing ISO-TP. PSA-RE bits 8.7-8.0. ";
CM_ SG_ 773 SingleData7 "TRANSPORT_CANDIDATE: normal-addressing ISO-TP. PSA-RE bits 8.7-8.0. ";
CM_ SG_ 773 FlowPadding4 "TRANSPORT_CANDIDATE: normal-addressing ISO-TP. PSA-RE bits 7.7-7.0. ";
CM_ SG_ 773 FirstData5 "TRANSPORT_CANDIDATE: normal-addressing ISO-TP. PSA-RE bits 7.7-7.0. ";
CM_ SG_ 773 UnknownData6 "TRANSPORT_CANDIDATE: normal-addressing ISO-TP. PSA-RE bits 7.7-7.0. ";
CM_ SG_ 773 ConsecutiveData6 "TRANSPORT_CANDIDATE: normal-addressing ISO-TP. PSA-RE bits 7.7-7.0. ";
CM_ SG_ 773 SingleData6 "TRANSPORT_CANDIDATE: normal-addressing ISO-TP. PSA-RE bits 7.7-7.0. ";
CM_ SG_ 773 FlowPadding3 "TRANSPORT_CANDIDATE: normal-addressing ISO-TP. PSA-RE bits 6.7-6.0. ";
CM_ SG_ 773 FirstData4 "TRANSPORT_CANDIDATE: normal-addressing ISO-TP. PSA-RE bits 6.7-6.0. ";
CM_ SG_ 773 UnknownData5 "TRANSPORT_CANDIDATE: normal-addressing ISO-TP. PSA-RE bits 6.7-6.0. ";
CM_ SG_ 773 ConsecutiveData5 "TRANSPORT_CANDIDATE: normal-addressing ISO-TP. PSA-RE bits 6.7-6.0. ";
CM_ SG_ 773 SingleData5 "TRANSPORT_CANDIDATE: normal-addressing ISO-TP. PSA-RE bits 6.7-6.0. ";
CM_ SG_ 773 FlowPadding2 "TRANSPORT_CANDIDATE: normal-addressing ISO-TP. PSA-RE bits 5.7-5.0. ";
CM_ SG_ 773 FirstData3 "TRANSPORT_CANDIDATE: normal-addressing ISO-TP. PSA-RE bits 5.7-5.0. ";
CM_ SG_ 773 UnknownData4 "TRANSPORT_CANDIDATE: normal-addressing ISO-TP. PSA-RE bits 5.7-5.0. ";
CM_ SG_ 773 ConsecutiveData4 "TRANSPORT_CANDIDATE: normal-addressing ISO-TP. PSA-RE bits 5.7-5.0. ";
CM_ SG_ 773 SingleData4 "TRANSPORT_CANDIDATE: normal-addressing ISO-TP. PSA-RE bits 5.7-5.0. ";
CM_ SG_ 773 FlowPadding1 "TRANSPORT_CANDIDATE: normal-addressing ISO-TP. PSA-RE bits 4.7-4.0. ";
CM_ SG_ 773 FirstData2 "TRANSPORT_CANDIDATE: normal-addressing ISO-TP. PSA-RE bits 4.7-4.0. ";
CM_ SG_ 773 UnknownData3 "TRANSPORT_CANDIDATE: normal-addressing ISO-TP. PSA-RE bits 4.7-4.0. ";
CM_ SG_ 773 ConsecutiveData3 "TRANSPORT_CANDIDATE: normal-addressing ISO-TP. PSA-RE bits 4.7-4.0. ";
CM_ SG_ 773 SingleData3 "TRANSPORT_CANDIDATE: normal-addressing ISO-TP. PSA-RE bits 4.7-4.0. ";
CM_ SG_ 773 FirstData1 "TRANSPORT_CANDIDATE: normal-addressing ISO-TP. PSA-RE bits 3.7-3.0. ";
CM_ SG_ 773 UnknownData2 "TRANSPORT_CANDIDATE: normal-addressing ISO-TP. PSA-RE bits 3.7-3.0. ";
CM_ SG_ 773 ConsecutiveData2 "TRANSPORT_CANDIDATE: normal-addressing ISO-TP. PSA-RE bits 3.7-3.0. ";
CM_ SG_ 773 SingleData2 "TRANSPORT_CANDIDATE: normal-addressing ISO-TP. PSA-RE bits 3.7-3.0. ";
CM_ SG_ 773 SeparationTimeRaw "TRANSPORT_CANDIDATE: normal-addressing ISO-TP. PSA-RE bits 3.7-3.0. Raw STmin code; 0xF1..0xF9 are not milliseconds.";
CM_ SG_ 773 UnknownData1 "TRANSPORT_CANDIDATE: normal-addressing ISO-TP. PSA-RE bits 2.7-2.0. ";
CM_ SG_ 773 ConsecutiveData1 "TRANSPORT_CANDIDATE: normal-addressing ISO-TP. PSA-RE bits 2.7-2.0. ";
CM_ SG_ 773 SingleData1 "TRANSPORT_CANDIDATE: normal-addressing ISO-TP. PSA-RE bits 2.7-2.0. ";
CM_ SG_ 773 BlockSize "TRANSPORT_CANDIDATE: normal-addressing ISO-TP. PSA-RE bits 2.7-2.0. ";
CM_ SG_ 773 UnknownPciLow "TRANSPORT_CANDIDATE: normal-addressing ISO-TP. PSA-RE bits 1.3-1.0. ";
CM_ SG_ 773 FlowStatus "TRANSPORT_CANDIDATE: normal-addressing ISO-TP. PSA-RE bits 1.3-1.0. ";
CM_ SG_ 773 ConsecutiveSequence "TRANSPORT_CANDIDATE: normal-addressing ISO-TP. PSA-RE bits 1.3-1.0. ";
CM_ SG_ 773 FirstFrameLength "TRANSPORT_CANDIDATE: normal-addressing ISO-TP. PSA-RE bits 1.3-2.0. 12-bit declared PDU length; not a reassembled value.";
CM_ SG_ 773 SingleFrameLength "TRANSPORT_CANDIDATE: normal-addressing ISO-TP. PSA-RE bits 1.3-1.0. Declared data length; not a validity check.";
CM_ SG_ 773 IsoTpFrameType "TRANSPORT_CANDIDATE: normal-addressing ISO-TP. PSA-RE bits 1.7-1.4. PCI high nibble; normal addressing candidate.";
CM_ BO_ 788 "DATABASE_CANDIDATE: physical interpretation unverified; capture/layout evidence reported separately. INFO-DIV CAN, 125000 bit/s; CAN ID 0x314. PSA-RE title: REMOTE_TELEMATICS_ORDER. Remote command sent from the diagnostic/telematics tool, with packet counter and reference number. Source: https://github.com/prototux/PSA-RE/blob/67f7581e7622410efdbb29c7eda3b86982b9b450/buses/AEE2010.full/LS.INFO-DIV/314.yml. Source sender alternatives: MDS; physical TX/gateway forwarding not verified. WIRE ISO-TP ONLY: normal addressing candidate, maximum Classical CAN DLC 8; actual DLC may be shorter. Data includes padding. No reassembly, text, DID or application-layer decoding. Original application layouts are preserved in source JSON; do not decode them at wire offsets. ";
CM_ SG_ 788 FlowPadding5 "TRANSPORT_CANDIDATE: normal-addressing ISO-TP. PSA-RE bits 8.7-8.0. ";
CM_ SG_ 788 FirstData6 "TRANSPORT_CANDIDATE: normal-addressing ISO-TP. PSA-RE bits 8.7-8.0. ";
CM_ SG_ 788 UnknownData7 "TRANSPORT_CANDIDATE: normal-addressing ISO-TP. PSA-RE bits 8.7-8.0. ";
CM_ SG_ 788 ConsecutiveData7 "TRANSPORT_CANDIDATE: normal-addressing ISO-TP. PSA-RE bits 8.7-8.0. ";
CM_ SG_ 788 SingleData7 "TRANSPORT_CANDIDATE: normal-addressing ISO-TP. PSA-RE bits 8.7-8.0. ";
CM_ SG_ 788 FlowPadding4 "TRANSPORT_CANDIDATE: normal-addressing ISO-TP. PSA-RE bits 7.7-7.0. ";
CM_ SG_ 788 FirstData5 "TRANSPORT_CANDIDATE: normal-addressing ISO-TP. PSA-RE bits 7.7-7.0. ";
CM_ SG_ 788 UnknownData6 "TRANSPORT_CANDIDATE: normal-addressing ISO-TP. PSA-RE bits 7.7-7.0. ";
CM_ SG_ 788 ConsecutiveData6 "TRANSPORT_CANDIDATE: normal-addressing ISO-TP. PSA-RE bits 7.7-7.0. ";
CM_ SG_ 788 SingleData6 "TRANSPORT_CANDIDATE: normal-addressing ISO-TP. PSA-RE bits 7.7-7.0. ";
CM_ SG_ 788 FlowPadding3 "TRANSPORT_CANDIDATE: normal-addressing ISO-TP. PSA-RE bits 6.7-6.0. ";
CM_ SG_ 788 FirstData4 "TRANSPORT_CANDIDATE: normal-addressing ISO-TP. PSA-RE bits 6.7-6.0. ";
CM_ SG_ 788 UnknownData5 "TRANSPORT_CANDIDATE: normal-addressing ISO-TP. PSA-RE bits 6.7-6.0. ";
CM_ SG_ 788 ConsecutiveData5 "TRANSPORT_CANDIDATE: normal-addressing ISO-TP. PSA-RE bits 6.7-6.0. ";
CM_ SG_ 788 SingleData5 "TRANSPORT_CANDIDATE: normal-addressing ISO-TP. PSA-RE bits 6.7-6.0. ";
CM_ SG_ 788 FlowPadding2 "TRANSPORT_CANDIDATE: normal-addressing ISO-TP. PSA-RE bits 5.7-5.0. ";
CM_ SG_ 788 FirstData3 "TRANSPORT_CANDIDATE: normal-addressing ISO-TP. PSA-RE bits 5.7-5.0. ";
CM_ SG_ 788 UnknownData4 "TRANSPORT_CANDIDATE: normal-addressing ISO-TP. PSA-RE bits 5.7-5.0. ";
CM_ SG_ 788 ConsecutiveData4 "TRANSPORT_CANDIDATE: normal-addressing ISO-TP. PSA-RE bits 5.7-5.0. ";
CM_ SG_ 788 SingleData4 "TRANSPORT_CANDIDATE: normal-addressing ISO-TP. PSA-RE bits 5.7-5.0. ";
CM_ SG_ 788 FlowPadding1 "TRANSPORT_CANDIDATE: normal-addressing ISO-TP. PSA-RE bits 4.7-4.0. ";
CM_ SG_ 788 FirstData2 "TRANSPORT_CANDIDATE: normal-addressing ISO-TP. PSA-RE bits 4.7-4.0. ";
CM_ SG_ 788 UnknownData3 "TRANSPORT_CANDIDATE: normal-addressing ISO-TP. PSA-RE bits 4.7-4.0. ";
CM_ SG_ 788 ConsecutiveData3 "TRANSPORT_CANDIDATE: normal-addressing ISO-TP. PSA-RE bits 4.7-4.0. ";
CM_ SG_ 788 SingleData3 "TRANSPORT_CANDIDATE: normal-addressing ISO-TP. PSA-RE bits 4.7-4.0. ";
CM_ SG_ 788 FirstData1 "TRANSPORT_CANDIDATE: normal-addressing ISO-TP. PSA-RE bits 3.7-3.0. ";
CM_ SG_ 788 UnknownData2 "TRANSPORT_CANDIDATE: normal-addressing ISO-TP. PSA-RE bits 3.7-3.0. ";
CM_ SG_ 788 ConsecutiveData2 "TRANSPORT_CANDIDATE: normal-addressing ISO-TP. PSA-RE bits 3.7-3.0. ";
CM_ SG_ 788 SingleData2 "TRANSPORT_CANDIDATE: normal-addressing ISO-TP. PSA-RE bits 3.7-3.0. ";
CM_ SG_ 788 SeparationTimeRaw "TRANSPORT_CANDIDATE: normal-addressing ISO-TP. PSA-RE bits 3.7-3.0. Raw STmin code; 0xF1..0xF9 are not milliseconds.";
CM_ SG_ 788 UnknownData1 "TRANSPORT_CANDIDATE: normal-addressing ISO-TP. PSA-RE bits 2.7-2.0. ";
CM_ SG_ 788 ConsecutiveData1 "TRANSPORT_CANDIDATE: normal-addressing ISO-TP. PSA-RE bits 2.7-2.0. ";
CM_ SG_ 788 SingleData1 "TRANSPORT_CANDIDATE: normal-addressing ISO-TP. PSA-RE bits 2.7-2.0. ";
CM_ SG_ 788 BlockSize "TRANSPORT_CANDIDATE: normal-addressing ISO-TP. PSA-RE bits 2.7-2.0. ";
CM_ SG_ 788 UnknownPciLow "TRANSPORT_CANDIDATE: normal-addressing ISO-TP. PSA-RE bits 1.3-1.0. ";
CM_ SG_ 788 FlowStatus "TRANSPORT_CANDIDATE: normal-addressing ISO-TP. PSA-RE bits 1.3-1.0. ";
CM_ SG_ 788 ConsecutiveSequence "TRANSPORT_CANDIDATE: normal-addressing ISO-TP. PSA-RE bits 1.3-1.0. ";
CM_ SG_ 788 FirstFrameLength "TRANSPORT_CANDIDATE: normal-addressing ISO-TP. PSA-RE bits 1.3-2.0. 12-bit declared PDU length; not a reassembled value.";
CM_ SG_ 788 SingleFrameLength "TRANSPORT_CANDIDATE: normal-addressing ISO-TP. PSA-RE bits 1.3-1.0. Declared data length; not a validity check.";
CM_ SG_ 788 IsoTpFrameType "TRANSPORT_CANDIDATE: normal-addressing ISO-TP. PSA-RE bits 1.7-1.4. PCI high nibble; normal addressing candidate.";
CM_ BO_ 791 "DATABASE_CANDIDATE: physical interpretation unverified; capture/layout evidence reported separately. INFO-DIV CAN, 125000 bit/s; CAN ID 0x317. PSA-RE title: CMB_CONFIG. Instrument cluster telltale lamp configuration: which fault/status indicators are fitted (ABS, ASR, steering assist, parking radar, battery, seatbelt, etc.). Source: https://github.com/prototux/PSA-RE/blob/67f7581e7622410efdbb29c7eda3b86982b9b450/buses/AEE2010.full/LS.INFO-DIV/317.yml. Source sender alternatives: CMB; physical TX/gateway forwarding not verified. VEHICLE_SOURCE_REVIEW: Owner reports original instrument cluster unit004 connected for info_buzeni_obc.csv and absent in earlier captures. This ID is absent in info_standby.csv and fully operational info_start_jizda.csv; upstream lists CMB among possible senders. Owner approved limiting IC attribution to these nine messages. Scope: Vehicle-specific sender attribution from installation report/capture comparison and compatible source alias; does not validate signal meanings or exclude gateway forwarding. Observed 410 frames in info_buzeni_obc.csv,info_charging.csv; DLCs [5]. SOURCE_DLC_MISMATCH: source 8, observed/exported 5. Fitting fields retained; additional bytes raw. Unresolved alternative source layouts preserved in source JSON. ";
CM_ SG_ 791 Unused2 "DATABASE_CANDIDATE: physical interpretation unverified; capture/layout evidence reported separately. PSA-RE bits 5.3-5.0. ";
CM_ SG_ 791 IndicatorBatteryPresent "DATABASE_CANDIDATE: physical interpretation unverified; capture/layout evidence reported separately. PSA-RE bits 5.4. Battery charge fault indicator light fitted";
CM_ SG_ 791 IndicatorSamPresent "DATABASE_CANDIDATE: physical interpretation unverified; capture/layout evidence reported separately. PSA-RE bits 5.5. Parking space measurement function indicator light fitted";
CM_ SG_ 791 Unused1 "DATABASE_CANDIDATE: physical interpretation unverified; capture/layout evidence reported separately. PSA-RE bits 5.6. ";
CM_ SG_ 791 PassiveSafetyPresent "DATABASE_CANDIDATE: physical interpretation unverified; capture/layout evidence reported separately. PSA-RE bits 5.7. Passive safety system fault indicator light fitted";
CM_ SG_ 791 IndicatorBrakePressedPresent "DATABASE_CANDIDATE: physical interpretation unverified; capture/layout evidence reported separately. PSA-RE bits 4.0. Brake pedal pressed indicator light fitted";
CM_ SG_ 791 IndicatorFse2Present "DATABASE_CANDIDATE: physical interpretation unverified; capture/layout evidence reported separately. PSA-RE bits 4.1. Electric safety brake (FSE) application fault indicator light fitted";
CM_ SG_ 791 IndicatorFsePresent "DATABASE_CANDIDATE: physical interpretation unverified; capture/layout evidence reported separately. PSA-RE bits 4.2. Electric safety brake (FSE) system fault indicator light fitted";
CM_ SG_ 791 StartIndicatorPresence "DATABASE_CANDIDATE: physical interpretation unverified; capture/layout evidence reported separately. PSA-RE bits 4.3. Presence of the \"+ START\" indicator lamp Upstream default raw=0 (not necessarily valid data).";
CM_ SG_ 791 IndicatorBrakesPresent "DATABASE_CANDIDATE: physical interpretation unverified; capture/layout evidence reported separately. PSA-RE bits 4.4. Brake pad wear fault indicator light fitted";
CM_ SG_ 791 IndicatorStopAndStartPresent "DATABASE_CANDIDATE: physical interpretation unverified; capture/layout evidence reported separately. PSA-RE bits 4.5. Stop & Start indicator light fitted";
CM_ SG_ 791 IndicatorEspPresent "DATABASE_CANDIDATE: physical interpretation unverified; capture/layout evidence reported separately. PSA-RE bits 4.6. ESP/ASR fault indicator light fitted";
CM_ SG_ 791 IndicatorAbsPresent "DATABASE_CANDIDATE: physical interpretation unverified; capture/layout evidence reported separately. PSA-RE bits 4.7. ABS/EHB fault indicator light fitted";
CM_ SG_ 791 SuspensionFaultPresent "DATABASE_CANDIDATE: physical interpretation unverified; capture/layout evidence reported separately. PSA-RE bits 3.0. Serious suspension fault indicator light fitted";
CM_ SG_ 791 ElectricParkingBrakeFaultPresent "DATABASE_CANDIDATE: physical interpretation unverified; capture/layout evidence reported separately. PSA-RE bits 3.1. Electronic brake force distribution (EBD) fault indicator light fitted Upstream default raw=0 (not necessarily valid data).";
CM_ SG_ 791 IndicatorFapPresent "DATABASE_CANDIDATE: physical interpretation unverified; capture/layout evidence reported separately. PSA-RE bits 3.2. Particulate filter indicator light fitted Upstream default raw=0 (not necessarily valid data).";
CM_ SG_ 791 IndicatorEnginePresent "DATABASE_CANDIDATE: physical interpretation unverified; capture/layout evidence reported separately. PSA-RE bits 3.3. Engine control fault (ECM) indicator light fitted";
CM_ SG_ 791 IndicatorWheelsPuncturePresent "DATABASE_CANDIDATE: physical interpretation unverified; capture/layout evidence reported separately. PSA-RE bits 3.4. Tyre puncture alert indicator light fitted";
CM_ SG_ 791 IndicatorWheelsPresurePresent "DATABASE_CANDIDATE: physical interpretation unverified; capture/layout evidence reported separately. PSA-RE bits 3.5. Tyre underinflation alert indicator light fitted";
CM_ SG_ 791 IndicatorFseDisabledPresent "DATABASE_CANDIDATE: physical interpretation unverified; capture/layout evidence reported separately. PSA-RE bits 3.6. Electric safety brake (FSE) disabled indicator light fitted";
CM_ SG_ 791 IndicatorHydroLevelPresent "DATABASE_CANDIDATE: physical interpretation unverified; capture/layout evidence reported separately. PSA-RE bits 3.7. Hydraulic/brake fluid level alert indicator light fitted";
CM_ SG_ 791 IndicatorOilPressurePresent "DATABASE_CANDIDATE: physical interpretation unverified; capture/layout evidence reported separately. PSA-RE bits 2.0. Oil pressure alert indicator light fitted";
CM_ SG_ 791 IndicatorGasoilWaterPresent "DATABASE_CANDIDATE: physical interpretation unverified; capture/layout evidence reported separately. PSA-RE bits 2.1. Water in diesel fuel filter indicator light fitted";
CM_ SG_ 791 IndicatorCoolantLevelPresent "DATABASE_CANDIDATE: physical interpretation unverified; capture/layout evidence reported separately. PSA-RE bits 2.2. Coolant level alert indicator light fitted";
CM_ SG_ 791 IndicatorOilTempPresent "DATABASE_CANDIDATE: physical interpretation unverified; capture/layout evidence reported separately. PSA-RE bits 2.3. Oil temperature alert indicator light fitted Upstream default raw=0 (not necessarily valid data).";
CM_ SG_ 791 IndicatorCoolantTempPresent "DATABASE_CANDIDATE: physical interpretation unverified; capture/layout evidence reported separately. PSA-RE bits 2.4. Coolant temperature alert indicator light fitted Upstream default raw=0 (not necessarily valid data).";
CM_ SG_ 791 IndicatorAlternatorPresent "DATABASE_CANDIDATE: physical interpretation unverified; capture/layout evidence reported separately. PSA-RE bits 2.5. Alternator fault indicator light fitted";
CM_ SG_ 791 IndicatorDsgFaultPresent "DATABASE_CANDIDATE: physical interpretation unverified; capture/layout evidence reported separately. PSA-RE bits 2.6. Tyre pressure monitoring fault indicator light fitted";
CM_ SG_ 791 IndicatorDoorsOpenPresent "DATABASE_CANDIDATE: physical interpretation unverified; capture/layout evidence reported separately. PSA-RE bits 2.7. Door open indicator light fitted";
CM_ SG_ 791 IndicatorStopPresent "DATABASE_CANDIDATE: physical interpretation unverified; capture/layout evidence reported separately. PSA-RE bits 1.0. STOP warning indicator light fitted";
CM_ SG_ 791 IndicatorErrorPresent "DATABASE_CANDIDATE: physical interpretation unverified; capture/layout evidence reported separately. PSA-RE bits 1.1. Service required indicator light fitted";
CM_ SG_ 791 CaarIndicatorPresent "DATABASE_CANDIDATE: physical interpretation unverified; capture/layout evidence reported separately. PSA-RE bits 1.2. Automatic ride-height correction fault indicator light fitted";
CM_ SG_ 791 IndicatorFuelLineBlockedPresent "DATABASE_CANDIDATE: physical interpretation unverified; capture/layout evidence reported separately. PSA-RE bits 1.3. Fuel line cut-off indicator light fitted";
CM_ SG_ 791 IndicatorFuelReservePresent "DATABASE_CANDIDATE: physical interpretation unverified; capture/layout evidence reported separately. PSA-RE bits 1.4. Low fuel level indicator light fitted";
CM_ SG_ 791 IndicatorParkingBrakePresent "DATABASE_CANDIDATE: physical interpretation unverified; capture/layout evidence reported separately. PSA-RE bits 1.5. Parking brake indicator light fitted";
CM_ SG_ 791 IndicatorDaePresent "DATABASE_CANDIDATE: physical interpretation unverified; capture/layout evidence reported separately. PSA-RE bits 1.6. Power steering fault indicator light fitted";
CM_ SG_ 791 IndicatorPassengerAirbagPresent "DATABASE_CANDIDATE: physical interpretation unverified; capture/layout evidence reported separately. PSA-RE bits 1.7. Passenger airbag deactivated indicator light fitted";
CM_ BO_ 794 "DATABASE_CANDIDATE: physical interpretation unverified; capture/layout evidence reported separately. INFO-DIV CAN, 125000 bit/s; CAN ID 0x31A. PSA-RE title: ZEV_TRIP_INFO. Zero-emission driving trip-computer data: range, instant/average consumption in electric mode and charging time remaining. Source: https://github.com/prototux/PSA-RE/blob/67f7581e7622410efdbb29c7eda3b86982b9b450/buses/AEE2010.full/LS.INFO-DIV/31A.yml. Source sender alternatives: BSI; physical TX/gateway forwarding not verified. Observed 587 frames in info_apka.csv,info_buzeni_obc.csv,info_charging.csv,info_standby.csv,info_start_jizda.csv,infocan.csv; DLCs [8]. Unresolved alternative source layouts preserved in source JSON. ";
CM_ SG_ 794 Unused1 "DATABASE_CANDIDATE: physical interpretation unverified; capture/layout evidence reported separately. PSA-RE bits 8.1-8.0. ";
CM_ SG_ 794 ChargingType "DATABASE_CANDIDATE: physical interpretation unverified; capture/layout evidence reported separately. PSA-RE bits 8.2. Charging type: immediate or postponed Upstream default raw=0 (not necessarily valid data).";
CM_ SG_ 794 ScheduledChargingStartTime "DATABASE_CANDIDATE: physical interpretation unverified; capture/layout evidence reported separately. PSA-RE bits 7.5-8.3. Scheduled charging start time Upstream default raw=2047 (not necessarily valid data).";
CM_ SG_ 794 ChargeRemainingTime "DATABASE_CANDIDATE: physical interpretation unverified; capture/layout evidence reported separately. PSA-RE bits 6.4-7.6. Remaining electric charging time Upstream default raw=127 (not necessarily valid data).";
CM_ SG_ 794 ZevInstantConsumption "DATABASE_CANDIDATE: physical interpretation unverified; capture/layout evidence reported separately. PSA-RE bits 5.5-6.5. Instantaneous consumption in ZEV mode Raw invalid=511; numeric DBC decoders may still scale it: check raw before use. Upstream default raw=511 (not necessarily valid data).";
CM_ SG_ 794 ZevAverageConsumptionTrip2 "DATABASE_CANDIDATE: physical interpretation unverified; capture/layout evidence reported separately. PSA-RE bits 4.6-5.6. Average ZEV-mode consumption for trip 2 Raw invalid=511; numeric DBC decoders may still scale it: check raw before use. Upstream default raw=511 (not necessarily valid data).";
CM_ SG_ 794 ZevAverageConsumptionTrip1 "DATABASE_CANDIDATE: physical interpretation unverified; capture/layout evidence reported separately. PSA-RE bits 3.7-4.7. Average ZEV-mode consumption for trip 1 Raw invalid=511; numeric DBC decoders may still scale it: check raw before use. Upstream default raw=511 (not necessarily valid data).";
CM_ SG_ 794 ZevPercentage "DATABASE_CANDIDATE: physical interpretation unverified; capture/layout evidence reported separately. PSA-RE bits 2.6-2.0. Percentage of driving in ZEV mode Raw invalid=127; numeric DBC decoders may still scale it: check raw before use. Upstream default raw=0 (not necessarily valid data).";
CM_ SG_ 794 ZevRangeDisplay "DATABASE_CANDIDATE: physical interpretation unverified; capture/layout evidence reported separately. PSA-RE bits 1.7-2.7. Zero-emission (ZEV) driving range to display (km) VEHICLE_SCALE_OBSERVED: Owner supplied MyOpel screenshot showing 57% SOC and 120 km for logs/info_soc57_refresh.csv. All45 SOC frames contain byte0=0x39 (57). 44 valid31A frames start 1E00, raw9-bit range60; one startup frame is FF80, unavailable511. Thus this operating point requires 2 km/count, not the pinned source factor1. See docs/range-calibration.md. Scope: Vehicle-specific linear scale correction anchored by one simultaneous app/capture reference. Other operating points, rounding, upper bounds and upstream alternative vehicles remain unvalidated; source JSON stays unchanged. Raw invalid=511; numeric DBC decoders may still scale it: check raw before use. Upstream default raw=511 (not necessarily valid data). Unresolved source alternatives: [{\"note\": \"Also observed with another scaling (factor 0.1)\", \"factor\": 0.1}]";
CM_ BO_ 795 "DATABASE_CANDIDATE: physical interpretation unverified; capture/layout evidence reported separately. INFO-DIV CAN, 125000 bit/s; CAN ID 0x31B. PSA-RE title: CLIMATE_PRECOND_PROGRAM_SCREEN_REMOTE. Climate preconditioning weekly programming screen requests from the remote app (part 1). Source: https://github.com/prototux/PSA-RE/blob/67f7581e7622410efdbb29c7eda3b86982b9b450/buses/AEE2010.full/LS.INFO-DIV/31B.yml. Source sender alternatives: MDS; physical TX/gateway forwarding not verified. ";
CM_ SG_ 795 ClimatePrecondRemoteSlot2_b77ae3 "DATABASE_CANDIDATE: physical interpretation unverified; capture/layout evidence reported separately. PSA-RE bits 6.2-7.0. Start time of remote thermal preconditioning schedule 2";
CM_ SG_ 795 RawBits40_44 "RAW. PSA-RE bits 6.7-6.3. Unmapped/padding bits, no physical interpretation.";
CM_ SG_ 795 ClimatePrecondRemoteSunda_0b3fd3 "DATABASE_CANDIDATE: physical interpretation unverified; capture/layout evidence reported separately. PSA-RE bits 5.0. Remote thermal preconditioning schedule 2 enabled (Sunday)";
CM_ SG_ 795 ClimatePrecondRemoteSatur_e982cd "DATABASE_CANDIDATE: physical interpretation unverified; capture/layout evidence reported separately. PSA-RE bits 5.1. Remote thermal preconditioning schedule 2 enabled (Saturday)";
CM_ SG_ 795 ClimatePrecondRemoteFrida_9070b7 "DATABASE_CANDIDATE: physical interpretation unverified; capture/layout evidence reported separately. PSA-RE bits 5.2. Remote thermal preconditioning schedule 2 enabled (Friday)";
CM_ SG_ 795 ClimatePrecondRemoteThurs_e1ef2a "DATABASE_CANDIDATE: physical interpretation unverified; capture/layout evidence reported separately. PSA-RE bits 5.3. Remote thermal preconditioning schedule 2 enabled (Thursday)";
CM_ SG_ 795 ClimatePrecondRemoteWedne_cfe436 "DATABASE_CANDIDATE: physical interpretation unverified; capture/layout evidence reported separately. PSA-RE bits 5.4. Remote thermal preconditioning schedule 2 enabled (Wednesday)";
CM_ SG_ 795 ClimatePrecondRemoteTuesd_c35246 "DATABASE_CANDIDATE: physical interpretation unverified; capture/layout evidence reported separately. PSA-RE bits 5.5. Remote thermal preconditioning schedule 2 enabled (Tuesday)";
CM_ SG_ 795 ClimatePrecondRemoteMonda_c770a4 "DATABASE_CANDIDATE: physical interpretation unverified; capture/layout evidence reported separately. PSA-RE bits 5.6. Remote thermal preconditioning schedule 2 enabled (Monday)";
CM_ SG_ 795 ClimatePrecondRemoteSlot2Enabled "DATABASE_CANDIDATE: physical interpretation unverified; capture/layout evidence reported separately. PSA-RE bits 5.7. Remote thermal preconditioning schedule 2 enabled";
CM_ SG_ 795 ClimatePrecondRemoteSlot1_b80884 "DATABASE_CANDIDATE: physical interpretation unverified; capture/layout evidence reported separately. PSA-RE bits 3.2-4.0. Start time of remote thermal preconditioning schedule 1";
CM_ SG_ 795 RawBits16_20 "RAW. PSA-RE bits 3.7-3.3. Unmapped/padding bits, no physical interpretation.";
CM_ SG_ 795 ClimatePrecondRemoteSunda_2d4a77 "DATABASE_CANDIDATE: physical interpretation unverified; capture/layout evidence reported separately. PSA-RE bits 2.0. Remote thermal preconditioning schedule 1 enabled (Sunday)";
CM_ SG_ 795 ClimatePrecondRemoteSatur_221a26 "DATABASE_CANDIDATE: physical interpretation unverified; capture/layout evidence reported separately. PSA-RE bits 2.1. Remote thermal preconditioning schedule 1 enabled (Saturday)";
CM_ SG_ 795 ClimatePrecondRemoteFrida_6939df "DATABASE_CANDIDATE: physical interpretation unverified; capture/layout evidence reported separately. PSA-RE bits 2.2. Remote thermal preconditioning schedule 1 enabled (Friday)";
CM_ SG_ 795 ClimatePrecondRemoteThurs_93f86e "DATABASE_CANDIDATE: physical interpretation unverified; capture/layout evidence reported separately. PSA-RE bits 2.3. Remote thermal preconditioning schedule 1 enabled (Thursday)";
CM_ SG_ 795 ClimatePrecondRemoteWedne_95c1ef "DATABASE_CANDIDATE: physical interpretation unverified; capture/layout evidence reported separately. PSA-RE bits 2.4. Remote thermal preconditioning schedule 1 enabled (Wednesday)";
CM_ SG_ 795 ClimatePrecondRemoteTuesd_8ad48a "DATABASE_CANDIDATE: physical interpretation unverified; capture/layout evidence reported separately. PSA-RE bits 2.5. Remote thermal preconditioning schedule 1 enabled (Tuesday)";
CM_ SG_ 795 ClimatePrecondRemoteMonda_95abbb "DATABASE_CANDIDATE: physical interpretation unverified; capture/layout evidence reported separately. PSA-RE bits 2.6. Remote thermal preconditioning schedule 1 enabled (Monday)";
CM_ SG_ 795 ClimatePrecondRemoteSlot1Enabled "DATABASE_CANDIDATE: physical interpretation unverified; capture/layout evidence reported separately. PSA-RE bits 2.7. Remote thermal preconditioning schedule 1 enabled";
CM_ SG_ 795 RawBits2_7 "RAW. PSA-RE bits 1.5-1.0. Unmapped/padding bits, no physical interpretation.";
CM_ SG_ 795 ClimatePrecondAsapRequest "DATABASE_CANDIDATE: physical interpretation unverified; capture/layout evidence reported separately. PSA-RE bits 1.6. Request to activate the immediate (ASAP) thermal preconditioning function";
CM_ SG_ 795 ClimatePrecondRemoteMenuA_2dcd7c "DATABASE_CANDIDATE: physical interpretation unverified; capture/layout evidence reported separately. PSA-RE bits 1.7. Information about the overall availability of the remote thermal preconditioning schedule menu";
CM_ BO_ 796 "DATABASE_CANDIDATE: physical interpretation unverified; capture/layout evidence reported separately. INFO-DIV CAN, 125000 bit/s; CAN ID 0x31C. PSA-RE title: TRIP_COMPUTER_STATUS. Trip computer status: vehicle info display, self-check request/stop, trip 1/2 and partial odometer reset requests, message acknowledgement. Source: https://github.com/prototux/PSA-RE/blob/67f7581e7622410efdbb29c7eda3b86982b9b450/buses/AEE2010.full/LS.INFO-DIV/31C.yml. Source sender alternatives: CMB,MATT; physical TX/gateway forwarding not verified. VEHICLE_SOURCE_REVIEW: Owner reports original instrument cluster unit004 connected for info_buzeni_obc.csv and absent in earlier captures. This ID is absent in info_standby.csv and fully operational info_start_jizda.csv; upstream lists CMB among possible senders. Owner approved limiting IC attribution to these nine messages. Scope: Vehicle-specific sender attribution from installation report/capture comparison and compatible source alias; does not validate signal meanings or exclude gateway forwarding. Observed 2049 frames in info_buzeni_obc.csv,info_charging.csv; DLCs [5]. ";
CM_ SG_ 796 CruiseProgrammedSpeedSetpoint "DATABASE_CANDIDATE: physical interpretation unverified; capture/layout evidence reported separately. PSA-RE bits 5.7-5.0. Programmed cruise control/speed limiter (XVV) speed setpoint Raw invalid=255; numeric DBC decoders may still scale it: check raw before use. Upstream default raw=255 (not necessarily valid data).";
CM_ SG_ 796 Unused1 "DATABASE_CANDIDATE: physical interpretation unverified; capture/layout evidence reported separately. PSA-RE bits 4.1-4.0. ";
CM_ SG_ 796 CruiseSetpointMemoRequest "DATABASE_CANDIDATE: physical interpretation unverified; capture/layout evidence reported separately. PSA-RE bits 4.2. Request related to the cruise control/speed limiter (XVV) speed setpoint memory Upstream default raw=0 (not necessarily valid data).";
CM_ SG_ 796 CruiseProgrammedSpeedRequest "DATABASE_CANDIDATE: physical interpretation unverified; capture/layout evidence reported separately. PSA-RE bits 4.3. Request to activate the programmed cruise control/speed limiter (XVV) speed Upstream default raw=0 (not necessarily valid data).";
CM_ SG_ 796 CruiseProgrammedSpeedPosition "DATABASE_CANDIDATE: physical interpretation unverified; capture/layout evidence reported separately. PSA-RE bits 4.6-4.4. Position (slot) of the programmed cruise control/speed limiter speed setpoint Upstream default raw=0 (not necessarily valid data).";
CM_ SG_ 796 MediaDisplayFaultArc "DATABASE_CANDIDATE: physical interpretation unverified; capture/layout evidence reported separately. PSA-RE bits 4.7. Media display fault reported by the ARC function Upstream default raw=0 (not necessarily valid data).";
CM_ SG_ 796 ThermalPrecondProgramInco_047427 "DATABASE_CANDIDATE: physical interpretation unverified; capture/layout evidence reported separately. PSA-RE bits 3.0. Inconsistency in the thermal preconditioning program Upstream default raw=0 (not necessarily valid data).";
CM_ SG_ 796 MessageAckPointer "DATABASE_CANDIDATE: physical interpretation unverified; capture/layout evidence reported separately. PSA-RE bits 2.7-3.1. Pointer to the message to be acknowledged Upstream default raw=0 (not necessarily valid data).";
CM_ SG_ 796 MediaDisplayFault "DATABASE_CANDIDATE: physical interpretation unverified; capture/layout evidence reported separately. PSA-RE bits 1.0. Media display fault Upstream default raw=0 (not necessarily valid data).";
CM_ SG_ 796 StartPhaseRequest "DATABASE_CANDIDATE: physical interpretation unverified; capture/layout evidence reported separately. PSA-RE bits 1.1. Request for the starting phase Upstream default raw=1 (not necessarily valid data).";
CM_ SG_ 796 Trip2ResetRequestMatt "DATABASE_CANDIDATE: physical interpretation unverified; capture/layout evidence reported separately. PSA-RE bits 1.2. Reset request for trip 2 totals on the dot-matrix display Upstream default raw=0 (not necessarily valid data).";
CM_ SG_ 796 Trip1ResetRequestMatt "DATABASE_CANDIDATE: physical interpretation unverified; capture/layout evidence reported separately. PSA-RE bits 1.3. Reset request for trip 1 totals on the dot-matrix display Upstream default raw=0 (not necessarily valid data).";
CM_ SG_ 796 MattMaintenanceResetRequest "DATABASE_CANDIDATE: physical interpretation unverified; capture/layout evidence reported separately. PSA-RE bits 1.4. Maintenance reset requested on the dot-matrix display Upstream default raw=0 (not necessarily valid data).";
CM_ SG_ 796 TripOdometerResetRequestMatt "DATABASE_CANDIDATE: physical interpretation unverified; capture/layout evidence reported separately. PSA-RE bits 1.5. Reset of the partial trip odometer requested on the dot-matrix display Upstream default raw=0 (not necessarily valid data).";
CM_ SG_ 796 MattCheckStopRequest "DATABASE_CANDIDATE: physical interpretation unverified; capture/layout evidence reported separately. PSA-RE bits 1.6. Order to interrupt the dot-matrix display check Upstream default raw=0 (not necessarily valid data).";
CM_ SG_ 796 MattAlertCheckRequest "DATABASE_CANDIDATE: physical interpretation unverified; capture/layout evidence reported separately. PSA-RE bits 1.7. Check of alerts requested by the dot-matrix display Upstream default raw=0 (not necessarily valid data).";
CM_ BO_ 799 "DATABASE_CANDIDATE: physical interpretation unverified; capture/layout evidence reported separately. INFO-DIV CAN, 125000 bit/s; CAN ID 0x31F. PSA-RE title: DISPLAY_LVDS_CONTROL. Instrument cluster LVDS video link control: object acknowledgement and retransmission requests. Source: https://github.com/prototux/PSA-RE/blob/67f7581e7622410efdbb29c7eda3b86982b9b450/buses/AEE2010.full/LS.INFO-DIV/31F.yml. Source sender alternatives: CMB; physical TX/gateway forwarding not verified. ";
CM_ SG_ 799 LvdsRetransmitRequest "DATABASE_CANDIDATE: physical interpretation unverified; capture/layout evidence reported separately. PSA-RE bits 3.7-3.0. Retransmit request for an LVDS object of the given type";
CM_ SG_ 799 LvdsFrameAck "DATABASE_CANDIDATE: physical interpretation unverified; capture/layout evidence reported separately. PSA-RE bits 2.7-2.0. Acknowledgement of the frame, mentioning its session counter";
CM_ SG_ 799 Unused1 "DATABASE_CANDIDATE: physical interpretation unverified; capture/layout evidence reported separately. PSA-RE bits 1.4-1.0. ";
CM_ SG_ 799 LvdsRequestType "DATABASE_CANDIDATE: physical interpretation unverified; capture/layout evidence reported separately. PSA-RE bits 1.7-1.5. Request type sent by the receiver to the sender Upstream default raw=0 (not necessarily valid data).";
CM_ BO_ 800 "DATABASE_CANDIDATE: physical interpretation unverified; capture/layout evidence reported separately. INFO-DIV CAN, 125000 bit/s; CAN ID 0x320. PSA-RE title: HYBRID_CONSUMPTION_GAIN. Fuel consumption savings achieved by the hybrid system over the last six periods. Source: https://github.com/prototux/PSA-RE/blob/67f7581e7622410efdbb29c7eda3b86982b9b450/buses/AEE2010.full/LS.INFO-DIV/320.yml. Source sender alternatives: BSI; physical TX/gateway forwarding not verified. Observed 587 frames in info_apka.csv,info_buzeni_obc.csv,info_charging.csv,info_standby.csv,info_start_jizda.csv,infocan.csv; DLCs [6]. Unresolved alternative source layouts preserved in source JSON. ";
CM_ SG_ 800 Unused6 "DATABASE_CANDIDATE: physical interpretation unverified; capture/layout evidence reported separately. PSA-RE bits 6.2-6.0. ";
CM_ SG_ 800 ConsumptionHistoryMedals6 "DATABASE_CANDIDATE: physical interpretation unverified; capture/layout evidence reported separately. PSA-RE bits 6.7-6.3. Number of medals shown on consumption history bar 6 Upstream default raw=0 (not necessarily valid data).";
CM_ SG_ 800 Unused5 "DATABASE_CANDIDATE: physical interpretation unverified; capture/layout evidence reported separately. PSA-RE bits 5.2-5.0. ";
CM_ SG_ 800 ConsumptionHistoryMedals5 "DATABASE_CANDIDATE: physical interpretation unverified; capture/layout evidence reported separately. PSA-RE bits 5.7-5.3. Number of medals shown on consumption history bar 5 Upstream default raw=0 (not necessarily valid data).";
CM_ SG_ 800 Unused4 "DATABASE_CANDIDATE: physical interpretation unverified; capture/layout evidence reported separately. PSA-RE bits 4.2-4.0. ";
CM_ SG_ 800 ConsumptionHistoryMedals4 "DATABASE_CANDIDATE: physical interpretation unverified; capture/layout evidence reported separately. PSA-RE bits 4.7-4.3. Number of medals shown on consumption history bar 4 Upstream default raw=0 (not necessarily valid data).";
CM_ SG_ 800 Unused3 "DATABASE_CANDIDATE: physical interpretation unverified; capture/layout evidence reported separately. PSA-RE bits 3.2-3.0. ";
CM_ SG_ 800 ConsumptionHistoryMedals3 "DATABASE_CANDIDATE: physical interpretation unverified; capture/layout evidence reported separately. PSA-RE bits 3.7-3.3. Number of medals shown on consumption history bar 3 Upstream default raw=0 (not necessarily valid data).";
CM_ SG_ 800 Unused2 "DATABASE_CANDIDATE: physical interpretation unverified; capture/layout evidence reported separately. PSA-RE bits 2.2-2.0. ";
CM_ SG_ 800 ConsumptionHistoryMedals2 "DATABASE_CANDIDATE: physical interpretation unverified; capture/layout evidence reported separately. PSA-RE bits 2.7-2.3. Number of medals shown on consumption history bar 2 Upstream default raw=0 (not necessarily valid data).";
CM_ SG_ 800 Unused1 "DATABASE_CANDIDATE: physical interpretation unverified; capture/layout evidence reported separately. PSA-RE bits 1.2-1.0. ";
CM_ SG_ 800 ConsumptionHistoryMedals1 "DATABASE_CANDIDATE: physical interpretation unverified; capture/layout evidence reported separately. PSA-RE bits 1.7-1.3. Number of medals shown on consumption history bar 1 Upstream default raw=0 (not necessarily valid data).";
CM_ BO_ 801 "DATABASE_CANDIDATE: physical interpretation unverified; capture/layout evidence reported separately. INFO-DIV CAN, 125000 bit/s; CAN ID 0x321. PSA-RE title: COMBINE_ALERTS_INDICATORS_2. Additional instrument cluster telltale/alert commands: ABS state indicator, driver distraction and drowsiness detection, eco-coaching and animal/pedestrian collision warning. Source: https://github.com/prototux/PSA-RE/blob/67f7581e7622410efdbb29c7eda3b86982b9b450/buses/AEE2010.full/LS.INFO-DIV/321.yml. Source sender alternatives: BSI; physical TX/gateway forwarding not verified. Observed 2936 frames in info_apka.csv,info_buzeni_obc.csv,info_charging.csv,info_standby.csv,info_start_jizda.csv,infocan.csv; DLCs [6]. ";
CM_ SG_ 801 Unused2 "DATABASE_CANDIDATE: physical interpretation unverified; capture/layout evidence reported separately. PSA-RE bits 6.4-6.0. ";
CM_ SG_ 801 ElectricMotorFaultG4Indicator "DATABASE_CANDIDATE: physical interpretation unverified; capture/layout evidence reported separately. PSA-RE bits 6.5. Electric motor fault indicator, generation 4 powertrain Upstream default raw=0 (not necessarily valid data).";
CM_ SG_ 801 ElectricMotorFaultG3Indicator "DATABASE_CANDIDATE: physical interpretation unverified; capture/layout evidence reported separately. PSA-RE bits 6.6. Electric motor fault indicator, generation 3 powertrain Upstream default raw=0 (not necessarily valid data).";
CM_ SG_ 801 TurtleModeIndicator "DATABASE_CANDIDATE: physical interpretation unverified; capture/layout evidence reported separately. PSA-RE bits 6.7. Turtle mode (reduced power) indicator request Upstream default raw=0 (not necessarily valid data).";
CM_ SG_ 801 LowBatteryLevelIndicator "DATABASE_CANDIDATE: physical interpretation unverified; capture/layout evidence reported separately. PSA-RE bits 5.0. Low battery level indicator request Upstream default raw=0 (not necessarily valid data).";
CM_ SG_ 801 AvasIndicatorRequest "DATABASE_CANDIDATE: physical interpretation unverified; capture/layout evidence reported separately. PSA-RE bits 5.1. AVAS (acoustic vehicle alerting system) indicator light request Upstream default raw=0 (not necessarily valid data).";
CM_ SG_ 801 GearboxUnlockIndicator "DATABASE_CANDIDATE: physical interpretation unverified; capture/layout evidence reported separately. PSA-RE bits 5.3-5.2. Gearbox UNLOCK indicator lighting Upstream default raw=0 (not necessarily valid data).";
CM_ SG_ 801 AbsdStateIndicator "DATABASE_CANDIDATE: physical interpretation unverified; capture/layout evidence reported separately. PSA-RE bits 5.5-5.4. ABSD function state indicator Upstream default raw=0 (not necessarily valid data).";
CM_ SG_ 801 NightVisionAnimalAlert "DATABASE_CANDIDATE: physical interpretation unverified; capture/layout evidence reported separately. PSA-RE bits 5.6. Night vision animal presence alert Upstream default raw=0 (not necessarily valid data).";
CM_ SG_ 801 NightVisionPedestrianAlert "DATABASE_CANDIDATE: physical interpretation unverified; capture/layout evidence reported separately. PSA-RE bits 5.7. Night vision pedestrian presence alert Upstream default raw=0 (not necessarily valid data).";
CM_ SG_ 801 Unused1 "DATABASE_CANDIDATE: physical interpretation unverified; capture/layout evidence reported separately. PSA-RE bits 4.0. ";
CM_ SG_ 801 NightVisionState "DATABASE_CANDIDATE: physical interpretation unverified; capture/layout evidence reported separately. PSA-RE bits 4.2-4.1. Night vision camera activation state Upstream default raw=0 (not necessarily valid data).";
CM_ SG_ 801 NightVisionDefectSoundRenew "DATABASE_CANDIDATE: physical interpretation unverified; capture/layout evidence reported separately. PSA-RE bits 4.3. Night vision fault sound alert, renewed request Upstream default raw=0 (not necessarily valid data).";
CM_ SG_ 801 NightVisionDefectSound "DATABASE_CANDIDATE: physical interpretation unverified; capture/layout evidence reported separately. PSA-RE bits 4.4. Night vision fault sound alert request Upstream default raw=0 (not necessarily valid data).";
CM_ SG_ 801 NightVisionBeamActivation_6a287d "DATABASE_CANDIDATE: physical interpretation unverified; capture/layout evidence reported separately. PSA-RE bits 4.5. Night vision request to turn on headlight beam message, renewed Upstream default raw=0 (not necessarily valid data).";
CM_ SG_ 801 NightVisionBeamActivationMessage "DATABASE_CANDIDATE: physical interpretation unverified; capture/layout evidence reported separately. PSA-RE bits 4.6. Night vision request to turn on headlight beam message Upstream default raw=0 (not necessarily valid data).";
CM_ SG_ 801 NightVisionAnimalSoundAlert "DATABASE_CANDIDATE: physical interpretation unverified; capture/layout evidence reported separately. PSA-RE bits 4.7. Night vision animal detection sound alert Upstream default raw=0 (not necessarily valid data).";
CM_ SG_ 801 NightVisionPedestrianSoundAlert "DATABASE_CANDIDATE: physical interpretation unverified; capture/layout evidence reported separately. PSA-RE bits 3.0. Night vision pedestrian detection sound alert Upstream default raw=0 (not necessarily valid data).";
CM_ SG_ 801 NightVisionDefectMessageRenew "DATABASE_CANDIDATE: physical interpretation unverified; capture/layout evidence reported separately. PSA-RE bits 3.1. Night vision fault message renewed request Upstream default raw=0 (not necessarily valid data).";
CM_ SG_ 801 NightVisionActivatedMessage "DATABASE_CANDIDATE: physical interpretation unverified; capture/layout evidence reported separately. PSA-RE bits 3.2. Night vision function activated message request Upstream default raw=0 (not necessarily valid data).";
CM_ SG_ 801 NightVisionDefectMessage "DATABASE_CANDIDATE: physical interpretation unverified; capture/layout evidence reported separately. PSA-RE bits 3.3. Night vision fault message request Upstream default raw=0 (not necessarily valid data).";
CM_ SG_ 801 NightVisionSelectionState "DATABASE_CANDIDATE: physical interpretation unverified; capture/layout evidence reported separately. PSA-RE bits 3.5-3.4. Night vision function selection state Upstream default raw=0 (not necessarily valid data).";
CM_ SG_ 801 NightVisionDetectionState "DATABASE_CANDIDATE: physical interpretation unverified; capture/layout evidence reported separately. PSA-RE bits 3.6. Night vision pedestrian detection status Upstream default raw=0 (not necessarily valid data).";
CM_ SG_ 801 DriverDrowsinessState "DATABASE_CANDIDATE: physical interpretation unverified; capture/layout evidence reported separately. PSA-RE bits 3.7. Driver drowsiness detection function state Upstream default raw=0 (not necessarily valid data).";
CM_ SG_ 801 DriverDistractionState "DATABASE_CANDIDATE: physical interpretation unverified; capture/layout evidence reported separately. PSA-RE bits 2.0. Driver distraction detection function state Upstream default raw=0 (not necessarily valid data).";
CM_ SG_ 801 OverloadIndicatorRequest "DATABASE_CANDIDATE: physical interpretation unverified; capture/layout evidence reported separately. PSA-RE bits 2.1. Vehicle overload telltale light request Upstream default raw=0 (not necessarily valid data).";
CM_ SG_ 801 DriverDrowsinessLevel "DATABASE_CANDIDATE: physical interpretation unverified; capture/layout evidence reported separately. PSA-RE bits 2.4-2.2. Driver drowsiness level Upstream default raw=4 (not necessarily valid data).";
CM_ SG_ 801 DriverDistractionLevel "DATABASE_CANDIDATE: physical interpretation unverified; capture/layout evidence reported separately. PSA-RE bits 2.7-2.5. Driver distraction level Upstream default raw=4 (not necessarily valid data).";
CM_ SG_ 801 GearShiftAdviceReinforcement "DATABASE_CANDIDATE: physical interpretation unverified; capture/layout evidence reported separately. PSA-RE bits 1.1-1.0. Gear shift indicator (GSI) advice reinforcement message Upstream default raw=0 (not necessarily valid data).";
CM_ SG_ 801 CoastingState "DATABASE_CANDIDATE: physical interpretation unverified; capture/layout evidence reported separately. PSA-RE bits 1.3-1.2. Coasting (freewheeling) state shown to the driver Upstream default raw=0 (not necessarily valid data).";
CM_ SG_ 801 EcoDrivingAdvice "DATABASE_CANDIDATE: physical interpretation unverified; capture/layout evidence reported separately. PSA-RE bits 1.7-1.4. Real-time eco-driving advice Raw invalid=15; numeric DBC decoders may still scale it: check raw before use. Upstream default raw=14 (not necessarily valid data).";
CM_ BO_ 805 "DATABASE_CANDIDATE: physical interpretation unverified; capture/layout evidence reported separately. INFO-DIV CAN, 125000 bit/s; CAN ID 0x325. PSA-RE title: RADIO_MEDIA_STATUS. Radio media status: Bluetooth/CD/USB access, unreadable disk, and communication/file/USB/Bluetooth error flags. Source: https://github.com/prototux/PSA-RE/blob/67f7581e7622410efdbb29c7eda3b86982b9b450/buses/AEE2010.full/LS.INFO-DIV/325.yml. Source sender alternatives: RAD,ICSV; physical TX/gateway forwarding not verified. ";
CM_ SG_ 805 Unused1 "DATABASE_CANDIDATE: physical interpretation unverified; capture/layout evidence reported separately. PSA-RE bits 4.6-4.0. ";
CM_ SG_ 805 UsbPlayerOverload "DATABASE_CANDIDATE: physical interpretation unverified; capture/layout evidence reported separately. PSA-RE bits 4.7. USB player overload Upstream default raw=0 (not necessarily valid data).";
CM_ SG_ 805 AudioStreamingErrorType "DATABASE_CANDIDATE: physical interpretation unverified; capture/layout evidence reported separately. PSA-RE bits 3.1-3.0. Audio streaming error type Upstream default raw=0 (not necessarily valid data).";
CM_ SG_ 805 AudioFileDetected "DATABASE_CANDIDATE: physical interpretation unverified; capture/layout evidence reported separately. PSA-RE bits 3.2. Audio file detection Upstream default raw=0 (not necessarily valid data).";
CM_ SG_ 805 UsbCommunicationError "DATABASE_CANDIDATE: physical interpretation unverified; capture/layout evidence reported separately. PSA-RE bits 3.3. Communication status with the USB device Upstream default raw=0 (not necessarily valid data).";
CM_ SG_ 805 UsbDeviceIdentification "DATABASE_CANDIDATE: physical interpretation unverified; capture/layout evidence reported separately. PSA-RE bits 3.4. Identification of the USB peripheral device Upstream default raw=0 (not necessarily valid data).";
CM_ SG_ 805 UsbSourceInfo "DATABASE_CANDIDATE: physical interpretation unverified; capture/layout evidence reported separately. PSA-RE bits 3.5. Information on the USB Source Upstream default raw=0 (not necessarily valid data).";
CM_ SG_ 805 BluetoothAccessInProgress "DATABASE_CANDIDATE: physical interpretation unverified; capture/layout evidence reported separately. PSA-RE bits 3.6. Access in progress on a bluetooth peripheral device Upstream default raw=0 (not necessarily valid data).";
CM_ SG_ 805 UsbAccessInProgress "DATABASE_CANDIDATE: physical interpretation unverified; capture/layout evidence reported separately. PSA-RE bits 3.7. Access in progress on a USB peripheral device Upstream default raw=1 (not necessarily valid data).";
CM_ SG_ 805 BluetoothPlayerStatus "DATABASE_CANDIDATE: physical interpretation unverified; capture/layout evidence reported separately. PSA-RE bits 2.2-2.0. Status of Bluetooth player Upstream default raw=0 (not necessarily valid data).";
CM_ SG_ 805 UsbPlayerStatus "DATABASE_CANDIDATE: physical interpretation unverified; capture/layout evidence reported separately. PSA-RE bits 2.5-2.3. Status of USB player Upstream default raw=0 (not necessarily valid data).";
CM_ SG_ 805 AccessCd "DATABASE_CANDIDATE: physical interpretation unverified; capture/layout evidence reported separately. PSA-RE bits 2.7-2.6. CD access in progress (car radio) Upstream default raw=0 (not necessarily valid data).";
CM_ SG_ 805 CdPlayerStatus "DATABASE_CANDIDATE: physical interpretation unverified; capture/layout evidence reported separately. PSA-RE bits 1.2-1.0. Status of car radio CD Upstream default raw=0 (not necessarily valid data).";
CM_ SG_ 805 DiscType "DATABASE_CANDIDATE: physical interpretation unverified; capture/layout evidence reported separately. PSA-RE bits 1.3. Type of disk Upstream default raw=0 (not necessarily valid data).";
CM_ SG_ 805 CdOverheating "DATABASE_CANDIDATE: physical interpretation unverified; capture/layout evidence reported separately. PSA-RE bits 1.4. Temperature overflow of the car radio CD player Upstream default raw=0 (not necessarily valid data).";
CM_ SG_ 805 DiskDirection "DATABASE_CANDIDATE: physical interpretation unverified; capture/layout evidence reported separately. PSA-RE bits 1.5. Disc upside down Upstream default raw=0 (not necessarily valid data).";
CM_ SG_ 805 CdPlayerError "DATABASE_CANDIDATE: physical interpretation unverified; capture/layout evidence reported separately. PSA-RE bits 1.6. CD status of the car radio Upstream default raw=0 (not necessarily valid data).";
CM_ SG_ 805 DiscError "DATABASE_CANDIDATE: physical interpretation unverified; capture/layout evidence reported separately. PSA-RE bits 1.7. Disc unreadable Upstream default raw=0 (not necessarily valid data).";
CM_ BO_ 807 "DATABASE_CANDIDATE: physical interpretation unverified; capture/layout evidence reported separately. INFO-DIV CAN, 125000 bit/s; CAN ID 0x327. PSA-RE title: RADIO_TEXT_STATUS_ACK. Acknowledgement of a multi-frame radio text status message. Source: https://github.com/prototux/PSA-RE/blob/67f7581e7622410efdbb29c7eda3b86982b9b450/buses/AEE2010.full/LS.INFO-DIV/327.yml. Source sender alternatives: EMF,ICSV; physical TX/gateway forwarding not verified. ";
CM_ SG_ 807 SegmentationAckStream "DATABASE_CANDIDATE: physical interpretation unverified; capture/layout evidence reported separately. PSA-RE bits 1.7-1.0. Segmentation acknowledgment stream";
VAL_ 705 FlowStatus 0 "ContinueToSend" 1 "Wait" 2 "Overflow" ;
VAL_ 705 IsoTpFrameType 0 "SingleFrame" 1 "FirstFrame" 2 "ConsecutiveFrame" 3 "FlowControl" ;
VAL_ 709 FlowStatus 0 "ContinueToSend" 1 "Wait" 2 "Overflow" ;
VAL_ 709 IsoTpFrameType 0 "SingleFrame" 1 "FirstFrame" 2 "ConsecutiveFrame" 3 "FlowControl" ;
VAL_ 721 SpaceMeasurementSide 0 "Left" 1 "Right (maximum)" ;
VAL_ 721 SpaceMeasurementDisplayRequest 0 "No display request" 1 "Display request" ;
VAL_ 721 MeasuredDistance 0 "Insufficient space" 1 "Small space" 2 "Medium space" 3 "Large space" ;
VAL_ 721 SpaceMeasurementStatus 1 "Failure detected" 2 "Status off" 3 "Trailer inhibit" 4 "Active" 5 "Waiting" 6 "Out of service" ;
VAL_ 721 SamActivityStatus 0 "Inactive" 1 "Active" 4 "Inhibited" 6 "Invalid" 7 "Failure detected" ;
VAL_ 721 SamLedRequest 0 "Off" 1 "On" 2 "Flashing" 3 "Invalid" ;
VAL_ 721 SamRightObjectPresent 0 "Absent" 1 "Present" ;
VAL_ 721 SamLeftObjectPresent 0 "Absent" 1 "Present" ;
VAL_ 724 FlowStatus 0 "ContinueToSend" 1 "Wait" 2 "Overflow" ;
VAL_ 724 IsoTpFrameType 0 "SingleFrame" 1 "FirstFrame" 2 "ConsecutiveFrame" 3 "FlowControl" ;
VAL_ 727 EcoachFieldAvailable 0 "Absent" 1 "Present" ;
VAL_ 727 DaaFieldAvailable 0 "Absent" 1 "Present" ;
VAL_ 727 TripComputerFieldAvailable 0 "Absent" 1 "Present" ;
VAL_ 727 LightNavExportFieldAvailable 0 "Absent" 1 "Present" ;
VAL_ 727 FullNavExportFieldAvailable 0 "Absent" 1 "Present" ;
VAL_ 727 LightMediaExportFieldAvailable 0 "Absent" 1 "Present" ;
VAL_ 727 FullMediaExportFieldAvailable 0 "Absent" 1 "Present" ;
VAL_ 727 PowermeterFieldAvailable 0 "Absent" 1 "Present" ;
VAL_ 727 HybridFlowFieldAvailable 0 "Absent" 1 "Present" ;
VAL_ 727 TempGaugesFieldAvailable 0 "Absent" 1 "Present" ;
VAL_ 727 GMeterFieldAvailable 0 "Absent" 1 "Present" ;
VAL_ 727 PowerGaugeFieldAvailable 0 "Absent" 1 "Present" ;
VAL_ 727 StyleDecorFieldAvailable 0 "Absent" 1 "Present" ;
VAL_ 727 AdasFieldAvailable 0 "Absent" 1 "Present" ;
VAL_ 727 TachometerFieldAvailable 0 "Absent" 1 "Present" ;
VAL_ 727 CustomImageFieldAvailable 0 "Absent" 1 "Present" ;
VAL_ 727 LvdsVideoFormat 0 "No video" 1 "Full screen" 2 "Pop-up" 3 "Window" ;
VAL_ 727 TivSettingsPageOpen 0 "Closed" 1 "Open" ;
VAL_ 727 NavDatabaseLoading 0 "Loading in progress" 1 "Loading finished" ;
VAL_ 727 ImageStorageStatus 0 "In progress" 1 "None, OK" 2 "None Nok" 3 "Invalid" ;
VAL_ 731 ChargeTargetLevel 0 "10" 1 "20" 2 "FULL" ;
VAL_ 731 ChargeTypeSelection 0 "Immediate" 1 "Delayed" ;
VAL_ 731 ChargeScheduleMenuAvailability 0 "Unavailable" 1 "Available" ;
VAL_ 732 FlowStatus 0 "ContinueToSend" 1 "Wait" 2 "Overflow" ;
VAL_ 732 IsoTpFrameType 0 "SingleFrame" 1 "FirstFrame" 2 "ConsecutiveFrame" 3 "FlowControl" ;
VAL_ 735 FlowStatus 0 "ContinueToSend" 1 "Wait" 2 "Overflow" ;
VAL_ 735 IsoTpFrameType 0 "SingleFrame" 1 "FirstFrame" 2 "ConsecutiveFrame" 3 "FlowControl" ;
VAL_ 736 AcPrecondSundaySchedule2Active 0 "Function off" 1 "Function active" ;
VAL_ 736 AcPrecondSaturdaySchedule2Active 0 "Function off" 1 "Function active" ;
VAL_ 736 AcPrecondFridaySchedule2Active 0 "Function off" 1 "Function active" ;
VAL_ 736 AcPrecondThursdaySchedule2Active 0 "Function off" 1 "Function active" ;
VAL_ 736 AcPrecondWednesdaySchedul_14303b 0 "Function off" 1 "Function active" ;
VAL_ 736 AcPrecondTuesdaySchedule2Active 0 "Function off" 1 "Function active" ;
VAL_ 736 AcPrecondMondaySchedule2Active 0 "Function off" 1 "Function active" ;
VAL_ 736 AcPrecondSchedule2Enabled 0 "Function off" 1 "Function active" ;
VAL_ 736 AcPrecondSundaySchedule1Active 0 "Function off" 1 "Function active" ;
VAL_ 736 AcPrecondSaturdaySchedule1Active 0 "Function off" 1 "Function active" ;
VAL_ 736 AcPrecondFridaySchedule1Active 0 "Function off" 1 "Function active" ;
VAL_ 736 AcPrecondThursdaySchedule1Active 0 "Function off" 1 "Function active" ;
VAL_ 736 AcPrecondWednesdaySchedul_0079d6 0 "Function off" 1 "Function active" ;
VAL_ 736 AcPrecondTuesdaySchedule1Active 0 "Function off" 1 "Function active" ;
VAL_ 736 AcPrecondMondaySchedule1Active 0 "Function off" 1 "Function active" ;
VAL_ 736 AcPrecondSchedule1Enabled 0 "Function off" 1 "Function active" ;
VAL_ 736 AcPrecondAsapModeActive 0 "Inactive" 1 "Active" ;
VAL_ 736 AcPrecondStatusFeedback 0 "Inactive (capture observed)" 1 "Active (capture observed)" ;
VAL_ 736 AcPrecondStatusAvailability 0 "Unavailable" 1 "Available" ;
VAL_ 737 AsrPAvailability 0 "Unavailable" 1 "Available" ;
VAL_ 737 RetractableRoofState 0 "No display" 1 "Sliding roof closed" 2 "Roof position 3/4" 3 "Roof position 1/2" 4 "Roof position 1/4" 5 "Roof open" ;
VAL_ 737 AsrPlusMode 0 "ASR+ in ESP OFF mode" 1 "ASR+ normal mode" 2 "ASR+ in snow mode" 3 "ASR+ in mud mode" 4 "ASR+ in sand mode" 5 "Reserved value" 6 "ASR+ selector fault" 7 "ESP ASR+ selector fault" ;
VAL_ 737 SuspensionAlert 0 "No alert" 1 "Alert" ;
VAL_ 737 RealSuspensionPosition 0 "Normal" 1 "Mid-height" 2 "Low" 3 "High" 7 "No display" ;
VAL_ 737 SuspensionMovement 0 "No movement" 1 "Rise" 2 "Descent" 3 "Refused" ;
VAL_ 737 FinalSuspensionPosition 0 "Normal" 1 "Mid-height" 2 "Low" 3 "High" 7 "No display" ;
VAL_ 737 InitialSuspensionPosition 0 "Normal" 1 "Mid-height" 2 "Low" 3 "High" 7 "No display" ;
VAL_ 737 PushStartStopStatus 0 "Push released" 1 "Push released" ;
VAL_ 737 TrunkAndConvertibleRoofStatus 0 "Pictogram 1: no display" 1 "Icon 2: vehicle as coupe" 2 "Icon 3: boot open and roof open" 3 "Pictogram 4: trunk open and roof in the trunk" 4 "Pictogram 5: vehicle as convertible" 5 "Icon 6: boot open and roof closed" 6 "Invalid" 7 "Invalid" ;
VAL_ 737 StopStartStatus 0 "Function absent" 1 "Function not activated" 2 "Coding not specified" 3 "Function activated" ;
VAL_ 737 ChildSafetyRearDoorsStatus 0 "Function absent" 1 "Function not activated" 2 "Coding not specified" 3 "Function activated" ;
VAL_ 737 SuspensionMode 0 "Function absent" 1 "Sport" 2 "Normal" 3 "Coding not specified" ;
VAL_ 737 AutomaticWipingStatus 0 "Function absent" 1 "Function not activated" 2 "Coding not specified" 3 "Function activated" ;
VAL_ 737 EspStatus 0 "Function absent" 1 "Function not activated" 2 "Coding not specified" 3 "Function activated" ;
VAL_ 737 DoorLockingStatus 0 "Function absent" 1 "Function not activated" 2 "Coding not specified" 3 "Function activated" ;
VAL_ 737 AutomaticDoorLockingStatus 0 "Function absent" 1 "Function not activated" 2 "Coding not specified" 3 "Function activated" ;
VAL_ 737 AutomaticHeadlightsStatus 0 "Function absent" 1 "Function not activated" 2 "Coding not specified" 3 "Function activated" ;
VAL_ 737 PassengerAirbagStatus 0 "Function absent" 1 "Function not activated" 2 "Coding not specified" 3 "Function activated" ;
VAL_ 737 ParkingAidStatus 0 "Function absent" 1 "Function not activated" 2 "Coding not specified" 3 "Function activated" ;
VAL_ 743 StoredAppearanceId8 0 "Not_available" ;
VAL_ 743 StoredAppearanceId7 0 "Not_available" ;
VAL_ 743 StoredAppearanceId6 0 "Not_available" ;
VAL_ 743 StoredAppearanceId5 0 "Not_available" ;
VAL_ 743 StoredAppearanceId4 0 "Not_available" ;
VAL_ 743 StoredAppearanceId3 0 "Not_available" ;
VAL_ 743 StoredAppearanceId2 0 "Not_available" ;
VAL_ 743 StoredAppearanceId1 0 "Not_available" ;
VAL_ 744 ZevDurationPercentTrip2Adjusted 127 "Not_available" ;
VAL_ 744 ZevDurationPercentTrip2 127 "Not_available" ;
VAL_ 744 ZevDurationSecondsTrip2 63 "Not_available" ;
VAL_ 744 ZevDurationMinutesTrip2 63 "Not_available" ;
VAL_ 744 ZevDurationHoursTrip2 2047 "Not_available" ;
VAL_ 744 TripDurationSecondsTrip2 63 "Not_available" ;
VAL_ 744 TripDurationMinutesTrip2 63 "Not_available" ;
VAL_ 744 TripDurationHoursTrip2 2047 "Not_available" ;
VAL_ 745 HudFoldUnfoldRequest 0 "No command" 1 "Command" ;
VAL_ 745 HudBrightnessAdjustmentRequest 0 "No command" 1 "Increase command" 2 "Decrease command" 3 "Undefined" ;
VAL_ 745 HudHeightAdjustmentRequest 0 "No command" 1 "Rise command" 2 "Lower command" 3 "Undefined" ;
VAL_ 745 DisplayPersonalMode2Choice 0 "None" 1 "ADAS field order" 2 "Black field" 3 "Dynamic field 1" 4 "Dynamic field order 2" 5 "Gauge order field" 6 "Media full field order" 7 "Media field light order" 8 "Full navigation field" 9 "Nav light field order" 10 "OBD-field order" 11 "Engine RPM field order" 12 "Custom image field order" 13 "Hybrid filed order 1" 14 "Hybrid field order 2" 15 "DAA field order" 16 "Eco-coach field order" ;
VAL_ 745 DisplayPersonalModeActive 0 "False" 1 "True" ;
VAL_ 745 DisplayPersonalMode1Choice 0 "None" 1 "ADAS field order" 2 "Black field" 3 "Dynamic field 1" 4 "Dynamic field order 2" 5 "Gauge order field" 6 "Media full field order" 7 "Media field light order" 8 "Full navigation field" 9 "Nav light field order" 10 "OBD-field order" 11 "Engine RPM field order" 12 "Custom image field order" 13 "Hybrid filed order 1" 14 "Hybrid field order 2" 15 "DAA field order" 16 "Eco-coach field order" ;
VAL_ 745 PolysensorialModeActive 0 "Polysensorial mode deactivated" 1 "Mode 1" 2 "Mode 2" 3 "Mode 3" ;
VAL_ 745 CmbAppearance 255 "Not_available" ;
VAL_ 769 SdcmNfcInventoryRequest 0 "No demand" 1 "Demand" ;
VAL_ 769 SdcmNfcConnectRequest 0 "No connection" 1 "BADGE CONNECTION" ;
VAL_ 773 FlowStatus 0 "ContinueToSend" 1 "Wait" 2 "Overflow" ;
VAL_ 773 IsoTpFrameType 0 "SingleFrame" 1 "FirstFrame" 2 "ConsecutiveFrame" 3 "FlowControl" ;
VAL_ 788 FlowStatus 0 "ContinueToSend" 1 "Wait" 2 "Overflow" ;
VAL_ 788 IsoTpFrameType 0 "SingleFrame" 1 "FirstFrame" 2 "ConsecutiveFrame" 3 "FlowControl" ;
VAL_ 791 IndicatorBatteryPresent 0 "Lamp absent" 1 "Lamp present" ;
VAL_ 791 IndicatorSamPresent 0 "Lamp absent" 1 "Lamp present" ;
VAL_ 791 PassiveSafetyPresent 0 "Lamp absent" 1 "Lamp present" ;
VAL_ 791 IndicatorBrakePressedPresent 0 "Lamp absent" 1 "Lamp present" ;
VAL_ 791 IndicatorFse2Present 0 "Lamp absent" 1 "Lamp present" ;
VAL_ 791 IndicatorFsePresent 0 "Lamp absent" 1 "Lamp present" ;
VAL_ 791 StartIndicatorPresence 0 "Absent" 1 "Present" ;
VAL_ 791 IndicatorBrakesPresent 0 "Lamp absent" 1 "Lamp present" ;
VAL_ 791 IndicatorStopAndStartPresent 0 "Lamp absent" 1 "Lamp present" ;
VAL_ 791 IndicatorEspPresent 0 "Lamp absent" 1 "Lamp present" ;
VAL_ 791 IndicatorAbsPresent 0 "Lamp absent" 1 "Lamp present" ;
VAL_ 791 SuspensionFaultPresent 0 "Lamp absent" 1 "Lamp present" ;
VAL_ 791 ElectricParkingBrakeFaultPresent 0 "Lamp absent" 1 "Lamp present" ;
VAL_ 791 IndicatorFapPresent 0 "Lamp absent" 1 "Lamp present" ;
VAL_ 791 IndicatorEnginePresent 0 "Lamp absent" 1 "Lamp present" ;
VAL_ 791 IndicatorWheelsPuncturePresent 0 "Lamp absent" 1 "Lamp present" ;
VAL_ 791 IndicatorWheelsPresurePresent 0 "Lamp absent" 1 "Lamp present" ;
VAL_ 791 IndicatorFseDisabledPresent 0 "Lamp absent" 1 "Lamp present" ;
VAL_ 791 IndicatorHydroLevelPresent 0 "Lamp absent" 1 "Lamp present" ;
VAL_ 791 IndicatorOilPressurePresent 0 "Lamp absent" 1 "Lamp present" ;
VAL_ 791 IndicatorGasoilWaterPresent 0 "Lamp absent" 1 "Lamp present" ;
VAL_ 791 IndicatorCoolantLevelPresent 0 "Lamp absent" 1 "Lamp present" ;
VAL_ 791 IndicatorOilTempPresent 0 "Lamp absent" 1 "Lamp present" ;
VAL_ 791 IndicatorCoolantTempPresent 0 "Lamp absent" 1 "Lamp present" ;
VAL_ 791 IndicatorAlternatorPresent 0 "Lamp absent" 1 "Lamp present" ;
VAL_ 791 IndicatorDsgFaultPresent 0 "Lamp absent" 1 "Lamp present" ;
VAL_ 791 IndicatorDoorsOpenPresent 0 "Lamp absent" 1 "Lamp present" ;
VAL_ 791 IndicatorStopPresent 0 "Lamp absent" 1 "Lamp present" ;
VAL_ 791 IndicatorErrorPresent 0 "Lamp absent" 1 "Lamp present" ;
VAL_ 791 CaarIndicatorPresent 0 "Lamp absent" 1 "Lamp present" ;
VAL_ 791 IndicatorFuelLineBlockedPresent 0 "Lamp absent" 1 "Lamp present" ;
VAL_ 791 IndicatorFuelReservePresent 0 "Lamp absent" 1 "Lamp present" ;
VAL_ 791 IndicatorParkingBrakePresent 0 "Lamp absent" 1 "Lamp present" ;
VAL_ 791 IndicatorDaePresent 0 "Lamp absent" 1 "Lamp present" ;
VAL_ 791 IndicatorPassengerAirbagPresent 0 "Lamp absent" 1 "Lamp present" ;
VAL_ 794 ChargingType 0 "Immediate" 1 "Postponed" ;
VAL_ 794 ZevInstantConsumption 511 "Not_available" ;
VAL_ 794 ZevAverageConsumptionTrip2 511 "Not_available" ;
VAL_ 794 ZevAverageConsumptionTrip1 511 "Not_available" ;
VAL_ 794 ZevPercentage 127 "Not_available" ;
VAL_ 794 ZevRangeDisplay 511 "Not_available" ;
VAL_ 795 ClimatePrecondRemoteSunda_0b3fd3 0 "Function off" 1 "Function active" ;
VAL_ 795 ClimatePrecondRemoteSatur_e982cd 0 "Function off" 1 "Function active" ;
VAL_ 795 ClimatePrecondRemoteFrida_9070b7 0 "Function off" 1 "Function active" ;
VAL_ 795 ClimatePrecondRemoteThurs_e1ef2a 0 "Function off" 1 "Function active" ;
VAL_ 795 ClimatePrecondRemoteWedne_cfe436 0 "Function off" 1 "Function active" ;
VAL_ 795 ClimatePrecondRemoteTuesd_c35246 0 "Function off" 1 "Function active" ;
VAL_ 795 ClimatePrecondRemoteMonda_c770a4 0 "Function off" 1 "Function active" ;
VAL_ 795 ClimatePrecondRemoteSlot2Enabled 0 "Function off" 1 "Function active" ;
VAL_ 795 ClimatePrecondRemoteSunda_2d4a77 0 "Function off" 1 "Function active" ;
VAL_ 795 ClimatePrecondRemoteSatur_221a26 0 "Function off" 1 "Function active" ;
VAL_ 795 ClimatePrecondRemoteFrida_6939df 0 "Function off" 1 "Function active" ;
VAL_ 795 ClimatePrecondRemoteThurs_93f86e 0 "Function off" 1 "Function active" ;
VAL_ 795 ClimatePrecondRemoteWedne_95c1ef 0 "Function off" 1 "Function active" ;
VAL_ 795 ClimatePrecondRemoteTuesd_8ad48a 0 "Function off" 1 "Function active" ;
VAL_ 795 ClimatePrecondRemoteMonda_95abbb 0 "Function off" 1 "Function active" ;
VAL_ 795 ClimatePrecondRemoteSlot1Enabled 0 "Function off" 1 "Function active" ;
VAL_ 795 ClimatePrecondAsapRequest 0 "Inactive" 1 "Active" ;
VAL_ 795 ClimatePrecondRemoteMenuA_2dcd7c 0 "Unavailable" 1 "Available" ;
VAL_ 796 CruiseProgrammedSpeedSetpoint 255 "Not_available" ;
VAL_ 796 CruiseSetpointMemoRequest 0 "No request" 1 "Requested" ;
VAL_ 796 CruiseProgrammedSpeedRequest 0 "No request" 1 "Requested" ;
VAL_ 796 CruiseProgrammedSpeedPosition 0 "None (no longitudinal control)" 1 "Position 1" 2 "Position 2" 3 "Position 3" 4 "Position 4" 5 "Position 5" 6 "Position 6" ;
VAL_ 796 MediaDisplayFaultArc 0 "No fault detected" 1 "Failure detected" ;
VAL_ 796 ThermalPrecondProgramInco_047427 0 "False" 1 "True" ;
VAL_ 796 MessageAckPointer 0 "False" 1 "True" ;
VAL_ 796 MediaDisplayFault 0 "No fault detected" 1 "Failure detected" ;
VAL_ 796 StartPhaseRequest 0 "No request" 1 "Requested" ;
VAL_ 796 Trip2ResetRequestMatt 0 "No request" 1 "Requested" ;
VAL_ 796 Trip1ResetRequestMatt 0 "No request" 1 "Requested" ;
VAL_ 796 MattMaintenanceResetRequest 0 "No request" 1 "Requested" ;
VAL_ 796 TripOdometerResetRequestMatt 0 "No request" 1 "Requested" ;
VAL_ 796 MattCheckStopRequest 0 "No request" 1 "Requested" ;
VAL_ 796 MattAlertCheckRequest 0 "No request" 1 "Requested" ;
VAL_ 799 LvdsRequestType 0 "No action" 1 "Retransmit request" 2 "Acknowledgement" ;
VAL_ 801 ElectricMotorFaultG4Indicator 0 "No request" 1 "Requested" ;
VAL_ 801 ElectricMotorFaultG3Indicator 0 "No request" 1 "Requested" ;
VAL_ 801 TurtleModeIndicator 0 "No request" 1 "Requested" ;
VAL_ 801 LowBatteryLevelIndicator 0 "No request" 1 "Requested" ;
VAL_ 801 AvasIndicatorRequest 0 "Off" 1 "On" ;
VAL_ 801 GearboxUnlockIndicator 0 "Off" 1 "On" 2 "Flashing" 3 "Invalid" ;
VAL_ 801 AbsdStateIndicator 0 "Off" 1 "Lit steady, not ready" 2 "On, blinking" 3 "On steady, ready" ;
VAL_ 801 NightVisionAnimalAlert 0 "No alert" 1 "Alert" ;
VAL_ 801 NightVisionPedestrianAlert 0 "No alert" 1 "Alert" ;
VAL_ 801 NightVisionState 0 "Off" 1 "Activated" 2 "Activated, unavailable" ;
VAL_ 801 NightVisionDefectSoundRenew 0 "No request" 1 "Request" ;
VAL_ 801 NightVisionDefectSound 0 "No request" 1 "Request" ;
VAL_ 801 NightVisionBeamActivation_6a287d 0 "No request" 1 "Request" ;
VAL_ 801 NightVisionBeamActivationMessage 0 "No request" 1 "Request" ;
VAL_ 801 NightVisionAnimalSoundAlert 0 "No request" 1 "Request" ;
VAL_ 801 NightVisionPedestrianSoundAlert 0 "No request" 1 "Request" ;
VAL_ 801 NightVisionDefectMessageRenew 0 "No request" 1 "Request" ;
VAL_ 801 NightVisionActivatedMessage 0 "No request" 1 "Request" ;
VAL_ 801 NightVisionDefectMessage 0 "No request" 1 "Request" ;
VAL_ 801 NightVisionSelectionState 0 "Deselected" 1 "Selected" 2 "Failure detected" ;
VAL_ 801 NightVisionDetectionState 0 "No detection" 1 "Detection" ;
VAL_ 801 DriverDrowsinessState 0 "Not operational" 1 "Operational" ;
VAL_ 801 DriverDistractionState 0 "Not operational" 1 "Operational" ;
VAL_ 801 OverloadIndicatorRequest 0 "Light off" 1 "Light on" ;
VAL_ 801 DriverDrowsinessLevel 0 "Unavailable" 1 "Level 1" 2 "Level 2" 3 "Level 3" 4 "Level 4" ;
VAL_ 801 DriverDistractionLevel 0 "Unavailable" 1 "Level 1" 2 "Level 2" 3 "Level 3" 4 "Level 4" ;
VAL_ 801 GearShiftAdviceReinforcement 0 "No request" 1 "Gear up" 2 "Gear down" 3 "Follow GSI" ;
VAL_ 801 CoastingState 0 "Inactive" 1 "Active" ;
VAL_ 801 EcoDrivingAdvice 15 "Not_available" ;
VAL_ 805 UsbPlayerOverload 0 "Consumption OK" 1 "Current limitation" ;
VAL_ 805 AudioStreamingErrorType 0 "None (no longitudinal control)" 1 "Command unavailable" 2 "No file available" 3 "Invalid" ;
VAL_ 805 AudioFileDetected 0 "File OK" 1 "No file" ;
VAL_ 805 UsbCommunicationError 0 "Communication OK" 1 "Communication error" ;
VAL_ 805 UsbDeviceIdentification 0 "Device recognized" 1 "Device not recognized" ;
VAL_ 805 UsbSourceInfo 0 "Undetermined" 1 "iPod" ;
VAL_ 805 BluetoothAccessInProgress 0 "Available" 1 "Access in progress" ;
VAL_ 805 UsbAccessInProgress 0 "Available" 1 "Access in progress" ;
VAL_ 805 BluetoothPlayerStatus 0 "Stop" 1 "Paused" 2 "Playing" 3 "Fast forward" 4 "Fast rewind" 5 "Disconnected" 6 "Unavailable" ;
VAL_ 805 UsbPlayerStatus 0 "Stop" 1 "Paused" 2 "Playing" 3 "Fast forward" 4 "Fast rewind" 5 "Disconnected" 6 "Unavailable" ;
VAL_ 805 AccessCd 0 "Available" 1 "Insert" 2 "Eject" 3 "Load" ;
VAL_ 805 CdPlayerStatus 0 "Disc absent" 1 "Stop" 2 "Paused" 3 "Playing" 4 "Fast forward" 5 "Fast rewind" ;
VAL_ 805 DiscType 0 "Audio CD" 1 "Data CD" ;
VAL_ 805 CdOverheating 0 "Normal temperature" 1 "Overheating" ;
VAL_ 805 DiskDirection 0 "No request" 1 "Ejection request not possible (disc upside-down)" ;
VAL_ 805 CdPlayerError 0 "Normal" 1 "Error" ;
VAL_ 805 DiscError 0 "Disc readable" 1 "Cannot read disc" ;
SG_MUL_VAL_ 705 SingleFrameLength IsoTpFrameType 0-0;
SG_MUL_VAL_ 705 FirstFrameLength IsoTpFrameType 1-1;
SG_MUL_VAL_ 705 ConsecutiveSequence IsoTpFrameType 2-2;
SG_MUL_VAL_ 705 FlowStatus IsoTpFrameType 3-3;
SG_MUL_VAL_ 705 UnknownPciLow IsoTpFrameType 4-15;
SG_MUL_VAL_ 705 BlockSize IsoTpFrameType 3-3;
SG_MUL_VAL_ 705 SingleData1 IsoTpFrameType 0-0;
SG_MUL_VAL_ 705 ConsecutiveData1 IsoTpFrameType 2-2;
SG_MUL_VAL_ 705 UnknownData1 IsoTpFrameType 4-15;
SG_MUL_VAL_ 705 SeparationTimeRaw IsoTpFrameType 3-3;
SG_MUL_VAL_ 705 SingleData2 IsoTpFrameType 0-0;
SG_MUL_VAL_ 705 ConsecutiveData2 IsoTpFrameType 2-2;
SG_MUL_VAL_ 705 UnknownData2 IsoTpFrameType 4-15;
SG_MUL_VAL_ 705 FirstData1 IsoTpFrameType 1-1;
SG_MUL_VAL_ 705 SingleData3 IsoTpFrameType 0-0;
SG_MUL_VAL_ 705 ConsecutiveData3 IsoTpFrameType 2-2;
SG_MUL_VAL_ 705 UnknownData3 IsoTpFrameType 4-15;
SG_MUL_VAL_ 705 FirstData2 IsoTpFrameType 1-1;
SG_MUL_VAL_ 705 FlowPadding1 IsoTpFrameType 3-3;
SG_MUL_VAL_ 705 SingleData4 IsoTpFrameType 0-0;
SG_MUL_VAL_ 705 ConsecutiveData4 IsoTpFrameType 2-2;
SG_MUL_VAL_ 705 UnknownData4 IsoTpFrameType 4-15;
SG_MUL_VAL_ 705 FirstData3 IsoTpFrameType 1-1;
SG_MUL_VAL_ 705 FlowPadding2 IsoTpFrameType 3-3;
SG_MUL_VAL_ 705 SingleData5 IsoTpFrameType 0-0;
SG_MUL_VAL_ 705 ConsecutiveData5 IsoTpFrameType 2-2;
SG_MUL_VAL_ 705 UnknownData5 IsoTpFrameType 4-15;
SG_MUL_VAL_ 705 FirstData4 IsoTpFrameType 1-1;
SG_MUL_VAL_ 705 FlowPadding3 IsoTpFrameType 3-3;
SG_MUL_VAL_ 705 SingleData6 IsoTpFrameType 0-0;
SG_MUL_VAL_ 705 ConsecutiveData6 IsoTpFrameType 2-2;
SG_MUL_VAL_ 705 UnknownData6 IsoTpFrameType 4-15;
SG_MUL_VAL_ 705 FirstData5 IsoTpFrameType 1-1;
SG_MUL_VAL_ 705 FlowPadding4 IsoTpFrameType 3-3;
SG_MUL_VAL_ 705 SingleData7 IsoTpFrameType 0-0;
SG_MUL_VAL_ 705 ConsecutiveData7 IsoTpFrameType 2-2;
SG_MUL_VAL_ 705 UnknownData7 IsoTpFrameType 4-15;
SG_MUL_VAL_ 705 FirstData6 IsoTpFrameType 1-1;
SG_MUL_VAL_ 705 FlowPadding5 IsoTpFrameType 3-3;
SG_MUL_VAL_ 709 SingleFrameLength IsoTpFrameType 0-0;
SG_MUL_VAL_ 709 FirstFrameLength IsoTpFrameType 1-1;
SG_MUL_VAL_ 709 ConsecutiveSequence IsoTpFrameType 2-2;
SG_MUL_VAL_ 709 FlowStatus IsoTpFrameType 3-3;
SG_MUL_VAL_ 709 UnknownPciLow IsoTpFrameType 4-15;
SG_MUL_VAL_ 709 BlockSize IsoTpFrameType 3-3;
SG_MUL_VAL_ 709 SingleData1 IsoTpFrameType 0-0;
SG_MUL_VAL_ 709 ConsecutiveData1 IsoTpFrameType 2-2;
SG_MUL_VAL_ 709 UnknownData1 IsoTpFrameType 4-15;
SG_MUL_VAL_ 709 SeparationTimeRaw IsoTpFrameType 3-3;
SG_MUL_VAL_ 709 SingleData2 IsoTpFrameType 0-0;
SG_MUL_VAL_ 709 ConsecutiveData2 IsoTpFrameType 2-2;
SG_MUL_VAL_ 709 UnknownData2 IsoTpFrameType 4-15;
SG_MUL_VAL_ 709 FirstData1 IsoTpFrameType 1-1;
SG_MUL_VAL_ 709 SingleData3 IsoTpFrameType 0-0;
SG_MUL_VAL_ 709 ConsecutiveData3 IsoTpFrameType 2-2;
SG_MUL_VAL_ 709 UnknownData3 IsoTpFrameType 4-15;
SG_MUL_VAL_ 709 FirstData2 IsoTpFrameType 1-1;
SG_MUL_VAL_ 709 FlowPadding1 IsoTpFrameType 3-3;
SG_MUL_VAL_ 709 SingleData4 IsoTpFrameType 0-0;
SG_MUL_VAL_ 709 ConsecutiveData4 IsoTpFrameType 2-2;
SG_MUL_VAL_ 709 UnknownData4 IsoTpFrameType 4-15;
SG_MUL_VAL_ 709 FirstData3 IsoTpFrameType 1-1;
SG_MUL_VAL_ 709 FlowPadding2 IsoTpFrameType 3-3;
SG_MUL_VAL_ 709 SingleData5 IsoTpFrameType 0-0;
SG_MUL_VAL_ 709 ConsecutiveData5 IsoTpFrameType 2-2;
SG_MUL_VAL_ 709 UnknownData5 IsoTpFrameType 4-15;
SG_MUL_VAL_ 709 FirstData4 IsoTpFrameType 1-1;
SG_MUL_VAL_ 709 FlowPadding3 IsoTpFrameType 3-3;
SG_MUL_VAL_ 709 SingleData6 IsoTpFrameType 0-0;
SG_MUL_VAL_ 709 ConsecutiveData6 IsoTpFrameType 2-2;
SG_MUL_VAL_ 709 UnknownData6 IsoTpFrameType 4-15;
SG_MUL_VAL_ 709 FirstData5 IsoTpFrameType 1-1;
SG_MUL_VAL_ 709 FlowPadding4 IsoTpFrameType 3-3;
SG_MUL_VAL_ 709 SingleData7 IsoTpFrameType 0-0;
SG_MUL_VAL_ 709 ConsecutiveData7 IsoTpFrameType 2-2;
SG_MUL_VAL_ 709 UnknownData7 IsoTpFrameType 4-15;
SG_MUL_VAL_ 709 FirstData6 IsoTpFrameType 1-1;
SG_MUL_VAL_ 709 FlowPadding5 IsoTpFrameType 3-3;
SG_MUL_VAL_ 724 SingleFrameLength IsoTpFrameType 0-0;
SG_MUL_VAL_ 724 FirstFrameLength IsoTpFrameType 1-1;
SG_MUL_VAL_ 724 ConsecutiveSequence IsoTpFrameType 2-2;
SG_MUL_VAL_ 724 FlowStatus IsoTpFrameType 3-3;
SG_MUL_VAL_ 724 UnknownPciLow IsoTpFrameType 4-15;
SG_MUL_VAL_ 724 BlockSize IsoTpFrameType 3-3;
SG_MUL_VAL_ 724 SingleData1 IsoTpFrameType 0-0;
SG_MUL_VAL_ 724 ConsecutiveData1 IsoTpFrameType 2-2;
SG_MUL_VAL_ 724 UnknownData1 IsoTpFrameType 4-15;
SG_MUL_VAL_ 724 SeparationTimeRaw IsoTpFrameType 3-3;
SG_MUL_VAL_ 724 SingleData2 IsoTpFrameType 0-0;
SG_MUL_VAL_ 724 ConsecutiveData2 IsoTpFrameType 2-2;
SG_MUL_VAL_ 724 UnknownData2 IsoTpFrameType 4-15;
SG_MUL_VAL_ 724 FirstData1 IsoTpFrameType 1-1;
SG_MUL_VAL_ 724 SingleData3 IsoTpFrameType 0-0;
SG_MUL_VAL_ 724 ConsecutiveData3 IsoTpFrameType 2-2;
SG_MUL_VAL_ 724 UnknownData3 IsoTpFrameType 4-15;
SG_MUL_VAL_ 724 FirstData2 IsoTpFrameType 1-1;
SG_MUL_VAL_ 724 FlowPadding1 IsoTpFrameType 3-3;
SG_MUL_VAL_ 724 SingleData4 IsoTpFrameType 0-0;
SG_MUL_VAL_ 724 ConsecutiveData4 IsoTpFrameType 2-2;
SG_MUL_VAL_ 724 UnknownData4 IsoTpFrameType 4-15;
SG_MUL_VAL_ 724 FirstData3 IsoTpFrameType 1-1;
SG_MUL_VAL_ 724 FlowPadding2 IsoTpFrameType 3-3;
SG_MUL_VAL_ 724 SingleData5 IsoTpFrameType 0-0;
SG_MUL_VAL_ 724 ConsecutiveData5 IsoTpFrameType 2-2;
SG_MUL_VAL_ 724 UnknownData5 IsoTpFrameType 4-15;
SG_MUL_VAL_ 724 FirstData4 IsoTpFrameType 1-1;
SG_MUL_VAL_ 724 FlowPadding3 IsoTpFrameType 3-3;
SG_MUL_VAL_ 724 SingleData6 IsoTpFrameType 0-0;
SG_MUL_VAL_ 724 ConsecutiveData6 IsoTpFrameType 2-2;
SG_MUL_VAL_ 724 UnknownData6 IsoTpFrameType 4-15;
SG_MUL_VAL_ 724 FirstData5 IsoTpFrameType 1-1;
SG_MUL_VAL_ 724 FlowPadding4 IsoTpFrameType 3-3;
SG_MUL_VAL_ 724 SingleData7 IsoTpFrameType 0-0;
SG_MUL_VAL_ 724 ConsecutiveData7 IsoTpFrameType 2-2;
SG_MUL_VAL_ 724 UnknownData7 IsoTpFrameType 4-15;
SG_MUL_VAL_ 724 FirstData6 IsoTpFrameType 1-1;
SG_MUL_VAL_ 724 FlowPadding5 IsoTpFrameType 3-3;
SG_MUL_VAL_ 732 SingleFrameLength IsoTpFrameType 0-0;
SG_MUL_VAL_ 732 FirstFrameLength IsoTpFrameType 1-1;
SG_MUL_VAL_ 732 ConsecutiveSequence IsoTpFrameType 2-2;
SG_MUL_VAL_ 732 FlowStatus IsoTpFrameType 3-3;
SG_MUL_VAL_ 732 UnknownPciLow IsoTpFrameType 4-15;
SG_MUL_VAL_ 732 BlockSize IsoTpFrameType 3-3;
SG_MUL_VAL_ 732 SingleData1 IsoTpFrameType 0-0;
SG_MUL_VAL_ 732 ConsecutiveData1 IsoTpFrameType 2-2;
SG_MUL_VAL_ 732 UnknownData1 IsoTpFrameType 4-15;
SG_MUL_VAL_ 732 SeparationTimeRaw IsoTpFrameType 3-3;
SG_MUL_VAL_ 732 SingleData2 IsoTpFrameType 0-0;
SG_MUL_VAL_ 732 ConsecutiveData2 IsoTpFrameType 2-2;
SG_MUL_VAL_ 732 UnknownData2 IsoTpFrameType 4-15;
SG_MUL_VAL_ 732 FirstData1 IsoTpFrameType 1-1;
SG_MUL_VAL_ 732 SingleData3 IsoTpFrameType 0-0;
SG_MUL_VAL_ 732 ConsecutiveData3 IsoTpFrameType 2-2;
SG_MUL_VAL_ 732 UnknownData3 IsoTpFrameType 4-15;
SG_MUL_VAL_ 732 FirstData2 IsoTpFrameType 1-1;
SG_MUL_VAL_ 732 FlowPadding1 IsoTpFrameType 3-3;
SG_MUL_VAL_ 732 SingleData4 IsoTpFrameType 0-0;
SG_MUL_VAL_ 732 ConsecutiveData4 IsoTpFrameType 2-2;
SG_MUL_VAL_ 732 UnknownData4 IsoTpFrameType 4-15;
SG_MUL_VAL_ 732 FirstData3 IsoTpFrameType 1-1;
SG_MUL_VAL_ 732 FlowPadding2 IsoTpFrameType 3-3;
SG_MUL_VAL_ 732 SingleData5 IsoTpFrameType 0-0;
SG_MUL_VAL_ 732 ConsecutiveData5 IsoTpFrameType 2-2;
SG_MUL_VAL_ 732 UnknownData5 IsoTpFrameType 4-15;
SG_MUL_VAL_ 732 FirstData4 IsoTpFrameType 1-1;
SG_MUL_VAL_ 732 FlowPadding3 IsoTpFrameType 3-3;
SG_MUL_VAL_ 732 SingleData6 IsoTpFrameType 0-0;
SG_MUL_VAL_ 732 ConsecutiveData6 IsoTpFrameType 2-2;
SG_MUL_VAL_ 732 UnknownData6 IsoTpFrameType 4-15;
SG_MUL_VAL_ 732 FirstData5 IsoTpFrameType 1-1;
SG_MUL_VAL_ 732 FlowPadding4 IsoTpFrameType 3-3;
SG_MUL_VAL_ 732 SingleData7 IsoTpFrameType 0-0;
SG_MUL_VAL_ 732 ConsecutiveData7 IsoTpFrameType 2-2;
SG_MUL_VAL_ 732 UnknownData7 IsoTpFrameType 4-15;
SG_MUL_VAL_ 732 FirstData6 IsoTpFrameType 1-1;
SG_MUL_VAL_ 732 FlowPadding5 IsoTpFrameType 3-3;
SG_MUL_VAL_ 735 SingleFrameLength IsoTpFrameType 0-0;
SG_MUL_VAL_ 735 FirstFrameLength IsoTpFrameType 1-1;
SG_MUL_VAL_ 735 ConsecutiveSequence IsoTpFrameType 2-2;
SG_MUL_VAL_ 735 FlowStatus IsoTpFrameType 3-3;
SG_MUL_VAL_ 735 UnknownPciLow IsoTpFrameType 4-15;
SG_MUL_VAL_ 735 BlockSize IsoTpFrameType 3-3;
SG_MUL_VAL_ 735 SingleData1 IsoTpFrameType 0-0;
SG_MUL_VAL_ 735 ConsecutiveData1 IsoTpFrameType 2-2;
SG_MUL_VAL_ 735 UnknownData1 IsoTpFrameType 4-15;
SG_MUL_VAL_ 735 SeparationTimeRaw IsoTpFrameType 3-3;
SG_MUL_VAL_ 735 SingleData2 IsoTpFrameType 0-0;
SG_MUL_VAL_ 735 ConsecutiveData2 IsoTpFrameType 2-2;
SG_MUL_VAL_ 735 UnknownData2 IsoTpFrameType 4-15;
SG_MUL_VAL_ 735 FirstData1 IsoTpFrameType 1-1;
SG_MUL_VAL_ 735 SingleData3 IsoTpFrameType 0-0;
SG_MUL_VAL_ 735 ConsecutiveData3 IsoTpFrameType 2-2;
SG_MUL_VAL_ 735 UnknownData3 IsoTpFrameType 4-15;
SG_MUL_VAL_ 735 FirstData2 IsoTpFrameType 1-1;
SG_MUL_VAL_ 735 FlowPadding1 IsoTpFrameType 3-3;
SG_MUL_VAL_ 735 SingleData4 IsoTpFrameType 0-0;
SG_MUL_VAL_ 735 ConsecutiveData4 IsoTpFrameType 2-2;
SG_MUL_VAL_ 735 UnknownData4 IsoTpFrameType 4-15;
SG_MUL_VAL_ 735 FirstData3 IsoTpFrameType 1-1;
SG_MUL_VAL_ 735 FlowPadding2 IsoTpFrameType 3-3;
SG_MUL_VAL_ 735 SingleData5 IsoTpFrameType 0-0;
SG_MUL_VAL_ 735 ConsecutiveData5 IsoTpFrameType 2-2;
SG_MUL_VAL_ 735 UnknownData5 IsoTpFrameType 4-15;
SG_MUL_VAL_ 735 FirstData4 IsoTpFrameType 1-1;
SG_MUL_VAL_ 735 FlowPadding3 IsoTpFrameType 3-3;
SG_MUL_VAL_ 735 SingleData6 IsoTpFrameType 0-0;
SG_MUL_VAL_ 735 ConsecutiveData6 IsoTpFrameType 2-2;
SG_MUL_VAL_ 735 UnknownData6 IsoTpFrameType 4-15;
SG_MUL_VAL_ 735 FirstData5 IsoTpFrameType 1-1;
SG_MUL_VAL_ 735 FlowPadding4 IsoTpFrameType 3-3;
SG_MUL_VAL_ 735 SingleData7 IsoTpFrameType 0-0;
SG_MUL_VAL_ 735 ConsecutiveData7 IsoTpFrameType 2-2;
SG_MUL_VAL_ 735 UnknownData7 IsoTpFrameType 4-15;
SG_MUL_VAL_ 735 FirstData6 IsoTpFrameType 1-1;
SG_MUL_VAL_ 735 FlowPadding5 IsoTpFrameType 3-3;
SG_MUL_VAL_ 773 SingleFrameLength IsoTpFrameType 0-0;
SG_MUL_VAL_ 773 FirstFrameLength IsoTpFrameType 1-1;
SG_MUL_VAL_ 773 ConsecutiveSequence IsoTpFrameType 2-2;
SG_MUL_VAL_ 773 FlowStatus IsoTpFrameType 3-3;
SG_MUL_VAL_ 773 UnknownPciLow IsoTpFrameType 4-15;
SG_MUL_VAL_ 773 BlockSize IsoTpFrameType 3-3;
SG_MUL_VAL_ 773 SingleData1 IsoTpFrameType 0-0;
SG_MUL_VAL_ 773 ConsecutiveData1 IsoTpFrameType 2-2;
SG_MUL_VAL_ 773 UnknownData1 IsoTpFrameType 4-15;
SG_MUL_VAL_ 773 SeparationTimeRaw IsoTpFrameType 3-3;
SG_MUL_VAL_ 773 SingleData2 IsoTpFrameType 0-0;
SG_MUL_VAL_ 773 ConsecutiveData2 IsoTpFrameType 2-2;
SG_MUL_VAL_ 773 UnknownData2 IsoTpFrameType 4-15;
SG_MUL_VAL_ 773 FirstData1 IsoTpFrameType 1-1;
SG_MUL_VAL_ 773 SingleData3 IsoTpFrameType 0-0;
SG_MUL_VAL_ 773 ConsecutiveData3 IsoTpFrameType 2-2;
SG_MUL_VAL_ 773 UnknownData3 IsoTpFrameType 4-15;
SG_MUL_VAL_ 773 FirstData2 IsoTpFrameType 1-1;
SG_MUL_VAL_ 773 FlowPadding1 IsoTpFrameType 3-3;
SG_MUL_VAL_ 773 SingleData4 IsoTpFrameType 0-0;
SG_MUL_VAL_ 773 ConsecutiveData4 IsoTpFrameType 2-2;
SG_MUL_VAL_ 773 UnknownData4 IsoTpFrameType 4-15;
SG_MUL_VAL_ 773 FirstData3 IsoTpFrameType 1-1;
SG_MUL_VAL_ 773 FlowPadding2 IsoTpFrameType 3-3;
SG_MUL_VAL_ 773 SingleData5 IsoTpFrameType 0-0;
SG_MUL_VAL_ 773 ConsecutiveData5 IsoTpFrameType 2-2;
SG_MUL_VAL_ 773 UnknownData5 IsoTpFrameType 4-15;
SG_MUL_VAL_ 773 FirstData4 IsoTpFrameType 1-1;
SG_MUL_VAL_ 773 FlowPadding3 IsoTpFrameType 3-3;
SG_MUL_VAL_ 773 SingleData6 IsoTpFrameType 0-0;
SG_MUL_VAL_ 773 ConsecutiveData6 IsoTpFrameType 2-2;
SG_MUL_VAL_ 773 UnknownData6 IsoTpFrameType 4-15;
SG_MUL_VAL_ 773 FirstData5 IsoTpFrameType 1-1;
SG_MUL_VAL_ 773 FlowPadding4 IsoTpFrameType 3-3;
SG_MUL_VAL_ 773 SingleData7 IsoTpFrameType 0-0;
SG_MUL_VAL_ 773 ConsecutiveData7 IsoTpFrameType 2-2;
SG_MUL_VAL_ 773 UnknownData7 IsoTpFrameType 4-15;
SG_MUL_VAL_ 773 FirstData6 IsoTpFrameType 1-1;
SG_MUL_VAL_ 773 FlowPadding5 IsoTpFrameType 3-3;
SG_MUL_VAL_ 788 SingleFrameLength IsoTpFrameType 0-0;
SG_MUL_VAL_ 788 FirstFrameLength IsoTpFrameType 1-1;
SG_MUL_VAL_ 788 ConsecutiveSequence IsoTpFrameType 2-2;
SG_MUL_VAL_ 788 FlowStatus IsoTpFrameType 3-3;
SG_MUL_VAL_ 788 UnknownPciLow IsoTpFrameType 4-15;
SG_MUL_VAL_ 788 BlockSize IsoTpFrameType 3-3;
SG_MUL_VAL_ 788 SingleData1 IsoTpFrameType 0-0;
SG_MUL_VAL_ 788 ConsecutiveData1 IsoTpFrameType 2-2;
SG_MUL_VAL_ 788 UnknownData1 IsoTpFrameType 4-15;
SG_MUL_VAL_ 788 SeparationTimeRaw IsoTpFrameType 3-3;
SG_MUL_VAL_ 788 SingleData2 IsoTpFrameType 0-0;
SG_MUL_VAL_ 788 ConsecutiveData2 IsoTpFrameType 2-2;
SG_MUL_VAL_ 788 UnknownData2 IsoTpFrameType 4-15;
SG_MUL_VAL_ 788 FirstData1 IsoTpFrameType 1-1;
SG_MUL_VAL_ 788 SingleData3 IsoTpFrameType 0-0;
SG_MUL_VAL_ 788 ConsecutiveData3 IsoTpFrameType 2-2;
SG_MUL_VAL_ 788 UnknownData3 IsoTpFrameType 4-15;
SG_MUL_VAL_ 788 FirstData2 IsoTpFrameType 1-1;
SG_MUL_VAL_ 788 FlowPadding1 IsoTpFrameType 3-3;
SG_MUL_VAL_ 788 SingleData4 IsoTpFrameType 0-0;
SG_MUL_VAL_ 788 ConsecutiveData4 IsoTpFrameType 2-2;
SG_MUL_VAL_ 788 UnknownData4 IsoTpFrameType 4-15;
SG_MUL_VAL_ 788 FirstData3 IsoTpFrameType 1-1;
SG_MUL_VAL_ 788 FlowPadding2 IsoTpFrameType 3-3;
SG_MUL_VAL_ 788 SingleData5 IsoTpFrameType 0-0;
SG_MUL_VAL_ 788 ConsecutiveData5 IsoTpFrameType 2-2;
SG_MUL_VAL_ 788 UnknownData5 IsoTpFrameType 4-15;
SG_MUL_VAL_ 788 FirstData4 IsoTpFrameType 1-1;
SG_MUL_VAL_ 788 FlowPadding3 IsoTpFrameType 3-3;
SG_MUL_VAL_ 788 SingleData6 IsoTpFrameType 0-0;
SG_MUL_VAL_ 788 ConsecutiveData6 IsoTpFrameType 2-2;
SG_MUL_VAL_ 788 UnknownData6 IsoTpFrameType 4-15;
SG_MUL_VAL_ 788 FirstData5 IsoTpFrameType 1-1;
SG_MUL_VAL_ 788 FlowPadding4 IsoTpFrameType 3-3;
SG_MUL_VAL_ 788 SingleData7 IsoTpFrameType 0-0;
SG_MUL_VAL_ 788 ConsecutiveData7 IsoTpFrameType 2-2;
SG_MUL_VAL_ 788 UnknownData7 IsoTpFrameType 4-15;
SG_MUL_VAL_ 788 FirstData6 IsoTpFrameType 1-1;
SG_MUL_VAL_ 788 FlowPadding5 IsoTpFrameType 3-3;
